VERSION ""

NS_ :

BS_:

BU_: Turbocharger OnBoardDataLogger OffBoardDiagnosticTool2 OffBoardDiagnosticTool1 FileServer ParkingBrakeController SeatControl2 FanDriveController SteeringColumnUnit CommunicationUnitRadio CommunicationUnitSatellite CommunicationUnitCellular PropulsionBatteryCharger ChassisController2 ChassisController1 EngineValveControl AuxiliaryHeater2 AuxiliaryHeater1 ClutchUnit RampControl InformationSystem1 SuspensionSystemController2 OilSensor VehicleDynamicStability ExhaustEmissionController TransmissionDisplay2 TransmissionDisplay1 ClimateControl2 WaterPumpController RearAxleSteeringController LightingOperatorControl SeatController1 IgnitionController2 IgnitionController1 TirePressureController CabController2 CabController1 PneumaticSystemController SuspensionSystemController1 HydraulicPumpController EnduranceBrakingSystem RetarderExhaustEngine2 OnBoardDiagnosticUnit HeadwayController RetarderExhaustEngine1 CabDisplay1 ManagementComputer VirtualTerminal OffVehicleGateway PowerTakeOffFront HitchControl AuxiliaryValveControl BodyController TractorTrailerBridge1 StarterSystem ElectricalSystem VehicleSecurity VehicleNavigation AerodynamicControl ElectricalChargingSystem ClimateControl1 TripRecorder InstrumentCluster SuspensionDriveAxle2 SuspensionDriveAxle1 SuspensionSteerAxle SteeringController FuelSystem CruiseControl RetarderDriveline RetarderEngine BrakesDriveAxle2 BrakesDriveAxle1 BrakesSystemController BrakesSteerAxle AxleDrive2 AxleDrive1 AxleSteering PowerTakeOff ShiftConsoleSecondary ShiftConsolePrimary Transmission2 Transmission1 Engine2 Engine1

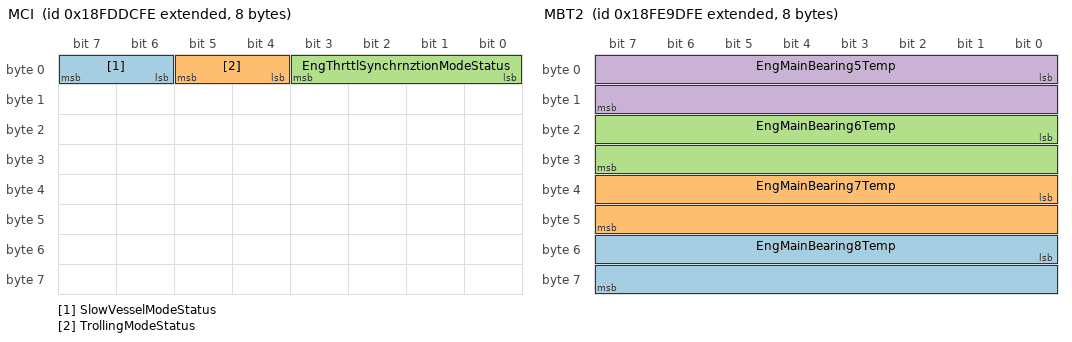
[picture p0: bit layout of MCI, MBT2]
BO_ 2566774014 MCI: 8 Vector__XXX
 SG_ SlowVesselModeStatus : 6|2@1+ (1,0) [0|3] "" Vector__XXX
 SG_ TrollingModeStatus : 4|2@1+ (1,0) [0|3] "" Vector__XXX
 SG_ EngThrttlSynchrnztionModeStatus : 0|4@1+ (1,0) [0|15] "" Vector__XXX

BO_ 2566823166 MBT3: 8 Vector__XXX
 SG_ EngMainBearing11Temp : 32|16@1+ (0.03125,-273) [-273|1734.96875] "deg C" Vector__XXX
 SG_ EngMainBearing10Temp : 16|16@1+ (0.03125,-273) [-273|1734.96875] "deg C" Vector__XXX
 SG_ EngMainBearing9Temp : 0|16@1+ (0.03125,-273) [-273|1734.96875] "deg C" Vector__XXX

BO_ 2566823422 MBT2: 8 Vector__XXX
 SG_ EngMainBearing8Temp : 48|16@1+ (0.03125,-273) [-273|1734.96875] "deg C" Vector__XXX
 SG_ EngMainBearing7Temp : 32|16@1+ (0.03125,-273) [-273|1734.96875] "deg C" Vector__XXX
 SG_ EngMainBearing6Temp : 16|16@1+ (0.03125,-273) [-273|1734.96875] "deg C" Vector__XXX
 SG_ EngMainBearing5Temp : 0|16@1+ (0.03125,-273) [-273|1734.96875] "deg C" Vector__XXX

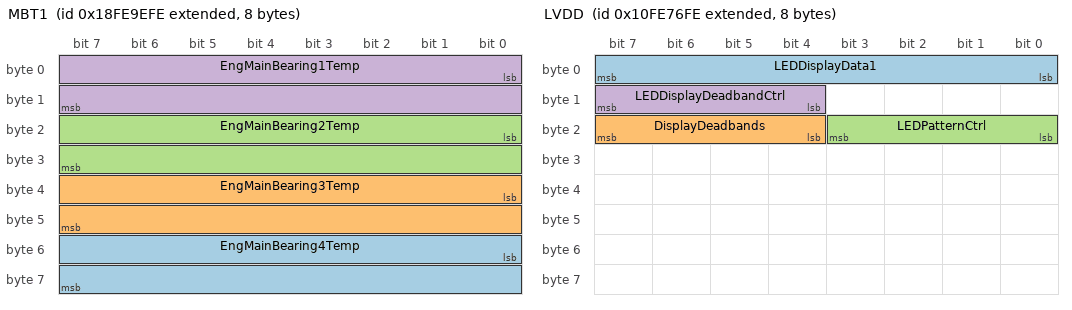
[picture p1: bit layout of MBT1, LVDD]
BO_ 2566823678 MBT1: 8 Vector__XXX
 SG_ EngMainBearing4Temp : 48|16@1+ (0.03125,-273) [-273|1734.96875] "deg C" Vector__XXX
 SG_ EngMainBearing3Temp : 32|16@1+ (0.03125,-273) [-273|1734.96875] "deg C" Vector__XXX
 SG_ EngMainBearing2Temp : 16|16@1+ (0.03125,-273) [-273|1734.96875] "deg C" Vector__XXX
 SG_ EngMainBearing1Temp : 0|16@1+ (0.03125,-273) [-273|1734.96875] "deg C" Vector__XXX

BO_ 2432595710 LVDD: 8 Vector__XXX
 SG_ LEDDisplayData1 : 0|8@1+ (1,0) [0|255] "" Vector__XXX
 SG_ DisplayDeadbands : 20|4@1+ (1,0) [0|15] "" Vector__XXX
 SG_ LEDPatternCtrl : 16|4@1+ (1,0) [0|15] "" Vector__XXX
 SG_ LEDDisplayDeadbandCtrl : 12|4@1+ (1,0) [0|15] "" Vector__XXX

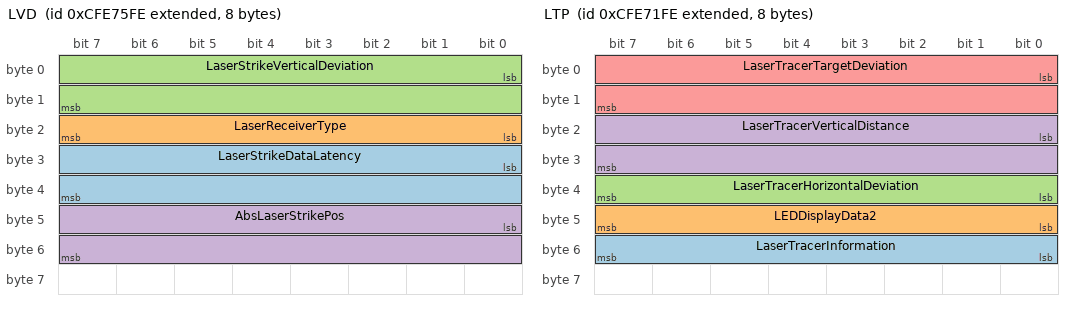
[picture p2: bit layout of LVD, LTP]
BO_ 2365486590 LVD: 8 Vector__XXX
 SG_ LaserStrikeDataLatency : 24|16@1+ (51.2,0) [0|3.289856] "s" Vector__XXX
 SG_ LaserReceiverType : 16|8@1+ (1,0) [0|250] "" Vector__XXX
 SG_ LaserStrikeVerticalDeviation : 0|16@1+ (0.1,-3200) [-3200|3225.5] "mm" Vector__XXX
 SG_ AbsLaserStrikePos : 40|16@1+ (0.1,0) [0|6425.5] "mm" Vector__XXX

BO_ 2365485566 LTP: 8 Vector__XXX
 SG_ LaserTracerInformation : 48|8@1+ (1,0) [0|255] "" Vector__XXX
 SG_ LEDDisplayData2 : 40|8@1+ (1,0) [0|255] "" Vector__XXX
 SG_ LaserTracerHorizontalDeviation : 32|8@1+ (1,0) [0|250] "%" Vector__XXX
 SG_ LaserTracerVerticalDistance : 16|16@1+ (0.1,0) [0|6425.5] "mm" Vector__XXX
 SG_ LaserTracerTargetDeviation : 0|16@1+ (0.1,-3200) [-3200|3225.5] "mm" Vector__XXX

BO_ 2365486334 LSP: 8 Vector__XXX
 SG_ BldHeightSetPointHighResolution : 16|32@1+ (100,-209.7152) [-209.7152|211.3929215] "m" Vector__XXX
 SG_ ModifyLevelingSystemSetPoint : 0|16@1+ (0.1,-3200) [-3200|3225.5] "mm" Vector__XXX

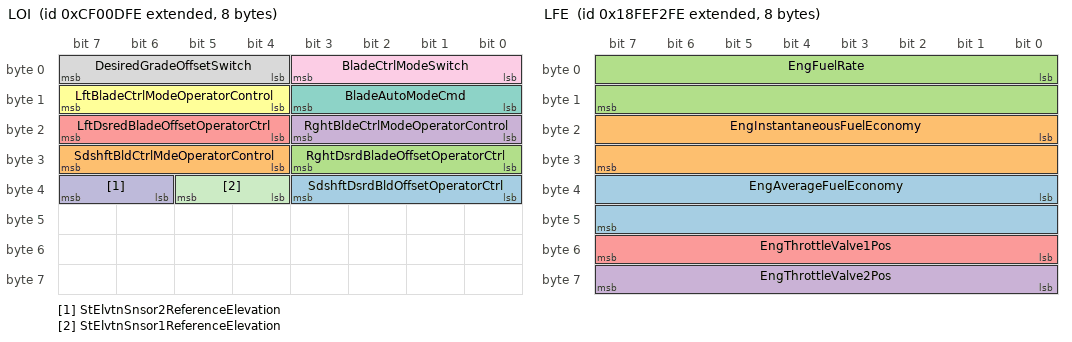
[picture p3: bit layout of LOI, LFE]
BO_ 2364542462 LOI: 8 Vector__XXX
 SG_ SdshftDsrdBldOffsetOperatorCtrl : 32|4@1+ (1,0) [0|15] "" Vector__XXX
 SG_ SdshftBldCtrlMdeOperatorControl : 28|4@1+ (1,0) [0|15] "" Vector__XXX
 SG_ RghtDsrdBladeOffsetOperatorCtrl : 24|4@1+ (1,0) [0|15] "" Vector__XXX
 SG_ RghtBldeCtrlModeOperatorControl : 16|4@1+ (1,0) [0|15] "" Vector__XXX
 SG_ LftDsredBladeOffsetOperatorCtrl : 20|4@1+ (1,0) [0|15] "" Vector__XXX
 SG_ LftBladeCtrlModeOperatorControl : 12|4@1+ (1,0) [0|15] "" Vector__XXX
 SG_ BladeAutoModeCmd : 8|4@1+ (1,0) [0|15] "" Vector__XXX
 SG_ DesiredGradeOffsetSwitch : 4|4@1+ (1,0) [0|15] "" Vector__XXX
 SG_ BladeCtrlModeSwitch : 0|4@1+ (1,0) [0|15] "" Vector__XXX
 SG_ StElvtnSnsor2ReferenceElevation : 38|2@1+ (1,0) [0|3] "" Vector__XXX
 SG_ StElvtnSnsor1ReferenceElevation : 36|2@1+ (1,0) [0|3] "" Vector__XXX

BO_ 2365486078 LMP: 8 Vector__XXX
 SG_ MastPos : 0|16@1+ (0.1,-3200) [-3200|3225.5] "mm" Vector__XXX

BO_ 2633937918 LFI: 8 Vector__XXX
 SG_ TotalEngPTOGovernorFuelUsed : 0|32@1+ (0.5,0) [0|2105540607.5] "L" Vector__XXX
 SG_ TripAverageFuelRate : 32|16@1+ (0.05,0) [0|3212.75] "L/h" Vector__XXX
 SG_ FlexibleFuelPercentage : 48|10@1+ (0.1,0) [0|102] "%" Vector__XXX

BO_ 2566845182 LFE: 8 Vector__XXX
 SG_ EngAverageFuelEconomy : 32|16@1+ (0.001953125,0) [0|125.5] "km/L" Vector__XXX
 SG_ EngInstantaneousFuelEconomy : 16|16@1+ (0.001953125,0) [0|125.5] "km/L" Vector__XXX
 SG_ EngFuelRate : 0|16@1+ (0.05,0) [0|3212.75] "L/h" Vector__XXX
 SG_ EngThrottleValve2Pos : 56|8@1+ (0.4,0) [0|100] "%" Vector__XXX
 SG_ EngThrottleValve1Pos : 48|8@1+ (0.4,0) [0|100] "%" Vector__XXX

BO_ 2566842878 LFC: 8 Vector__XXX
 SG_ EngTotalFuelUsed : 32|32@1+ (0.5,0) [0|2105540607.5] "L" Vector__XXX
 SG_ EngTripFuel : 0|32@1+ (0.5,0) [0|2105540607.5] "L" Vector__XXX

BO_ 2633883646 FWD: 8 Vector__XXX
 SG_ FrontWheelDriveActuatorStatus : 0|2@1+ (1,0) [0|3] "" Vector__XXX

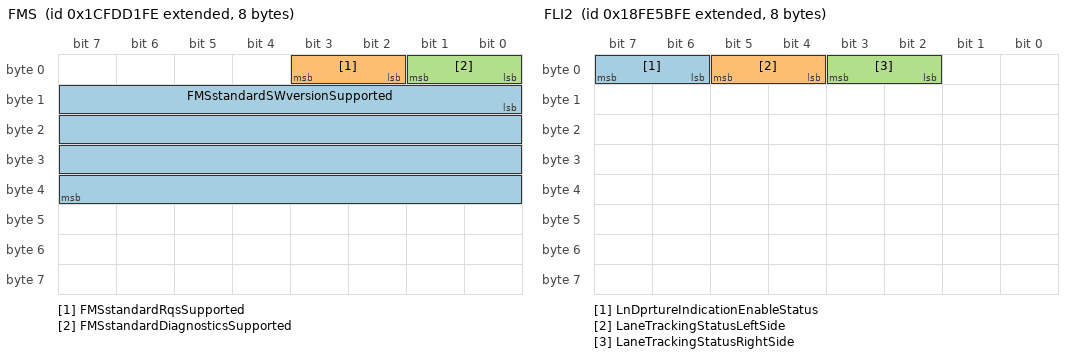
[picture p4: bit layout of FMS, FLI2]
BO_ 2633880062 FMS: 8 Vector__XXX
 SG_ FMSstandardSWversionSupported : 8|32@1+ (1,0) [0|255] "per" Vector__XXX
 SG_ FMSstandardRqsSupported : 2|2@1+ (1,0) [0|3] "" Vector__XXX
 SG_ FMSstandardDiagnosticsSupported : 0|2@1+ (1,0) [0|3] "" Vector__XXX

BO_ 2566806526 FLI2: 8 Vector__XXX
 SG_ LnDprtureIndicationEnableStatus : 6|2@1+ (1,0) [0|3] "" Vector__XXX
 SG_ LaneTrackingStatusLeftSide : 4|2@1+ (1,0) [0|3] "" Vector__XXX
 SG_ LaneTrackingStatusRightSide : 2|2@1+ (1,0) [0|3] "" Vector__XXX

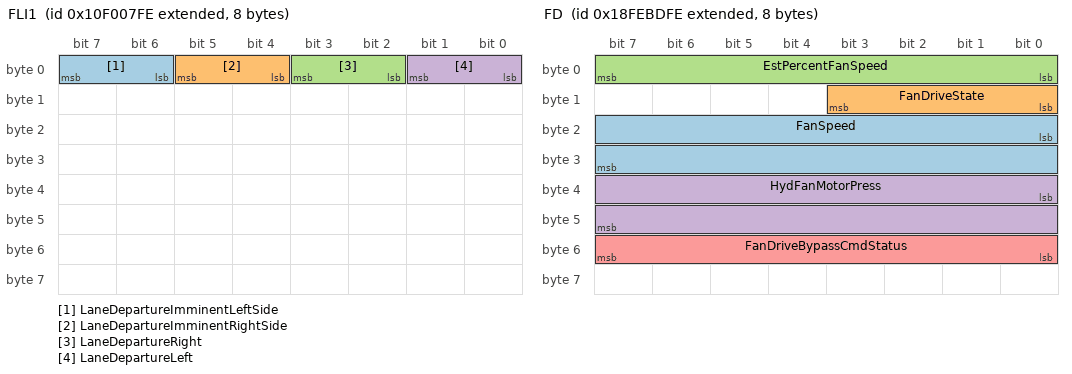
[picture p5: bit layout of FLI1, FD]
BO_ 2431649790 FLI1: 8 Vector__XXX
 SG_ LaneDepartureImminentLeftSide : 6|2@1+ (1,0) [0|3] "" Vector__XXX
 SG_ LaneDepartureImminentRightSide : 4|2@1+ (1,0) [0|3] "" Vector__XXX
 SG_ LaneDepartureRight : 2|2@1+ (1,0) [0|3] "" Vector__XXX
 SG_ LaneDepartureLeft : 0|2@1+ (1,0) [0|3] "" Vector__XXX

BO_ 2633929214 FL: 8 Vector__XXX
 SG_ EngFuelLeakage2 : 2|2@1+ (1,0) [0|3] "" Vector__XXX
 SG_ EngFuelLeakage1 : 0|2@1+ (1,0) [0|3] "" Vector__XXX

BO_ 2566831614 FD: 8 Vector__XXX
 SG_ FanSpeed : 16|16@1+ (0.125,0) [0|8031.875] "rpm" Vector__XXX
 SG_ FanDriveState : 8|4@1+ (1,0) [0|15] "" Vector__XXX
 SG_ EstPercentFanSpeed : 0|8@1+ (0.4,0) [0|100] "%" Vector__XXX
 SG_ HydFanMotorPress : 32|16@1+ (0.5,0) [0|32127.5] "kPa" Vector__XXX
 SG_ FanDriveBypassCmdStatus : 48|8@1+ (0.4,0) [0|100] "%" Vector__XXX

BO_ 2364542206 ETC8: 8 Vector__XXX
 SG_ TransClutch_ConverterInputSpeed : 16|16@1+ (0.125,0) [0|8031.875] "rpm" Vector__XXX
 SG_ TransTorqueConverterRatio : 0|16@1+ (0.001,0) [0|64.255] "" Vector__XXX

BO_ 2566802174 ETC7: 8 Vector__XXX
 SG_ TrnsRvrseGearShiftInhibitStatus : 40|2@1+ (1,0) [0|3] "" Vector__XXX
 SG_ TrnsCrrntRangeDisplayBlankState : 0|2@1+ (1,0) [0|3] "" Vector__XXX
 SG_ TransWarningIndicator : 42|2@1+ (1,0) [0|3] "" Vector__XXX
 SG_ TransMode8Indicator : 38|2@1+ (1,0) [0|3] "" Vector__XXX
 SG_ TransMode7Indicator : 36|2@1+ (1,0) [0|3] "" Vector__XXX
 SG_ TransMode6Indicator : 34|2@1+ (1,0) [0|3] "" Vector__XXX
 SG_ TransMode5Indicator : 32|2@1+ (1,0) [0|3] "" Vector__XXX
 SG_ TransRqedGearFeedback : 24|8@1+ (1,-125) [-125|125] "" Vector__XXX
 SG_ TransMode1Indicator : 22|2@1+ (1,0) [0|3] "" Vector__XXX
 SG_ TransMode2Indicator : 20|2@1+ (1,0) [0|3] "" Vector__XXX
 SG_ TransMode3Indicator : 18|2@1+ (1,0) [0|3] "" Vector__XXX
 SG_ TransMode4Indicator : 16|2@1+ (1,0) [0|3] "" Vector__XXX
 SG_ TransShiftInhibitIndicator : 14|2@1+ (1,0) [0|3] "" Vector__XXX
 SG_ TransEngCrankEnable : 12|2@1+ (1,0) [0|3] "" Vector__XXX
 SG_ ActiveShiftConsoleIndicator : 10|2@1+ (1,0) [0|3] "" Vector__XXX
 SG_ TransReadyForBrakeRelease : 8|2@1+ (1,0) [0|3] "" Vector__XXX
 SG_ TransRqedRangeDisplayFlashState : 6|2@1+ (1,0) [0|3] "" Vector__XXX
 SG_ TransRqedRangeDisplayBlankState : 4|2@1+ (1,0) [0|3] "" Vector__XXX
 SG_ TransServiceIndicator : 2|2@1+ (1,0) [0|3] "" Vector__XXX

BO_ 2633935870 ETC6: 8 Vector__XXX
 SG_ ClutchLifeRemaining : 24|8@1+ (0.4,0) [0|100] "%" Vector__XXX
 SG_ LowestPossibleGear : 16|8@1+ (1,-125) [-125|125] "" Vector__XXX
 SG_ HighestPossibleGear : 8|8@1+ (1,-125) [-125|125] "" Vector__XXX
 SG_ RecommendedGear : 0|8@1+ (1,-125) [-125|125] "" Vector__XXX

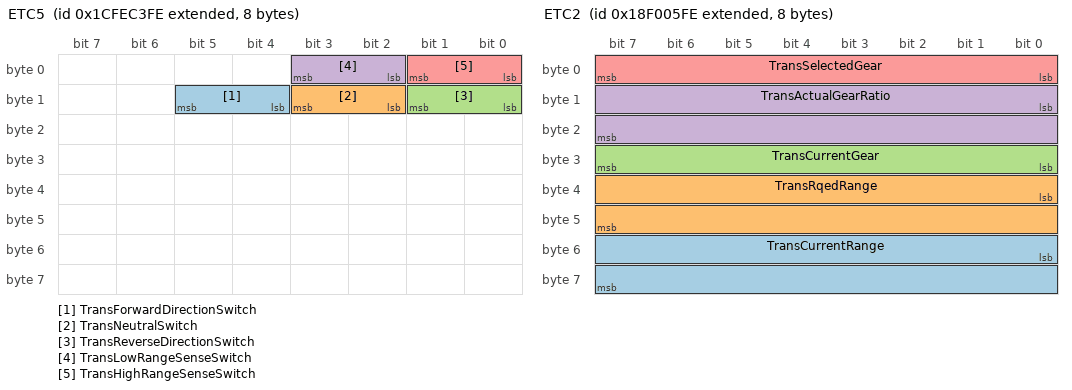
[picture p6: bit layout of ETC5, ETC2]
BO_ 2633942014 ETC5: 8 Vector__XXX
 SG_ TransForwardDirectionSwitch : 12|2@1+ (1,0) [0|3] "" Vector__XXX
 SG_ TransNeutralSwitch : 10|2@1+ (1,0) [0|3] "" Vector__XXX
 SG_ TransReverseDirectionSwitch : 8|2@1+ (1,0) [0|3] "" Vector__XXX
 SG_ TransLowRangeSenseSwitch : 2|2@1+ (1,0) [0|3] "" Vector__XXX
 SG_ TransHighRangeSenseSwitch : 0|2@1+ (1,0) [0|3] "" Vector__XXX

BO_ 2633942526 ETC4: 8 Vector__XXX
 SG_ TransSynchronizerBrakeValue : 8|8@1+ (0.4,0) [0|100] "%" Vector__XXX
 SG_ TransSynchronizerClutchValue : 0|8@1+ (0.4,0) [0|100] "%" Vector__XXX

BO_ 2633943038 ETC3: 8 Vector__XXX
 SG_ TransInertiaBrakeActuator : 46|2@1+ (1,0) [0|3] "" Vector__XXX
 SG_ TransDefuelActuator : 44|2@1+ (1,0) [0|3] "" Vector__XXX
 SG_ TransLockupClutchActuator : 42|2@1+ (1,0) [0|3] "" Vector__XXX
 SG_ TransClutchActuator : 40|2@1+ (1,0) [0|3] "" Vector__XXX
 SG_ TransSplitterIndirectActuator : 38|2@1+ (1,0) [0|3] "" Vector__XXX
 SG_ TransSplitterDirectActuator : 36|2@1+ (1,0) [0|3] "" Vector__XXX
 SG_ TransRangeLowActuator : 34|2@1+ (1,0) [0|3] "" Vector__XXX
 SG_ TransRangeHighActuator : 32|2@1+ (1,0) [0|3] "" Vector__XXX
 SG_ TransShiftFingerGearActuator2 : 30|2@1+ (1,0) [0|3] "" Vector__XXX
 SG_ TransShiftFingerRailActuator2 : 28|2@1+ (1,0) [0|3] "" Vector__XXX
 SG_ TransShiftFingerGearActuator1 : 26|2@1+ (1,0) [0|3] "" Vector__XXX
 SG_ TransShiftFingerRailActuator1 : 24|2@1+ (1,0) [0|3] "" Vector__XXX
 SG_ TrnsShftFngrCenterRailIndicator : 20|2@1+ (1,0) [0|3] "" Vector__XXX
 SG_ TrnsShftFngrEngagementIndicator : 18|2@1+ (1,0) [0|3] "" Vector__XXX
 SG_ TrnsShiftFingerNeutralIndicator : 16|2@1+ (1,0) [0|3] "" Vector__XXX
 SG_ TransShiftFingerRailPos : 8|8@1+ (0.4,0) [0|100] "%" Vector__XXX
 SG_ TransShiftFingerGearPos : 0|8@1+ (0.4,0) [0|100] "%" Vector__XXX

BO_ 2565867006 ETC2: 8 Vector__XXX
 SG_ TransCurrentRange : 48|16@1+ (1,0) [0|255] "" Vector__XXX
 SG_ TransRqedRange : 32|16@1+ (1,0) [0|255] "per" Vector__XXX
 SG_ TransCurrentGear : 24|8@1+ (1,-125) [-125|125] "" Vector__XXX
 SG_ TransActualGearRatio : 8|16@1+ (0.001,0) [0|64.255] "" Vector__XXX
 SG_ TransSelectedGear : 0|8@1+ (1,-125) [-125|125] "" Vector__XXX

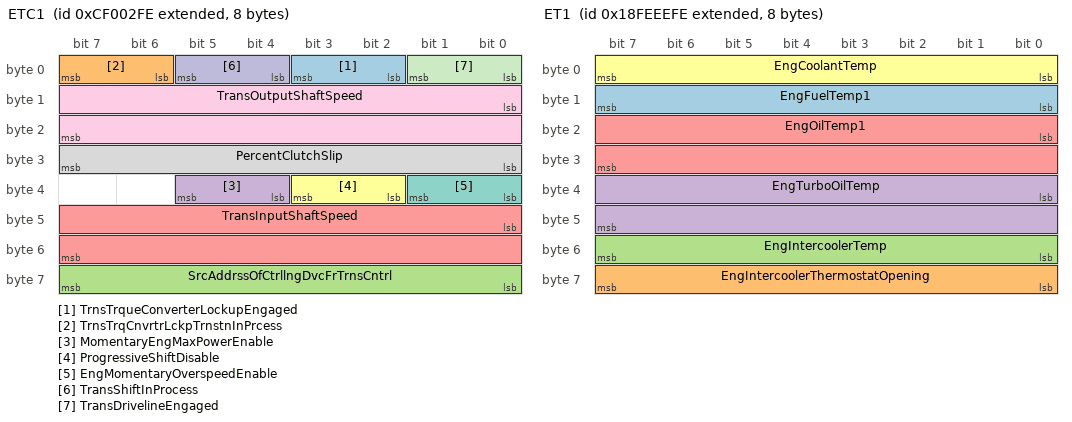
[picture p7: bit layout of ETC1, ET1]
BO_ 2364539646 ETC1: 8 Vector__XXX
 SG_ TrnsTrqueConverterLockupEngaged : 2|2@1+ (1,0) [0|3] "" Vector__XXX
 SG_ TrnsTrqCnvrtrLckpTrnstnInPrcess : 6|2@1+ (1,0) [0|3] "" Vector__XXX
 SG_ SrcAddrssOfCtrllngDvcFrTrnsCntrl : 56|8@1+ (1,0) [0|255] "" Vector__XXX
 SG_ MomentaryEngMaxPowerEnable : 36|2@1+ (1,0) [0|3] "" Vector__XXX
 SG_ TransInputShaftSpeed : 40|16@1+ (0.125,0) [0|8031.875] "rpm" Vector__XXX
 SG_ ProgressiveShiftDisable : 34|2@1+ (1,0) [0|3] "" Vector__XXX
 SG_ EngMomentaryOverspeedEnable : 32|2@1+ (1,0) [0|3] "" Vector__XXX
 SG_ PercentClutchSlip : 24|8@1+ (0.4,0) [0|100] "%" Vector__XXX
 SG_ TransOutputShaftSpeed : 8|16@1+ (0.125,0) [0|8031.875] "rpm" Vector__XXX
 SG_ TransShiftInProcess : 4|2@1+ (1,0) [0|3] "" Vector__XXX
 SG_ TransDrivelineEngaged : 0|2@1+ (1,0) [0|3] "" Vector__XXX

BO_ 2566810110 ET3: 8 Vector__XXX
 SG_ EngChargeAirCooler1OutletTemp : 48|16@1+ (0.03125,-273) [-273|1734.96875] "deg C" Vector__XXX
 SG_ EngIntkVlvActationSystemOilTemp : 32|16@1+ (0.03125,-273) [-273|1734.96875] "deg C" Vector__XXX
 SG_ EngIntakeManifold1AirTemp : 0|16@1+ (0.03125,-273) [-273|1734.96875] "deg C" Vector__XXX
 SG_ EngCoolantTempHiRes : 16|16@1+ (0.03125,-273) [-273|1734.96875] "deg C" Vector__XXX

BO_ 2566825214 ET2: 8 Vector__XXX
 SG_ EngExhstGsRcrculation1DiffPress : 32|16@1+ (0.0078125,-250) [-250|251.99] "kPa" Vector__XXX
 SG_ EngExhaustGasRecirculation1Temp : 48|16@1+ (0.03125,-273) [-273|1734.96875] "deg C" Vector__XXX
 SG_ EngECUTemp : 16|16@1+ (0.03125,-273) [-273|1734.96875] "deg C" Vector__XXX
 SG_ EngOilTemp2 : 0|16@1+ (0.03125,-273) [-273|1734.96875] "deg C" Vector__XXX

BO_ 2566844158 ET1: 8 Vector__XXX
 SG_ EngFuelTemp1 : 8|8@1+ (1,-40) [-40|210] "deg C" Vector__XXX
 SG_ EngIntercoolerThermostatOpening : 56|8@1+ (0.4,0) [0|100] "%" Vector__XXX
 SG_ EngIntercoolerTemp : 48|8@1+ (1,-40) [-40|210] "deg C" Vector__XXX
 SG_ EngTurboOilTemp : 32|16@1+ (0.03125,-273) [-273|1734.96875] "deg C" Vector__XXX
 SG_ EngOilTemp1 : 16|16@1+ (0.03125,-273) [-273|1734.96875] "deg C" Vector__XXX
 SG_ EngCoolantTemp : 0|8@1+ (0.03125,-273) [-273|-265.03125] "deg C" Vector__XXX

BO_ 2566785022 ET: 8 Vector__XXX
 SG_ EngExhaustGasTempRightManifold : 0|16@1+ (0.03125,-273) [-273|1734.96875] "deg C" Vector__XXX
 SG_ EngExhaustGasTempLeftManifold : 16|16@1+ (0.03125,-273) [-273|1734.96875] "deg C" Vector__XXX

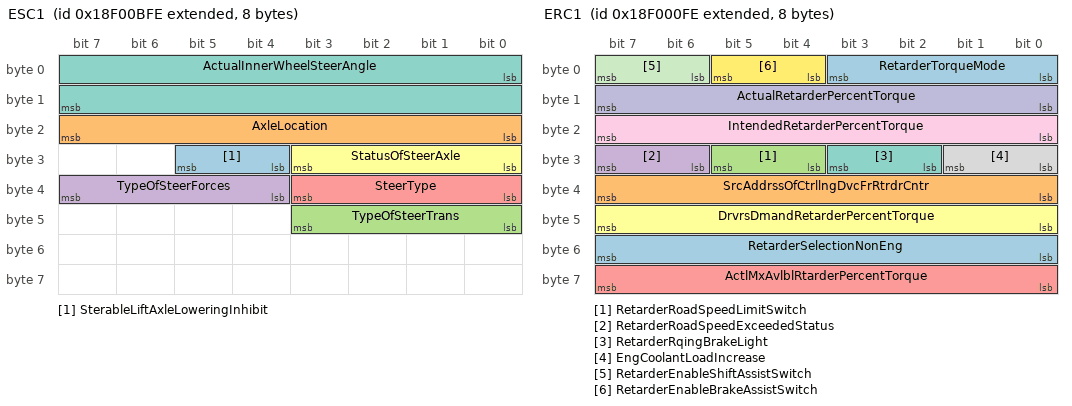
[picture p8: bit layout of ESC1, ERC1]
BO_ 2565868542 ESC1: 8 Vector__XXX
 SG_ SterableLiftAxleLoweringInhibit : 28|2@1+ (1,0) [0|3] "" Vector__XXX
 SG_ AxleLocation : 16|8@1+ (1,0) [0|255] "" Vector__XXX
 SG_ TypeOfSteerTrans : 40|4@1+ (1,0) [0|15] "" Vector__XXX
 SG_ TypeOfSteerForces : 36|4@1+ (1,0) [0|15] "" Vector__XXX
 SG_ SteerType : 32|4@1+ (1,0) [0|15] "" Vector__XXX
 SG_ StatusOfSteerAxle : 24|4@1+ (1,0) [0|15] "" Vector__XXX
 SG_ ActualInnerWheelSteerAngle : 0|16@1+ (0.00390625,-125) [-125|125] "deg" Vector__XXX

BO_ 2633941758 ERC2: 8 Vector__XXX
 SG_ TransOutputRetarder : 0|2@1+ (1,0) [0|3] "" Vector__XXX

BO_ 2565865726 ERC1: 8 Vector__XXX
 SG_ RetarderSelectionNonEng : 48|8@1+ (0.4,0) [0|100] "%" Vector__XXX
 SG_ SrcAddrssOfCtrllngDvcFrRtrdrCntr : 32|8@1+ (1,0) [0|255] "" Vector__XXX
 SG_ RetarderRoadSpeedLimitSwitch : 28|2@1+ (1,0) [0|3] "" Vector__XXX
 SG_ RetarderRoadSpeedExceededStatus : 30|2@1+ (1,0) [0|3] "" Vector__XXX
 SG_ ActlMxAvlblRtarderPercentTorque : 56|8@1+ (1,-125) [-125|125] "%" Vector__XXX
 SG_ DrvrsDmandRetarderPercentTorque : 40|8@1+ (1,-125) [-125|125] "%" Vector__XXX
 SG_ RetarderRqingBrakeLight : 26|2@1+ (1,0) [0|3] "" Vector__XXX
 SG_ EngCoolantLoadIncrease : 24|2@1+ (1,0) [0|3] "" Vector__XXX
 SG_ IntendedRetarderPercentTorque : 16|8@1+ (1,-125) [-125|125] "%" Vector__XXX
 SG_ ActualRetarderPercentTorque : 8|8@1+ (1,-125) [-125|125] "%" Vector__XXX
 SG_ RetarderEnableShiftAssistSwitch : 6|2@1+ (1,0) [0|3] "" Vector__XXX
 SG_ RetarderEnableBrakeAssistSwitch : 4|2@1+ (1,0) [0|3] "" Vector__XXX
 SG_ RetarderTorqueMode : 0|4@1+ (1,0) [0|15] "" Vector__XXX

BO_ 2633932798 EPT5: 8 Vector__XXX
 SG_ EngExhaustGasPort20Temp : 48|16@1+ (0.03125,-273) [-273|1734.96875] "deg C" Vector__XXX
 SG_ EngExhaustGasPort19Temp : 32|16@1+ (0.03125,-273) [-273|1734.96875] "deg C" Vector__XXX
 SG_ EngExhaustGasPort18Temp : 16|16@1+ (0.03125,-273) [-273|1734.96875] "deg C" Vector__XXX
 SG_ EngExhaustGasPort17Temp : 0|16@1+ (0.03125,-273) [-273|1734.96875] "deg C" Vector__XXX

BO_ 2566824190 EPT4: 8 Vector__XXX
 SG_ EngExhaustGasPort16Temp : 48|16@1+ (0.03125,-273) [-273|1734.96875] "deg C" Vector__XXX
 SG_ EngExhaustGasPort15Temp : 32|16@1+ (0.03125,-273) [-273|1734.96875] "deg C" Vector__XXX
 SG_ EngExhaustGasPort14Temp : 16|16@1+ (0.03125,-273) [-273|1734.96875] "deg C" Vector__XXX
 SG_ EngExhaustGasPort13Temp : 0|16@1+ (0.03125,-273) [-273|1734.96875] "deg C" Vector__XXX

BO_ 2633933310 EPT3: 8 Vector__XXX
 SG_ EngExhaustGasPort12Temp : 48|16@1+ (0.03125,-273) [-273|1734.96875] "deg C" Vector__XXX
 SG_ EngExhaustGasPort11Temp : 32|16@1+ (0.03125,-273) [-273|1734.96875] "deg C" Vector__XXX
 SG_ EngExhaustGasPort10Temp : 16|16@1+ (0.03125,-273) [-273|1734.96875] "deg C" Vector__XXX
 SG_ EngExhaustGasPort9Temp : 0|16@1+ (0.03125,-273) [-273|1734.96875] "deg C" Vector__XXX

BO_ 2633933566 EPT2: 8 Vector__XXX
 SG_ EngExhaustGasPort8Temp : 48|16@1+ (0.03125,-273) [-273|1734.96875] "deg C" Vector__XXX
 SG_ EngExhaustGasPort7Temp : 32|16@1+ (0.03125,-273) [-273|1734.96875] "deg C" Vector__XXX
 SG_ EngExhaustGasPort6Temp : 16|16@1+ (0.03125,-273) [-273|1734.96875] "deg C" Vector__XXX
 SG_ EngExhaustGasPort5Temp : 0|16@1+ (0.03125,-273) [-273|1734.96875] "deg C" Vector__XXX

BO_ 2633933822 EPT1: 8 Vector__XXX
 SG_ EngExhaustGasPort4Temp : 48|16@1+ (0.03125,-273) [-273|1734.96875] "deg C" Vector__XXX
 SG_ EngExhaustGasPort3Temp : 32|16@1+ (0.03125,-273) [-273|1734.96875] "deg C" Vector__XXX
 SG_ EngExhaustGasPort2Temp : 16|16@1+ (0.03125,-273) [-273|1734.96875] "deg C" Vector__XXX
 SG_ EngExhaustGasPort1Temp : 0|16@1+ (0.03125,-273) [-273|1734.96875] "deg C" Vector__XXX

BO_ 2566776062 EPD: 8 Vector__XXX
 SG_ PayloadPercentage : 0|8@1+ (1,0) [0|250] "%" Vector__XXX

BO_ 2566771454 EP: 8 Vector__XXX
 SG_ DataMemoryUsage : 16|8@1+ (0.4,0) [0|100] "%" Vector__XXX
 SG_ KeepAliveBatteryConsumption : 0|16@1+ (1,0) [0|64255] "mAhr" Vector__XXX

BO_ 2566775806 EOAC: 8 Vector__XXX
 SG_ TravelVelocityCtrlPos : 0|8@1+ (1,-125) [-125|125] "%" Vector__XXX

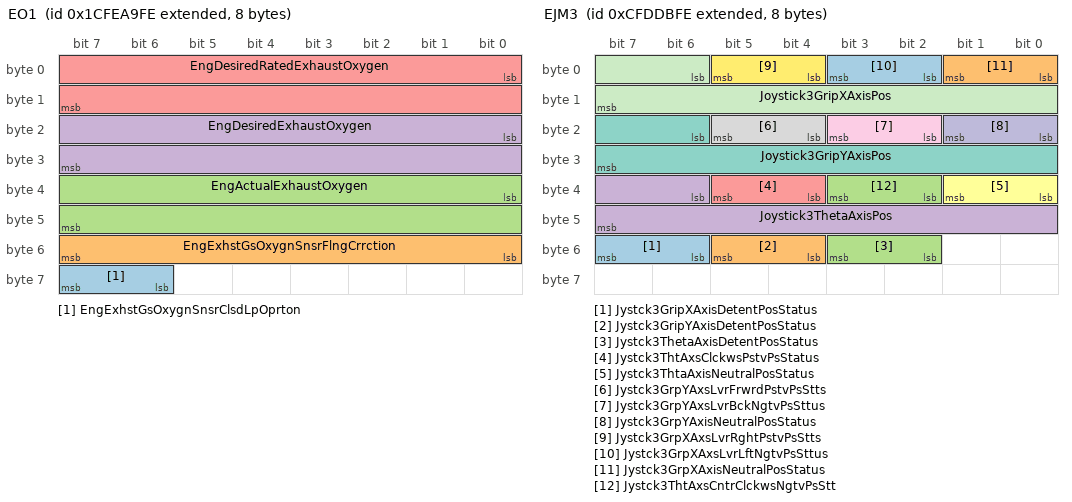
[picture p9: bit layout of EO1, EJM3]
BO_ 2633935358 EO1: 8 Vector__XXX
 SG_ EngExhstGsOxygnSnsrClsdLpOprton : 62|2@1+ (1,0) [0|3] "" Vector__XXX
 SG_ EngExhstGsOxygnSnsrFlngCrrction : 48|8@1+ (1,-125) [-125|125] "%" Vector__XXX
 SG_ EngActualExhaustOxygen : 32|16@1+ (0.0025,0) [0|160.6375] "%" Vector__XXX
 SG_ EngDesiredExhaustOxygen : 16|16@1+ (0.0025,0) [0|160.6375] "%" Vector__XXX
 SG_ EngDesiredRatedExhaustOxygen : 0|16@1+ (0.0025,0) [0|160.6375] "%" Vector__XXX

BO_ 2365447166 EJM3: 8 Vector__XXX
 SG_ Jystck3GripXAxisDetentPosStatus : 54|2@1+ (1,0) [0|3] "" Vector__XXX
 SG_ Jystck3GripYAxisDetentPosStatus : 52|2@1+ (1,0) [0|3] "" Vector__XXX
 SG_ Jystck3ThetaAxisDetentPosStatus : 50|2@1+ (1,0) [0|3] "" Vector__XXX
 SG_ Joystick3ThetaAxisPos : 38|10@1+ (0.1,0) [0|102] "%" Vector__XXX
 SG_ Jystck3ThtAxsClckwsPstvPsStatus : 36|2@1+ (1,0) [0|3] "" Vector__XXX
 SG_ Jystck3ThtaAxisNeutralPosStatus : 32|2@1+ (1,0) [0|3] "" Vector__XXX
 SG_ Joystick3GripYAxisPos : 22|10@1+ (0.1,0) [0|102] "%" Vector__XXX
 SG_ Jystck3GrpYAxsLvrFrwrdPstvPsStts : 20|2@1+ (1,0) [0|3] "" Vector__XXX
 SG_ Jystck3GrpYAxsLvrBckNgtvPsSttus : 18|2@1+ (1,0) [0|3] "" Vector__XXX
 SG_ Jystck3GrpYAxisNeutralPosStatus : 16|2@1+ (1,0) [0|3] "" Vector__XXX
 SG_ Joystick3GripXAxisPos : 6|10@1+ (0.1,0) [0|102] "%" Vector__XXX
 SG_ Jystck3GrpXAxsLvrRghtPstvPsStts : 4|2@1+ (1,0) [0|3] "" Vector__XXX
 SG_ Jystck3GrpXAxsLvrLftNgtvPsSttus : 2|2@1+ (1,0) [0|3] "" Vector__XXX
 SG_ Jystck3GrpXAxisNeutralPosStatus : 0|2@1+ (1,0) [0|3] "" Vector__XXX
 SG_ Jystck3ThtAxsCntrClckwsNgtvPsStt : 34|2@1+ (1,0) [0|3] "" Vector__XXX

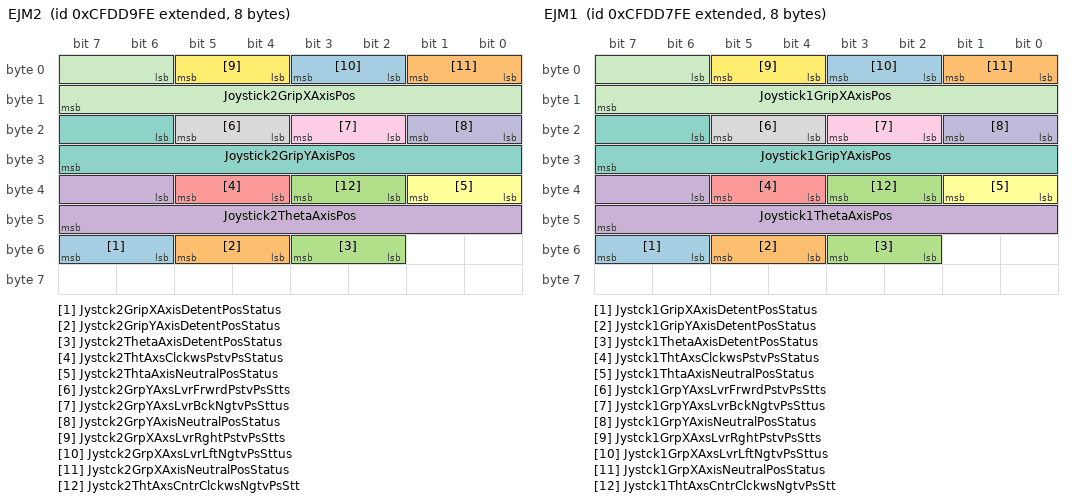
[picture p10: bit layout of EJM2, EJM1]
BO_ 2365446654 EJM2: 8 Vector__XXX
 SG_ Jystck2GripXAxisDetentPosStatus : 54|2@1+ (1,0) [0|3] "" Vector__XXX
 SG_ Jystck2GripYAxisDetentPosStatus : 52|2@1+ (1,0) [0|3] "" Vector__XXX
 SG_ Jystck2ThetaAxisDetentPosStatus : 50|2@1+ (1,0) [0|3] "" Vector__XXX
 SG_ Joystick2ThetaAxisPos : 38|10@1+ (0.1,0) [0|102] "%" Vector__XXX
 SG_ Jystck2ThtAxsClckwsPstvPsStatus : 36|2@1+ (1,0) [0|3] "" Vector__XXX
 SG_ Jystck2ThtaAxisNeutralPosStatus : 32|2@1+ (1,0) [0|3] "" Vector__XXX
 SG_ Joystick2GripYAxisPos : 22|10@1+ (0.1,0) [0|102] "%" Vector__XXX
 SG_ Jystck2GrpYAxsLvrFrwrdPstvPsStts : 20|2@1+ (1,0) [0|3] "" Vector__XXX
 SG_ Jystck2GrpYAxsLvrBckNgtvPsSttus : 18|2@1+ (1,0) [0|3] "" Vector__XXX
 SG_ Jystck2GrpYAxisNeutralPosStatus : 16|2@1+ (1,0) [0|3] "" Vector__XXX
 SG_ Joystick2GripXAxisPos : 6|10@1+ (0.1,0) [0|102] "%" Vector__XXX
 SG_ Jystck2GrpXAxsLvrRghtPstvPsStts : 4|2@1+ (1,0) [0|3] "" Vector__XXX
 SG_ Jystck2GrpXAxsLvrLftNgtvPsSttus : 2|2@1+ (1,0) [0|3] "" Vector__XXX
 SG_ Jystck2GrpXAxisNeutralPosStatus : 0|2@1+ (1,0) [0|3] "" Vector__XXX
 SG_ Jystck2ThtAxsCntrClckwsNgtvPsStt : 34|2@1+ (1,0) [0|3] "" Vector__XXX

BO_ 2365446142 EJM1: 8 Vector__XXX
 SG_ Jystck1GripXAxisDetentPosStatus : 54|2@1+ (1,0) [0|3] "" Vector__XXX
 SG_ Jystck1GripYAxisDetentPosStatus : 52|2@1+ (1,0) [0|3] "" Vector__XXX
 SG_ Jystck1ThetaAxisDetentPosStatus : 50|2@1+ (1,0) [0|3] "" Vector__XXX
 SG_ Joystick1ThetaAxisPos : 38|10@1+ (0.1,0) [0|102] "%" Vector__XXX
 SG_ Jystck1ThtAxsClckwsPstvPsStatus : 36|2@1+ (1,0) [0|3] "" Vector__XXX
 SG_ Jystck1ThtaAxisNeutralPosStatus : 32|2@1+ (1,0) [0|3] "" Vector__XXX
 SG_ Joystick1GripYAxisPos : 22|10@1+ (0.1,0) [0|102] "%" Vector__XXX
 SG_ Jystck1GrpYAxsLvrFrwrdPstvPsStts : 20|2@1+ (1,0) [0|3] "" Vector__XXX
 SG_ Jystck1GrpYAxsLvrBckNgtvPsSttus : 18|2@1+ (1,0) [0|3] "" Vector__XXX
 SG_ Jystck1GrpYAxisNeutralPosStatus : 16|2@1+ (1,0) [0|3] "" Vector__XXX
 SG_ Joystick1GripXAxisPos : 6|10@1+ (0.1,0) [0|102] "%" Vector__XXX
 SG_ Jystck1GrpXAxsLvrRghtPstvPsStts : 4|2@1+ (1,0) [0|3] "" Vector__XXX
 SG_ Jystck1GrpXAxsLvrLftNgtvPsSttus : 2|2@1+ (1,0) [0|3] "" Vector__XXX
 SG_ Jystck1GrpXAxisNeutralPosStatus : 0|2@1+ (1,0) [0|3] "" Vector__XXX
 SG_ Jystck1ThtAxsCntrClckwsNgtvPsStt : 34|2@1+ (1,0) [0|3] "" Vector__XXX

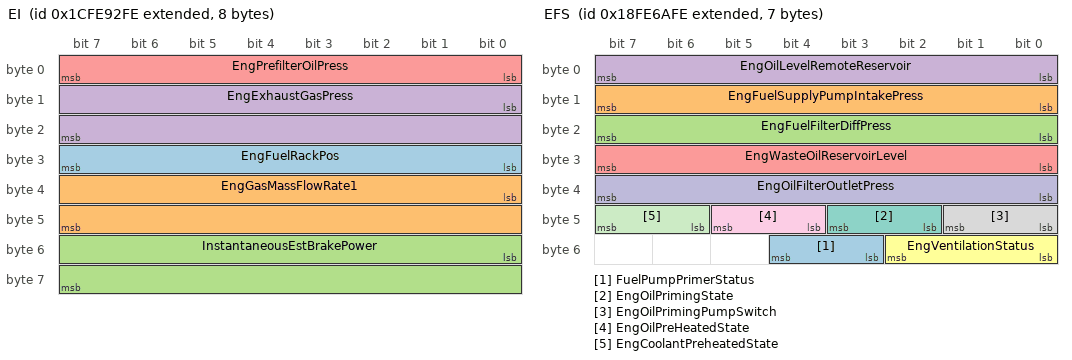
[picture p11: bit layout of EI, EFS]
BO_ 2633929470 EI: 8 Vector__XXX
 SG_ EngFuelRackPos : 24|8@1+ (0.4,0) [0|100] "%" Vector__XXX
 SG_ EngGasMassFlowRate1 : 32|16@1+ (0.05,0) [0|3212.75] "kg/h" Vector__XXX
 SG_ InstantaneousEstBrakePower : 48|16@1+ (0.5,0) [0|32127.5] "kW" Vector__XXX
 SG_ EngExhaustGasPress : 8|16@1+ (0.0078125,-250) [-250|251.99] "kPa" Vector__XXX
 SG_ EngPrefilterOilPress : 0|8@1+ (4,0) [0|1000] "kPa" Vector__XXX

BO_ 2633937406 EH: 8 Vector__XXX
 SG_ TotalECURunTime : 32|32@1+ (0.05,0) [0|210554060.75] "hr" Vector__XXX
 SG_ TotalECUDistance : 0|32@1+ (0.125,0) [0|526385151.9] "km" Vector__XXX

BO_ 2364541694 EGF1: 8 Vector__XXX
 SG_ EngIntakeAirMassFlowRate : 16|16@1+ (0.05,0) [0|3212.75] "kg/h" Vector__XXX
 SG_ EngExhstGsRcrclton2MassFlowRate : 32|16@1+ (0.05,0) [0|3212.75] "kg/h" Vector__XXX
 SG_ EngExhstGsRcrclton1MassFlowRate : 0|16@1+ (0.05,0) [0|3212.75] "kg/h" Vector__XXX

BO_ 2566810366 EFS: 7 Vector__XXX
 SG_ FuelPumpPrimerStatus : 51|2@1+ (1,0) [0|3] "" Vector__XXX
 SG_ EngFuelSupplyPumpIntakePress : 8|8@1+ (2,0) [0|500] "kPa" Vector__XXX
 SG_ EngFuelFilterDiffPress : 16|8@1+ (2,0) [0|500] "kPa" Vector__XXX
 SG_ EngOilLevelRemoteReservoir : 0|8@1+ (0.4,0) [0|100] "%" Vector__XXX
 SG_ EngWasteOilReservoirLevel : 24|8@1+ (0.4,0) [0|100] "%" Vector__XXX
 SG_ EngVentilationStatus : 48|3@1+ (1,0) [0|7] "" Vector__XXX
 SG_ EngOilPrimingState : 42|2@1+ (1,0) [0|3] "" Vector__XXX
 SG_ EngOilPrimingPumpSwitch : 40|2@1+ (1,0) [0|3] "" Vector__XXX
 SG_ EngOilPreHeatedState : 44|2@1+ (1,0) [0|3] "" Vector__XXX
 SG_ EngOilFilterOutletPress : 32|8@1+ (4,0) [0|1000] "kPa" Vector__XXX
 SG_ EngCoolantPreheatedState : 46|2@1+ (1,0) [0|3] "" Vector__XXX

BO_ 2566767102 EFL_P3: 8 Vector__XXX
 SG_ EngExhstVlvActtonSystemOilPress : 24|16@1+ (0.00390625,0) [0|251] "MPa" Vector__XXX
 SG_ EngExhstGsRcrcltion1OutletPress : 40|8@1+ (2,0) [0|500] "kPa" Vector__XXX
 SG_ EngExhstGsRcrcltion1IntakePress : 16|8@1+ (2,0) [0|500] "kPa" Vector__XXX
 SG_ EngIntkVlvActtionSystemOilPress : 0|16@1+ (0.00390625,0) [0|251] "MPa" Vector__XXX

BO_ 2566839294 EFL_P2: 8 Vector__XXX
 SG_ EngInjectorMeteringRail2Press : 48|16@1+ (0.00390625,0) [0|251] "MPa" Vector__XXX
 SG_ EngInjectorTimingRail1Press : 32|16@1+ (0.00390625,0) [0|251] "MPa" Vector__XXX
 SG_ EngInjectorMeteringRail1Press : 16|16@1+ (0.00390625,0) [0|251] "MPa" Vector__XXX
 SG_ EngInjectionCtrlPress : 0|16@1+ (0.00390625,0) [0|251] "MPa" Vector__XXX

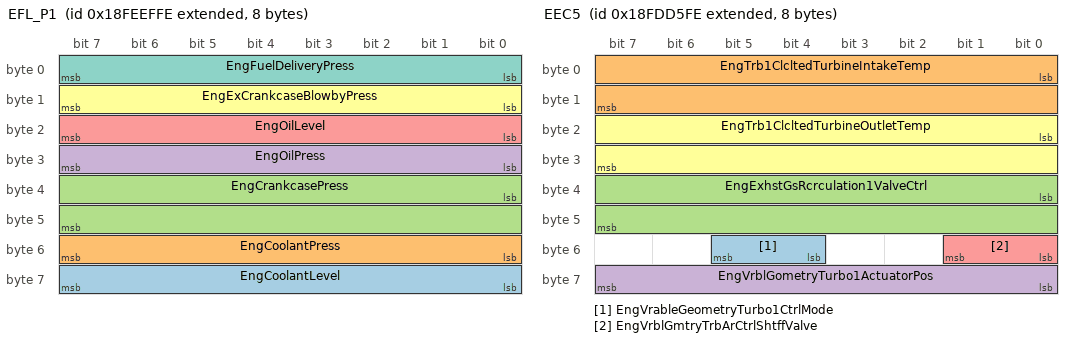
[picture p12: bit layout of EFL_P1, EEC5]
BO_ 2566844414 EFL_P1: 8 Vector__XXX
 SG_ EngCoolantLevel : 56|8@1+ (0.4,0) [0|100] "%" Vector__XXX
 SG_ EngCoolantPress : 48|8@1+ (2,0) [0|500] "kPa" Vector__XXX
 SG_ EngCrankcasePress : 32|16@1+ (0.0078125,-250) [-250|251.99] "kPa" Vector__XXX
 SG_ EngOilPress : 24|8@1+ (4,0) [0|1000] "kPa" Vector__XXX
 SG_ EngOilLevel : 16|8@1+ (0.4,0) [0|100] "%" Vector__XXX
 SG_ EngExCrankcaseBlowbyPress : 8|8@1+ (0.05,0) [0|12.5] "kPa" Vector__XXX
 SG_ EngFuelDeliveryPress : 0|8@1+ (4,0) [0|1000] "kPa" Vector__XXX

BO_ 2633929726 EES: 8 Vector__XXX
 SG_ TurningGearEngaged : 18|2@1+ (1,0) [0|3] "" Vector__XXX
 SG_ SafetyWireStatus : 16|2@1+ (1,0) [0|3] "" Vector__XXX
 SG_ ElectricalLoad : 0|16@1+ (0.5,0) [0|32127.5] "kW" Vector__XXX

BO_ 2566772222 EEC5: 8 Vector__XXX
 SG_ EngVrableGeometryTurbo1CtrlMode : 52|2@1+ (1,0) [0|3] "" Vector__XXX
 SG_ EngTrb1ClcltedTurbineIntakeTemp : 0|16@1+ (0.03125,-273) [-273|1734.96875] "deg C" Vector__XXX
 SG_ EngExhstGsRcrculation1ValveCtrl : 32|16@1+ (0.0025,0) [0|160.6375] "%" Vector__XXX
 SG_ EngVrblGometryTurbo1ActuatorPos : 56|8@1+ (0.4,0) [0|100] "%" Vector__XXX
 SG_ EngVrblGmtryTrbArCtrlShtffValve : 48|2@1+ (1,0) [0|3] "" Vector__XXX
 SG_ EngTrb1ClcltedTurbineOutletTemp : 16|16@1+ (0.03125,-273) [-273|1734.96875] "deg C" Vector__XXX

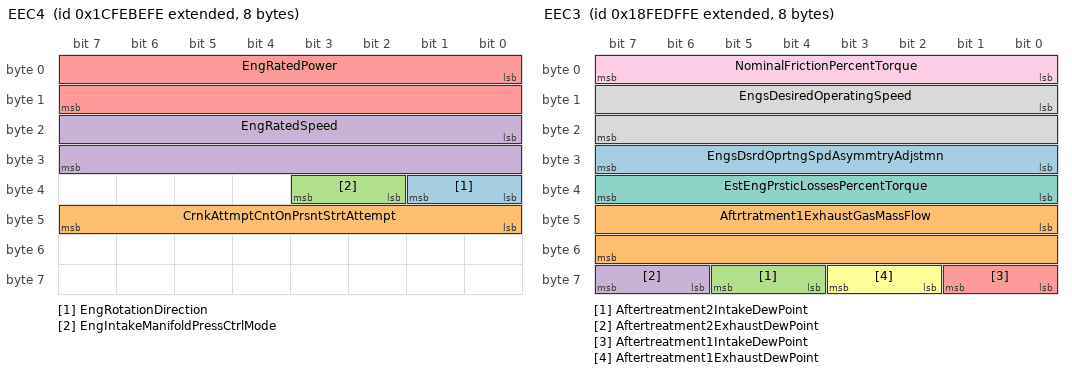
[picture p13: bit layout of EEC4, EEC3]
BO_ 2633940734 EEC4: 8 Vector__XXX
 SG_ EngRotationDirection : 32|2@1+ (1,0) [0|3] "" Vector__XXX
 SG_ CrnkAttmptCntOnPrsntStrtAttempt : 40|8@1+ (1,0) [0|250] "" Vector__XXX
 SG_ EngIntakeManifoldPressCtrlMode : 34|2@1+ (1,0) [0|3] "" Vector__XXX
 SG_ EngRatedSpeed : 16|16@1+ (0.125,0) [0|8031.875] "rpm" Vector__XXX
 SG_ EngRatedPower : 0|16@1+ (0.5,0) [0|32127.5] "kW" Vector__XXX

BO_ 2566840318 EEC3: 8 Vector__XXX
 SG_ EngsDsrdOprtngSpdAsymmtryAdjstmn : 24|8@1+ (1,0) [0|250] "" Vector__XXX
 SG_ Aftrtratment1ExhaustGasMassFlow : 40|16@1+ (0.2,0) [0|12851] "kg/h" Vector__XXX
 SG_ Aftertreatment2IntakeDewPoint : 60|2@1+ (1,0) [0|3] "" Vector__XXX
 SG_ Aftertreatment2ExhaustDewPoint : 62|2@1+ (1,0) [0|3] "" Vector__XXX
 SG_ Aftertreatment1IntakeDewPoint : 56|2@1+ (1,0) [0|3] "" Vector__XXX
 SG_ Aftertreatment1ExhaustDewPoint : 58|2@1+ (1,0) [0|3] "" Vector__XXX
 SG_ EstEngPrsticLossesPercentTorque : 32|8@1+ (1,-125) [-125|125] "%" Vector__XXX
 SG_ EngsDesiredOperatingSpeed : 8|16@1+ (0.125,0) [0|8031.875] "rpm" Vector__XXX
 SG_ NominalFrictionPercentTorque : 0|8@1+ (1,-125) [-125|125] "%" Vector__XXX

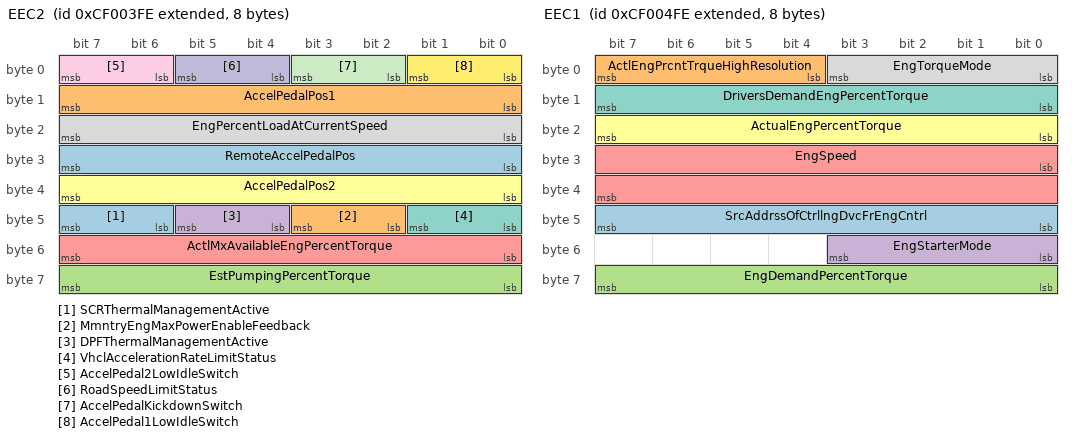
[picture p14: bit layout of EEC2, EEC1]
BO_ 2364539902 EEC2: 8 Vector__XXX
 SG_ SCRThermalManagementActive : 46|2@1+ (1,0) [0|3] "" Vector__XXX
 SG_ MmntryEngMaxPowerEnableFeedback : 42|2@1+ (1,0) [0|3] "" Vector__XXX
 SG_ EstPumpingPercentTorque : 56|8@1+ (1,-125) [-125|125] "%" Vector__XXX
 SG_ DPFThermalManagementActive : 44|2@1+ (1,0) [0|3] "" Vector__XXX
 SG_ ActlMxAvailableEngPercentTorque : 48|8@1+ (0.4,0) [0|100] "%" Vector__XXX
 SG_ AccelPedalPos2 : 32|8@1+ (0.4,0) [0|100] "%" Vector__XXX
 SG_ VhclAccelerationRateLimitStatus : 40|2@1+ (1,0) [0|3] "" Vector__XXX
 SG_ EngPercentLoadAtCurrentSpeed : 16|8@1+ (1,0) [0|250] "%" Vector__XXX
 SG_ AccelPedal2LowIdleSwitch : 6|2@1+ (1,0) [0|3] "" Vector__XXX
 SG_ RoadSpeedLimitStatus : 4|2@1+ (1,0) [0|3] "" Vector__XXX
 SG_ AccelPedalKickdownSwitch : 2|2@1+ (1,0) [0|3] "" Vector__XXX
 SG_ AccelPedal1LowIdleSwitch : 0|2@1+ (1,0) [0|3] "" Vector__XXX
 SG_ RemoteAccelPedalPos : 24|8@1+ (0.4,0) [0|100] "%" Vector__XXX
 SG_ AccelPedalPos1 : 8|8@1+ (0.4,0) [0|100] "%" Vector__XXX

BO_ 2364540158 EEC1: 8 Vector__XXX
 SG_ SrcAddrssOfCtrllngDvcFrEngCntrl : 40|8@1+ (1,0) [0|255] "" Vector__XXX
 SG_ ActlEngPrcntTrqueHighResolution : 4|4@1+ (0.125,0) [0|0.875] "%" Vector__XXX
 SG_ EngDemandPercentTorque : 56|8@1+ (1,-125) [-125|125] "%" Vector__XXX
 SG_ EngStarterMode : 48|4@1+ (1,0) [0|15] "" Vector__XXX
 SG_ EngSpeed : 24|16@1+ (0.125,0) [0|8031.875] "rpm" Vector__XXX
 SG_ ActualEngPercentTorque : 16|8@1+ (1,-125) [-125|125] "%" Vector__XXX
 SG_ DriversDemandEngPercentTorque : 8|8@1+ (1,-125) [-125|125] "%" Vector__XXX
 SG_ EngTorqueMode : 0|4@1+ (1,0) [0|15] "" Vector__XXX

BO_ 2566768126 ECUID: 8 Vector__XXX
 SG_ ECUType : 24|8@1+ (1,0) [0|255] "" Vector__XXX
 SG_ ECULocation : 16|8@1+ (1,0) [0|255] "" Vector__XXX
 SG_ ECUSerialNumber : 8|8@1+ (1,0) [0|255] "" Vector__XXX
 SG_ ECUPartNumber : 0|8@1+ (1,0) [0|255] "" Vector__XXX

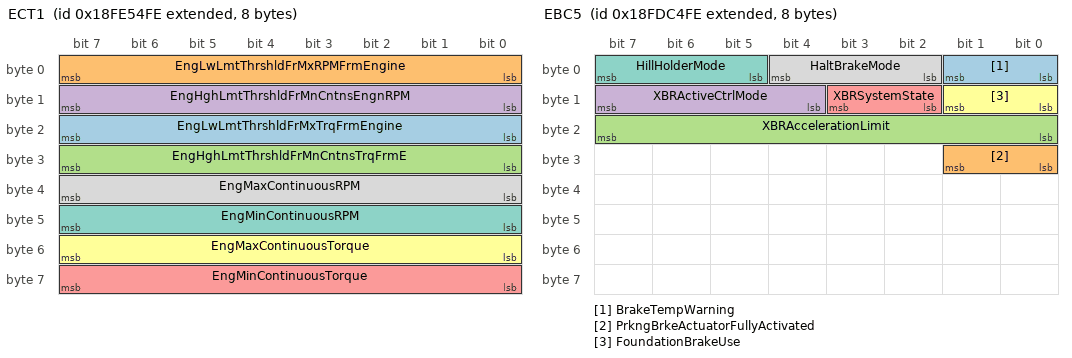
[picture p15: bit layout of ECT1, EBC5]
BO_ 2566804734 ECT1: 8 Vector__XXX
 SG_ EngLwLmtThrshldFrMxTrqFrmEngine : 16|8@1+ (1,-125) [-125|125] "%" Vector__XXX
 SG_ EngLwLmtThrshldFrMxRPMFrmEngine : 0|8@1+ (32,0) [0|8000] "rpm" Vector__XXX
 SG_ EngHghLmtThrshldFrMnCntnsTrqFrmE : 24|8@1+ (1,-125) [-125|125] "%" Vector__XXX
 SG_ EngHghLmtThrshldFrMnCntnsEngnRPM : 8|8@1+ (32,0) [0|8000] "rpm" Vector__XXX
 SG_ EngMinContinuousTorque : 56|8@1+ (1,-125) [-125|125] "%" Vector__XXX
 SG_ EngMaxContinuousTorque : 48|8@1+ (1,-125) [-125|125] "%" Vector__XXX
 SG_ EngMinContinuousRPM : 40|8@1+ (32,0) [0|8000] "rpm" Vector__XXX
 SG_ EngMaxContinuousRPM : 32|8@1+ (32,0) [0|8000] "rpm" Vector__XXX

BO_ 2566767870 EBC5: 8 Vector__XXX
 SG_ BrakeTempWarning : 0|2@1+ (1,0) [0|3] "" Vector__XXX
 SG_ PrkngBrkeActuatorFullyActivated : 24|2@1+ (1,0) [0|3] "" Vector__XXX
 SG_ XBRAccelerationLimit : 16|8@1+ (0.1,-12.5) [-12.5|12.5] "m/s/s" Vector__XXX
 SG_ XBRActiveCtrlMode : 12|4@1+ (1,0) [0|15] "" Vector__XXX
 SG_ XBRSystemState : 10|2@1+ (1,0) [0|3] "" Vector__XXX
 SG_ FoundationBrakeUse : 8|2@1+ (1,0) [0|3] "" Vector__XXX
 SG_ HillHolderMode : 5|3@1+ (1,0) [0|7] "" Vector__XXX
 SG_ HaltBrakeMode : 2|3@1+ (1,0) [0|7] "" Vector__XXX

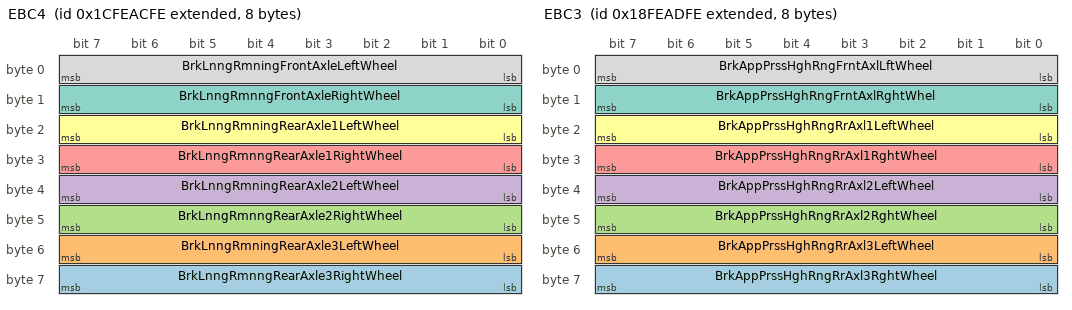
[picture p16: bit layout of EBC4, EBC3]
BO_ 2633936126 EBC4: 8 Vector__XXX
 SG_ BrkLnngRmnngRearAxle3RightWheel : 56|8@1+ (0.4,0) [0|100] "%" Vector__XXX
 SG_ BrkLnngRmningRearAxle3LeftWheel : 48|8@1+ (0.4,0) [0|100] "%" Vector__XXX
 SG_ BrkLnngRmnngRearAxle2RightWheel : 40|8@1+ (0.4,0) [0|100] "%" Vector__XXX
 SG_ BrkLnngRmningRearAxle2LeftWheel : 32|8@1+ (0.4,0) [0|100] "%" Vector__XXX
 SG_ BrkLnngRmnngRearAxle1RightWheel : 24|8@1+ (0.4,0) [0|100] "%" Vector__XXX
 SG_ BrkLnngRmningRearAxle1LeftWheel : 16|8@1+ (0.4,0) [0|100] "%" Vector__XXX
 SG_ BrkLnngRmnngFrontAxleRightWheel : 8|8@1+ (0.4,0) [0|100] "%" Vector__XXX
 SG_ BrkLnngRmningFrontAxleLeftWheel : 0|8@1+ (0.4,0) [0|100] "%" Vector__XXX

BO_ 2566827518 EBC3: 8 Vector__XXX
 SG_ BrkAppPrssHghRngRrAxl3RghtWheel : 56|8@1+ (5,0) [0|1250] "kPa" Vector__XXX
 SG_ BrkAppPrssHghRngRrAxl3LeftWheel : 48|8@1+ (5,0) [0|1250] "kPa" Vector__XXX
 SG_ BrkAppPrssHghRngRrAxl2RghtWheel : 40|8@1+ (5,0) [0|1250] "kPa" Vector__XXX
 SG_ BrkAppPrssHghRngRrAxl2LeftWheel : 32|8@1+ (5,0) [0|1250] "kPa" Vector__XXX
 SG_ BrkAppPrssHghRngRrAxl1RghtWheel : 24|8@1+ (5,0) [0|1250] "kPa" Vector__XXX
 SG_ BrkAppPrssHghRngRrAxl1LeftWheel : 16|8@1+ (5,0) [0|1250] "kPa" Vector__XXX
 SG_ BrkAppPrssHghRngFrntAxlRghtWhel : 8|8@1+ (5,0) [0|1250] "kPa" Vector__XXX
 SG_ BrkAppPrssHghRngFrntAxlLftWheel : 0|8@1+ (5,0) [0|1250] "kPa" Vector__XXX

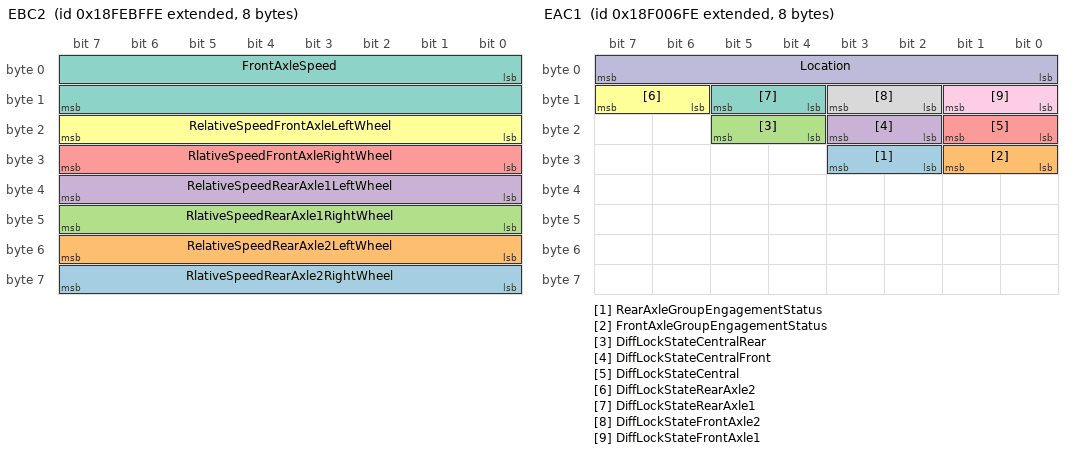
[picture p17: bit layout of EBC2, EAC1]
BO_ 2566832126 EBC2: 8 Vector__XXX
 SG_ RlativeSpeedRearAxle2RightWheel : 56|8@1+ (0.0625,-7.8125) [-7.8125|7.8125] "km/h" Vector__XXX
 SG_ RelativeSpeedRearAxle2LeftWheel : 48|8@1+ (0.0625,-7.8125) [-7.8125|7.8125] "km/h" Vector__XXX
 SG_ RlativeSpeedRearAxle1RightWheel : 40|8@1+ (0.0625,-7.8125) [-7.8125|7.8125] "km/h" Vector__XXX
 SG_ RelativeSpeedRearAxle1LeftWheel : 32|8@1+ (0.0625,-7.8125) [-7.8125|7.8125] "km/h" Vector__XXX
 SG_ RlativeSpeedFrontAxleRightWheel : 24|8@1+ (0.0625,-7.8125) [-7.8125|7.8125] "km/h" Vector__XXX
 SG_ RelativeSpeedFrontAxleLeftWheel : 16|8@1+ (0.0625,-7.8125) [-7.8125|7.8125] "km/h" Vector__XXX
 SG_ FrontAxleSpeed : 0|16@1+ (0.00390625,0) [0|250.996] "km/h" Vector__XXX

BO_ 2565865982 EBC1: 8 Vector__XXX
 SG_ EngAuxShutdownSwitch : 28|2@1+ (1,0) [0|3] "" Vector__XXX
 SG_ SrcAddrssOfCtrllngDvcFrBrkCntrl : 48|8@1+ (1,0) [0|255] "" Vector__XXX
 SG_ BrakePedalPos : 8|8@1+ (0.4,0) [0|100] "%" Vector__XXX
 SG_ TrctrMntdTrilerABSWarningSignal : 62|2@1+ (1,0) [0|3] "" Vector__XXX
 SG_ TrailerABSStatus : 60|2@1+ (1,0) [0|3] "" Vector__XXX
 SG_ HaltBrakeSwitch : 58|2@1+ (1,0) [0|3] "" Vector__XXX
 SG_ ATC_ASRInformationSignal : 46|2@1+ (1,0) [0|3] "" Vector__XXX
 SG_ ABS_EBSAmberWarningSignal : 44|2@1+ (1,0) [0|3] "" Vector__XXX
 SG_ EBSRedWarningSignal : 42|2@1+ (1,0) [0|3] "" Vector__XXX
 SG_ ABSFullyOperational : 40|2@1+ (1,0) [0|3] "" Vector__XXX
 SG_ EngRetarderSelection : 32|8@1+ (0.4,0) [0|100] "%" Vector__XXX
 SG_ RemoteAccelEnableSwitch : 30|2@1+ (1,0) [0|3] "" Vector__XXX
 SG_ EngDerateSwitch : 26|2@1+ (1,0) [0|3] "" Vector__XXX
 SG_ AccelInterlockSwitch : 24|2@1+ (1,0) [0|3] "" Vector__XXX
 SG_ TractionCtrlOverrideSwitch : 22|2@1+ (1,0) [0|3] "" Vector__XXX
 SG_ ASRHillHolderSwitch : 20|2@1+ (1,0) [0|3] "" Vector__XXX
 SG_ ASROffroadSwitch : 18|2@1+ (1,0) [0|3] "" Vector__XXX
 SG_ ABSOffroadSwitch : 16|2@1+ (1,0) [0|3] "" Vector__XXX
 SG_ EBSBrakeSwitch : 6|2@1+ (1,0) [0|3] "" Vector__XXX
 SG_ AntiLockBrakingActive : 4|2@1+ (1,0) [0|3] "" Vector__XXX
 SG_ ASRBrakeCtrlActive : 2|2@1+ (1,0) [0|3] "" Vector__XXX
 SG_ ASREngCtrlActive : 0|2@1+ (1,0) [0|3] "" Vector__XXX

BO_ 2565867262 EAC1: 8 Vector__XXX
 SG_ RearAxleGroupEngagementStatus : 26|2@1+ (1,0) [0|3] "" Vector__XXX
 SG_ FrontAxleGroupEngagementStatus : 24|2@1+ (1,0) [0|3] "" Vector__XXX
 SG_ DiffLockStateCentralRear : 20|2@1+ (1,0) [0|3] "" Vector__XXX
 SG_ DiffLockStateCentralFront : 18|2@1+ (1,0) [0|3] "" Vector__XXX
 SG_ DiffLockStateCentral : 16|2@1+ (1,0) [0|3] "" Vector__XXX
 SG_ DiffLockStateRearAxle2 : 14|2@1+ (1,0) [0|3] "" Vector__XXX
 SG_ DiffLockStateRearAxle1 : 12|2@1+ (1,0) [0|3] "" Vector__XXX
 SG_ DiffLockStateFrontAxle2 : 10|2@1+ (1,0) [0|3] "" Vector__XXX
 SG_ DiffLockStateFrontAxle1 : 8|2@1+ (1,0) [0|3] "" Vector__XXX
 SG_ Location : 0|8@1+ (1,0) [0|255] "" Vector__XXX

BO_ 2566821118 EAC: 8 Vector__XXX
 SG_ SeaWaterPumpOutletPress : 16|8@1+ (2,0) [0|500] "kPa" Vector__XXX
 SG_ EngAuxCoolantTemp : 8|8@1+ (1,-40) [-40|210] "deg C" Vector__XXX
 SG_ EngAuxCoolantPress : 0|8@1+ (4,0) [0|1000] "kPa" Vector__XXX

BO_ 2566810622 DI: 8 Vector__XXX
 SG_ Driver2 : 8|8@1+ (1,0) [0|255] "" Vector__XXX
 SG_ Driver1 : 0|8@1+ (1,0) [0|255] "" Vector__XXX

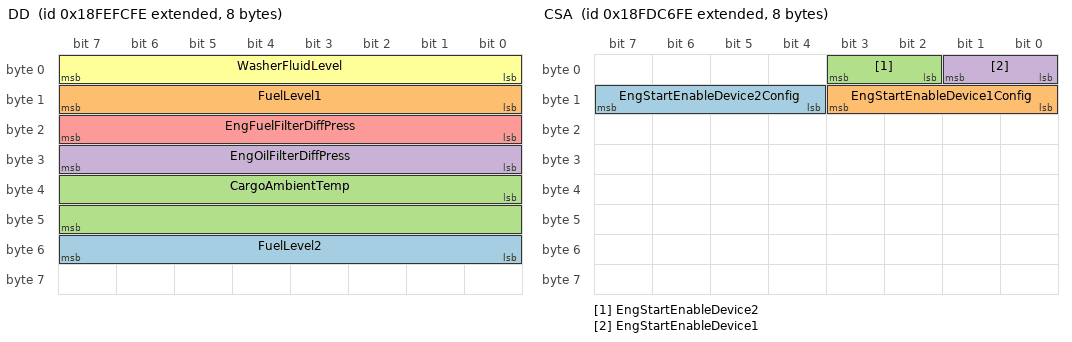
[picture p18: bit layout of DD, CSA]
BO_ 2566847742 DD: 8 Vector__XXX
 SG_ FuelLevel2 : 48|8@1+ (0.4,0) [0|100] "%" Vector__XXX
 SG_ FuelLevel1 : 8|8@1+ (0.4,0) [0|100] "%" Vector__XXX
 SG_ CargoAmbientTemp : 32|16@1+ (0.03125,-273) [-273|1734.96875] "deg C" Vector__XXX
 SG_ EngOilFilterDiffPress : 24|8@1+ (0.5,0) [0|125] "kPa" Vector__XXX
 SG_ EngFuelFilterDiffPress : 16|8@1+ (2,0) [0|500] "kPa" Vector__XXX
 SG_ WasherFluidLevel : 0|8@1+ (0.4,0) [0|100] "%" Vector__XXX

BO_ 2566768382 CSA: 8 Vector__XXX
 SG_ EngStartEnableDevice2Config : 12|4@1+ (1,0) [0|15] "" Vector__XXX
 SG_ EngStartEnableDevice1Config : 8|4@1+ (1,0) [0|15] "" Vector__XXX
 SG_ EngStartEnableDevice2 : 2|2@1+ (1,0) [0|3] "" Vector__XXX
 SG_ EngStartEnableDevice1 : 0|2@1+ (1,0) [0|3] "" Vector__XXX

BO_ 2566811902 CVW: 8 Vector__XXX
 SG_ PoweredVehicleWeight : 0|16@1+ (10,0) [0|642550] "kg" Vector__XXX
 SG_ GrossCombinationVehicleWeight : 16|16@1+ (10,0) [0|642550] "kg" Vector__XXX

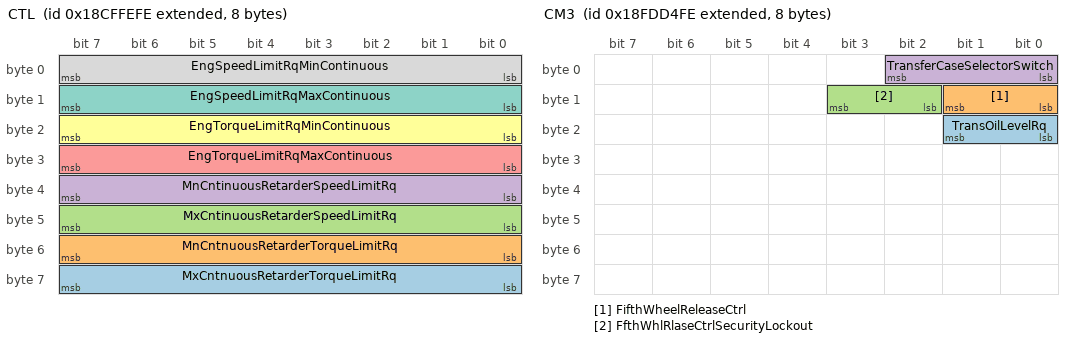
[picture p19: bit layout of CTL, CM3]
BO_ 2563768062 CTL: 8 Vector__XXX
 SG_ MxCntnuousRetarderTorqueLimitRq : 56|8@1+ (1,-125) [-125|125] "%" Vector__XXX
 SG_ MnCntnuousRetarderTorqueLimitRq : 48|8@1+ (1,-125) [-125|125] "%" Vector__XXX
 SG_ MxCntinuousRetarderSpeedLimitRq : 40|8@1+ (32,0) [0|8000] "rpm" Vector__XXX
 SG_ MnCntinuousRetarderSpeedLimitRq : 32|8@1+ (32,0) [0|8000] "rpm" Vector__XXX
 SG_ EngTorqueLimitRqMaxContinuous : 24|8@1+ (1,-125) [-125|125] "%" Vector__XXX
 SG_ EngTorqueLimitRqMinContinuous : 16|8@1+ (1,-125) [-125|125] "%" Vector__XXX
 SG_ EngSpeedLimitRqMaxContinuous : 8|8@1+ (32,0) [0|8000] "rpm" Vector__XXX
 SG_ EngSpeedLimitRqMinContinuous : 0|8@1+ (32,0) [0|8000] "rpm" Vector__XXX

BO_ 2633924862 CT6: 8 Vector__XXX
 SG_ EngAverageCombustionTime : 16|16@1+ (0.01,0) [0|642.55] "ms" Vector__XXX
 SG_ EngDesiredCombustionTime : 0|16@1+ (0.01,0) [0|642.55] "ms" Vector__XXX

BO_ 2633924606 CT5: 8 Vector__XXX
 SG_ EngCyl20CombustionTime : 48|16@1+ (0.01,0) [0|642.55] "ms" Vector__XXX
 SG_ EngCyl19CombustionTime : 32|16@1+ (0.01,0) [0|642.55] "ms" Vector__XXX
 SG_ EngCyl18CombustionTime : 16|16@1+ (0.01,0) [0|642.55] "ms" Vector__XXX
 SG_ EngCyl17CombustionTime : 0|16@1+ (0.01,0) [0|642.55] "ms" Vector__XXX

BO_ 2633924350 CT4: 8 Vector__XXX
 SG_ EngCyl16CombustionTime : 48|16@1+ (0.01,0) [0|642.55] "ms" Vector__XXX
 SG_ EngCyl15CombustionTime : 32|16@1+ (0.01,0) [0|642.55] "ms" Vector__XXX
 SG_ EngCyl14CombustionTime : 16|16@1+ (0.01,0) [0|642.55] "ms" Vector__XXX
 SG_ EngCyl13CombustionTime : 0|16@1+ (0.01,0) [0|642.55] "ms" Vector__XXX

BO_ 2633924094 CT3: 8 Vector__XXX
 SG_ EngCyl12CombustionTime : 48|16@1+ (0.01,0) [0|642.55] "ms" Vector__XXX
 SG_ EngCyl11CombustionTime : 32|16@1+ (0.01,0) [0|642.55] "ms" Vector__XXX
 SG_ EngCyl10CombustionTime : 16|16@1+ (0.01,0) [0|642.55] "ms" Vector__XXX
 SG_ EngCyl9CombustionTime : 0|16@1+ (0.01,0) [0|642.55] "ms" Vector__XXX

BO_ 2633923838 CT2: 8 Vector__XXX
 SG_ EngCyl8CombustionTime : 48|16@1+ (0.01,0) [0|642.55] "ms" Vector__XXX
 SG_ EngCyl7CombustionTime : 32|16@1+ (0.01,0) [0|642.55] "ms" Vector__XXX
 SG_ EngCyl6CombustionTime : 16|16@1+ (0.01,0) [0|642.55] "ms" Vector__XXX
 SG_ EngCyl5CombustionTime : 0|16@1+ (0.01,0) [0|642.55] "ms" Vector__XXX

BO_ 2633923582 CT1: 8 Vector__XXX
 SG_ EngCyl4CombustionTime : 48|16@1+ (0.01,0) [0|642.55] "ms" Vector__XXX
 SG_ EngCyl3CombustionTime : 32|16@1+ (0.01,0) [0|642.55] "ms" Vector__XXX
 SG_ EngCyl2CombustionTime : 16|16@1+ (0.01,0) [0|642.55] "ms" Vector__XXX
 SG_ EngCyl1CombustionTime : 0|16@1+ (0.01,0) [0|642.55] "ms" Vector__XXX

BO_ 2633878014 CMI: 8 Vector__XXX
 SG_ TotalCountOfConfigChangesMade : 0|16@1+ (1,0) [0|64255] "counts" Vector__XXX

BO_ 2566771966 CM3: 8 Vector__XXX
 SG_ TransOilLevelRq : 16|2@1+ (1,0) [0|3] "" Vector__XXX
 SG_ FifthWheelReleaseCtrl : 8|2@1+ (1,0) [0|3] "" Vector__XXX
 SG_ FfthWhlRlaseCtrlSecurityLockout : 10|2@1+ (1,0) [0|3] "" Vector__XXX
 SG_ TransferCaseSelectorSwitch : 0|3@1+ (1,0) [0|7] "" Vector__XXX

CM_ BO_ 2566774014 "Marine Control Information";
CM_ SG_ 2566774014 SlowVesselModeStatus "The status of the Slow Vessel Mode.";
CM_ SG_ 2566774014 TrollingModeStatus "The status of the Trolling Mode.";
CM_ SG_ 2566774014 EngThrttlSynchrnztionModeStatus "The status of the Throttle Synchronization Mode.";
CM_ BO_ 2566823166 "Main Bearing Temperature 3";
CM_ SG_ 2566823166 EngMainBearing11Temp "Temperature of the main bearing which supports the crankshaft of the engine.";
CM_ SG_ 2566823166 EngMainBearing10Temp "Temperature of the main bearing which supports the crankshaft of the engine.";
CM_ SG_ 2566823166 EngMainBearing9Temp "Temperature of the main bearing which supports the crankshaft of the engine.";
CM_ BO_ 2566823422 "Main Bearing Temperature 2";
CM_ SG_ 2566823422 EngMainBearing8Temp "Temperature of the main bearing which supports the crankshaft of the engine.";
CM_ SG_ 2566823422 EngMainBearing7Temp "Temperature of the main bearing which supports the crankshaft of the engine.";
CM_ SG_ 2566823422 EngMainBearing6Temp "Temperature of the main bearing which supports the crankshaft of the engine.";
CM_ SG_ 2566823422 EngMainBearing5Temp "Temperature of the main bearing which supports the crankshaft of the engine.";
CM_ BO_ 2566823678 "Main Bearing Temperature 1";
CM_ SG_ 2566823678 EngMainBearing4Temp "Temperature of the main bearing which supports the crankshaft of the engine.";
CM_ SG_ 2566823678 EngMainBearing3Temp "Temperature of the main bearing which supports the crankshaft of the engine.";
CM_ SG_ 2566823678 EngMainBearing2Temp "Temperature of the main bearing which supports the crankshaft of the engine.";
CM_ SG_ 2566823678 EngMainBearing1Temp "Temperature of the main bearing which supports the crankshaft of the engine.";
CM_ BO_ 2432595710 "Laser Leveling System Vertical Position Display Data";
CM_ SG_ 2432595710 DisplayDeadbands "Sets Display Deadbands mode.";
CM_ SG_ 2432595710 LEDPatternCtrl "Sets LED Pattern control mode on laser leveling systems.";
CM_ SG_ 2432595710 LEDDisplayDeadbandCtrl "This parameter informs the system what the selected Display deadband will be.";
CM_ SG_ 2432595710 LEDDisplayModeCtrl "This parameter informs the system what the selected Display mode will be.";
CM_ SG_ 2432595710 LEDDisplayData1 "Informs display devices how to display the current vertical position.";
CM_ BO_ 2365486590 "Laser Leveling System Vertical Deviation";
CM_ SG_ 2365486590 LaserStrikeDataLatency "Time from laser strike to CAN message transmission.";
CM_ SG_ 2365486590 LaserReceiverType "Identifies which type of Laser Receiver transmitted the message.";
CM_ SG_ 2365486590 LaserStrikeVerticalDeviation "The calculated distance from the laser strike position to the current land leveling system reference point.";
CM_ SG_ 2365486590 AbsLaserStrikePos "Laser Strike location on the survey type laser receiver.";
CM_ BO_ 2365485566 "Laser Tracer Position";
CM_ SG_ 2365485566 LaserTracerInformation "Provides the status of the laser tracer to the operator.";
CM_ SG_ 2365485566 LEDDisplayData2 "Informs display devices how to display the current position of the laser tracer.";
CM_ SG_ 2365485566 LaserTracerHorizontalDeviation "The calculated percent deviation between the target distance and the center of the laser tracer.";
CM_ SG_ 2365485566 LaserTracerVerticalDistance "The elevation of the laser tracer sensor in a laser leveling system.";
CM_ SG_ 2365485566 LaserTracerTargetDeviation "The calculated distance for the laser target to the current laser tracer reference point.";
CM_ BO_ 2365486334 "Modify Leveling System Control Set Point";
CM_ SG_ 2365486334 BldHeightSetPointHighResolution "High resolution for the laser guided blade set point.";
CM_ SG_ 2365486334 ModifyLevelingSystemSetPoint "Used to control and coordinate the set point for the leveling system.";
CM_ BO_ 2364542462 "Land Leveling System Operational Information";
CM_ SG_ 2364542462 SdshftDsrdBldOffsetOperatorCtrl "This parameter indicates the side-shift blade control mode operator control state the user has set for the land leveling system.";
CM_ SG_ 2364542462 SdshftBldCtrlMdeOperatorControl "This parameter indicates the side-shift offset operator control state the user has set for the land leveling system.";
CM_ SG_ 2364542462 RghtDsrdBladeOffsetOperatorCtrl "This parameter indicates the right blade offset operator control state the user has set for the land leveling system.";
CM_ SG_ 2364542462 RghtBldeCtrlModeOperatorControl "This parameter indicates the right blade control mode operator control state the user has set for the land leveling system.";
CM_ SG_ 2364542462 LftDsredBladeOffsetOperatorCtrl "This parameter indicates the left blade offset operator control state the user has set for the land leveling system.";
CM_ SG_ 2364542462 LftBladeCtrlModeOperatorControl "This parameter indicates the left blade control mode operator control state the user has set for the land leveling system.";
CM_ SG_ 2364542462 BladeAutoModeCmd "Allows other controllers to command to the primary control system what they think is the appropriate auto control mode to";
CM_ SG_ 2364542462 DesiredGradeOffsetSwitch "This parameter indicates the grade offset switch state the user has set for the land leveling system.";
CM_ SG_ 2364542462 BladeCtrlModeSwitch "This parameter indicates the blade control mode switch state the user has set for the land leveling system.";
CM_ SG_ 2364542462 StElvtnSnsor2ReferenceElevation "Command from a display or other external device (i.";
CM_ SG_ 2364542462 StElvtnSnsor1ReferenceElevation "Command from a display or other external device (i.";
CM_ BO_ 2365486078 "Laser Receiver Mast Position";
CM_ SG_ 2365486078 MastPos "Used to monitor the position of the sensor attached to the land leveling mast.";
CM_ BO_ 2633937918 "Fuel Information (Liquid)";
CM_ SG_ 2633937918 TotalEngPTOGovernorFuelUsed "Total fuel used while the PTO or remote PTO governors are in the hold state and engine speed is above zero, over the";
CM_ SG_ 2633937918 TripAverageFuelRate "Average fuel rate, equal to trip fuel divided by trip time while the engine speed is above zero, since the last trip reset.";
CM_ SG_ 2633937918 FlexibleFuelPercentage "Measured signal that indicates the percentage of alcohol in the fuel currently being used.";
CM_ BO_ 2566845182 "Fuel Economy (Liquid)";
CM_ SG_ 2566845182 EngAverageFuelEconomy "Average of instantaneous fuel economy for that segment of vehicle operation of interest.";
CM_ SG_ 2566845182 EngInstantaneousFuelEconomy "Current fuel economy at current vehicle velocity.";
CM_ SG_ 2566845182 EngFuelRate "Amount of fuel consumed by engine per unit of time.";
CM_ SG_ 2566845182 EngThrottleValve2Pos "The sensed position feedback of the valve, coming from a second electrical actuator for a second throttle plate, used to";
CM_ SG_ 2566845182 EngThrottleValve1Pos "The position of the valve used to regulate the supply of a fluid, usually air or fuel/air mixture, to an engine.";
CM_ BO_ 2566842878 "Fuel Consumption (Liquid)";
CM_ SG_ 2566842878 EngTotalFuelUsed "Accumulated amount of fuel used during vehicle operation.";
CM_ SG_ 2566842878 EngTripFuel "Fuel consumed during all or part of a journey.";
CM_ BO_ 2633883646 "Front Wheel Drive Status";
CM_ SG_ 2633883646 FrontWheelDriveActuatorStatus "Feedback on the front wheel drive actuator.";
CM_ BO_ 2633880062 "FMS-standard Interface Identity/Capabilities";
CM_ SG_ 2633880062 FMSstandardSWversionSupported "Information that identifies which issue level of the FMS-standard document the software included in the FMS gateway supports.";
CM_ SG_ 2633880062 FMSstandardRqsSupported "Status signal which indicates if the FMS Vehicle Interface (FMS Gateway) will respond to requests from the FMS device";
CM_ SG_ 2633880062 FMSstandardDiagnosticsSupported "Status signal which indicates if the FMS Vehicle Interface (FMS Gateway) supports the handling of diagnostic messages";
CM_ BO_ 2566806526 "Forward Lane Image";
CM_ SG_ 2566806526 LnDprtureIndicationEnableStatus "Indicates whether lane departure indication is active.";
CM_ SG_ 2566806526 LaneTrackingStatusLeftSide "Indicates whether the left side is tracking lane.";
CM_ SG_ 2566806526 LaneTrackingStatusRightSide "Indicates whether right side is tracking lane.";
CM_ BO_ 2431649790 "Forward Lane Image urgent msg";
CM_ SG_ 2431649790 LaneDepartureImminentLeftSide "Indicates departure imminent on left side of lane.";
CM_ SG_ 2431649790 LaneDepartureImminentRightSide "Indicates departure imminent on right side of lane.";
CM_ SG_ 2431649790 LaneDepartureRight "Indicates that the middle of vehicle departs the lane on the right side.";
CM_ SG_ 2431649790 LaneDepartureLeft "Indicates that the middle of vehicle departs the lane on the left side.";
CM_ BO_ 2633929214 "Fuel Leakage";
CM_ SG_ 2633929214 EngFuelLeakage2 "Status signal which indicates fuel leakage in the fuel rail of the engine.";
CM_ SG_ 2633929214 EngFuelLeakage1 "Status signal which indicates fuel leakage in the fuel rail of the engine.";
CM_ BO_ 2566831614 "Fan Drive";
CM_ SG_ 2566831614 FanSpeed "The speed of the fan associated with engine coolant system.";
CM_ SG_ 2566831614 FanDriveState "This parameter is used to indicate the current state or mode of operation by the fan drive.";
CM_ SG_ 2566831614 EstPercentFanSpeed "Estimated fan speed as a ratio of the fan drive (current speed) to the fully engaged fan drive (maximum fan speed).";
CM_ SG_ 2566831614 HydFanMotorPress "The hydraulic pressure used to drive the fan system, sensed before the hydraulic fan motor.";
CM_ SG_ 2566831614 FanDriveBypassCmdStatus "Status of the Fan Drive Bypass Command as being commanded by the ECU.";
CM_ BO_ 2364542206 "Electronic Transmission Controller #8";
CM_ SG_ 2364542206 TransClutch_ConverterInputSpeed "Rotational velocity of the input to a transmission's master clutch or torque converter.";
CM_ SG_ 2364542206 TransTorqueConverterRatio "Ratio of the transmissions torque converter output torque to torque converter input torque at current speed.";
CM_ BO_ 2566802174 "Electronic Transmission Controller 7";
CM_ SG_ 2566802174 TrnsRvrseGearShiftInhibitStatus "Reflects the status of transmission reverse inhibit activity in response to requests via SPN 4242 - Transmission Reverse";
CM_ SG_ 2566802174 TrnsCrrntRangeDisplayBlankState "State signal indicating a transmission request for the display of the Transmission Current Range parameter (SPN 163) to";
CM_ SG_ 2566802174 TransWarningIndicator "Signal from transmission indicating that some aspect of its operation is not functioning correctly, and as a result,";
CM_ SG_ 2566802174 TransMode8Indicator "Indicates whether transmission mode 8 is enabled.";
CM_ SG_ 2566802174 TransMode7Indicator "Indicates whether transmission mode 7 is enabled.";
CM_ SG_ 2566802174 TransMode6Indicator "Indicates whether transmission mode 6 is enabled.";
CM_ SG_ 2566802174 TransMode5Indicator "Indicates whether transmission mode 5 is enabled.";
CM_ SG_ 2566802174 TransRqedGearFeedback "Feedback of the SPN 525 Transmission Requested Gear input as received from the shift selector, ABS or engine via";
CM_ SG_ 2566802174 TransMode1Indicator "This state signal is the transmission's indication that it is operating under transmission mode 1 (SPN 1852) as";
CM_ SG_ 2566802174 TransMode2Indicator "This state signal is the transmission's indication that it is operating under transmission mode 2 (SPN 1853) as";
CM_ SG_ 2566802174 TransMode3Indicator "This state signal is the transmission's indication that it is operating under transmission mode 3 (SPN 1854) as";
CM_ SG_ 2566802174 TransMode4Indicator "This state signal is the transmission's indication that it is operating under transmission mode 4 (SPN 1855) as";
CM_ SG_ 2566802174 TransShiftInhibitIndicator "State signal indicating a transmission request for the Shift Inhibit Indicator to be active or inactive.";
CM_ SG_ 2566802174 TransEngCrankEnable "State signal from the transmission indicating if the transmission's status is such that engine cranking is allowed (i.";
CM_ SG_ 2566802174 ActiveShiftConsoleIndicator "Signal from transmission control unit indicating which shift console (primary or secondary) it currently considers as the";
CM_ SG_ 2566802174 TransReadyForBrakeRelease "This parameter indicates that enough torque / motive force is available at the transmission output shaft to release all the";
CM_ SG_ 2566802174 TransRqedRangeDisplayFlashState "State signal indicating a transmission request for the display of the Transmission Requested Range parameter (SPN 162)";
CM_ SG_ 2566802174 TransRqedRangeDisplayBlankState "State signal indicating a transmission request for the display of the Transmission Requested Range parameter (SPN162)";
CM_ SG_ 2566802174 TransServiceIndicator "Signal from transmission indicating that some aspect of the gearbox requires servicing, such as the oil, filter, clutch(es) or";
CM_ BO_ 2633935870 "Electronic Transmission Controller 6";
CM_ SG_ 2633935870 ClutchLifeRemaining "Signal which indicates the actual clutch life remaining in percent.";
CM_ SG_ 2633935870 LowestPossibleGear "The transmission calculates this gear continuously.";
CM_ SG_ 2633935870 HighestPossibleGear "The transmission calculates this gear continuously.";
CM_ SG_ 2633935870 RecommendedGear "The transmission calculates this gear continuously.";
CM_ BO_ 2633942014 "Electronic Transmission Controller 5";
CM_ SG_ 2633942014 TransForwardDirectionSwitch "Identifies the status of the switch that indicates forward direction.";
CM_ SG_ 2633942014 TransNeutralSwitch "Identifies the status of the switch that indicates neutral.";
CM_ SG_ 2633942014 TransReverseDirectionSwitch "Identifies the status of the switch that indicates reverse direction.";
CM_ SG_ 2633942014 TransLowRangeSenseSwitch "Identifies the status of the switch that represents low range.";
CM_ SG_ 2633942014 TransHighRangeSenseSwitch "Identifies the status of the switch that represents high range.";
CM_ BO_ 2633942526 "Electronic Transmission Controller 4";
CM_ SG_ 2633942526 TransSynchronizerBrakeValue "The current modulated value for the air supply to the synchronizer brake.";
CM_ SG_ 2633942526 TransSynchronizerClutchValue "The current modulated value for the air supply to the synchronizer clutch.";
CM_ BO_ 2633943038 "Electronic Transmission Controller 3";
CM_ SG_ 2633943038 TransInertiaBrakeActuator "Identifies the status of the actuator that controls the inertia brake.";
CM_ SG_ 2633943038 TransDefuelActuator "Identifies the status of the actuator that controls the engine defuel mechanism.";
CM_ SG_ 2633943038 TransLockupClutchActuator "Identifies the status of the actuator that controls the lockup clutch.";
CM_ SG_ 2633943038 TransClutchActuator "Identifies the status of the actuator that controls the clutch.";
CM_ SG_ 2633943038 TransSplitterIndirectActuator "Identifies the status of the splitter indirect actuator in the auxiliary unit.";
CM_ SG_ 2633943038 TransSplitterDirectActuator "Identifies the status of the splitter direct actuator in the auxiliary unit.";
CM_ SG_ 2633943038 TransRangeLowActuator "Identifies the status of the range low actuator in the auxiliary unit.";
CM_ SG_ 2633943038 TransRangeHighActuator "Identifies the status of the range high actuator in the auxiliary unit.";
CM_ SG_ 2633943038 TransShiftFingerGearActuator2 "Identifies the status of the actuator that moves the shift finger identified as gear actuator #2.";
CM_ SG_ 2633943038 TransShiftFingerRailActuator2 "Identifies the status of the actuator that moves the shift finger identified as rail actuator #2.";
CM_ SG_ 2633943038 TransShiftFingerGearActuator1 "Identifies the status of the actuator that moves the shift finger identified as gear actuator #1.";
CM_ SG_ 2633943038 TransShiftFingerRailActuator1 "Identifies the status of the actuator that moves the shift finger identified as rail actuator #1.";
CM_ SG_ 2633943038 TrnsShftFngrCenterRailIndicator "Identifies the status of the shift finger in the center rail position.";
CM_ SG_ 2633943038 TrnsShftFngrEngagementIndicator "Identifies the status of the shift finger in the engagement position.";
CM_ SG_ 2633943038 TrnsShiftFingerNeutralIndicator "Indicates the status of the shift finger in the neutral position.";
CM_ SG_ 2633943038 TransShiftFingerRailPos "The current position of the shift finger in the rail direction.";
CM_ SG_ 2633943038 TransShiftFingerGearPos "The current position of the shift finger in the gear direction.";
CM_ BO_ 2565867006 "Electronic Transmission Controller 2";
CM_ SG_ 2565867006 TransCurrentRange "Range currently being commanded by the transmission control system.";
CM_ SG_ 2565867006 TransRqedRange "Range selected by the operator.";
CM_ SG_ 2565867006 TransCurrentGear "The gear currently engaged in the transmission or the last gear engaged while the transmission is in the process of";
CM_ SG_ 2565867006 TransActualGearRatio "Actual ratio of input shaft speed to output shaft speed.";
CM_ SG_ 2565867006 TransSelectedGear "The gear that the transmission will attempt to achieve during the current shift if a shift is in progress, or the next shift if one";
CM_ BO_ 2364539646 "Electronic Transmission Controller 1";
CM_ SG_ 2364539646 TrnsTrqueConverterLockupEngaged "State signal which indicates whether the torque converter lockup is engaged.";
CM_ SG_ 2364539646 TrnsTrqCnvrtrLckpTrnstnInPrcess "State signal indicating whether or not the transmission torque converter lock up clutch is transitioning between being";
CM_ SG_ 2364539646 SrcAddrssOfCtrllngDvcFrTrnsCntrl "The source address of the SAE J1939 device currently controlling the transmission.";
CM_ SG_ 2364539646 MomentaryEngMaxPowerEnable "Momentarily Requesting highest torque map from the engine control";
CM_ SG_ 2364539646 TransInputShaftSpeed "Rotational velocity of the primary shaft transferring power into the transmission.";
CM_ SG_ 2364539646 ProgressiveShiftDisable "Command signal used to indicate that progressive shifting by the engine should be disallowed.";
CM_ SG_ 2364539646 EngMomentaryOverspeedEnable "Command signal used to indicate that the engine speed may be boosted up to the maximum engine overspeed value to";
CM_ SG_ 2364539646 PercentClutchSlip "Parameter which represents the ratio of input shaft speed to current engine speed (in percent).";
CM_ SG_ 2364539646 TransOutputShaftSpeed "Calculated speed of the transmission output shaft.";
CM_ SG_ 2364539646 TransShiftInProcess "Indicates that the transmission is in process of shifting from the current gear to the selected gear.";
CM_ SG_ 2364539646 TransDrivelineEngaged "Driveline engaged indicates the transmission controlled portion of the driveline is engaged sufficiently to allow a transfer";
CM_ BO_ 2566810110 "Engine Temperature 3";
CM_ SG_ 2566810110 EngChargeAirCooler1OutletTemp "Temperature of combustion air after it exits from the Charge Air Cooler 1 but before any mixing of recirculated exhaust";
CM_ SG_ 2566810110 EngIntkVlvActationSystemOilTemp "The temperature of the oil in the hydraulic system that powers the intake valve actuation system.";
CM_ SG_ 2566810110 EngIntakeManifold1AirTemp "Temperature of pre-combustion air found in intake manifold of engine air supply system.";
CM_ SG_ 2566810110 EngCoolantTempHiRes "Temperature of liquid found in engine cooling system.";
CM_ BO_ 2566825214 "Engine Temperature 2";
CM_ SG_ 2566825214 EngExhstGsRcrculation1DiffPress "Differential pressure across the Exhaust Gas Recirculation (EGR) system";
CM_ SG_ 2566825214 EngExhaustGasRecirculation1Temp "Temperature of Recirculated Exhaust Gas.";
CM_ SG_ 2566825214 EngECUTemp "Temperature of the engine electronic control unit.";
CM_ SG_ 2566825214 EngOilTemp2 "Temperature of the engine lubricant.";
CM_ BO_ 2566844158 "Engine Temperature 1";
CM_ SG_ 2566844158 EngFuelTemp1 "Temperature of fuel (or gas) passing through the first fuel control system.";
CM_ SG_ 2566844158 EngIntercoolerThermostatOpening "The current position of the thermostat used to regulate the temperature of the engine intercooler.";
CM_ SG_ 2566844158 EngIntercoolerTemp "Temperature of liquid found in the intercooler located after the turbocharger.";
CM_ SG_ 2566844158 EngTurboOilTemp "Temperature of the turbocharger lubricant.";
CM_ SG_ 2566844158 EngOilTemp1 "Temperature of the engine lubricant.";
CM_ SG_ 2566844158 EngCoolantTemp "Temperature of liquid found in engine cooling system.";
CM_ BO_ 2566785022 "Exhaust Temperature";
CM_ SG_ 2566785022 EngExhaustGasTempRightManifold "Temperature of combustion byproducts within the right engine exhaust manifold.";
CM_ SG_ 2566785022 EngExhaustGasTempLeftManifold "Temperature of combustion byproducts within the left engine exhaust manifold.";
CM_ BO_ 2565868542 "Electronic Steering Control";
CM_ SG_ 2565868542 SterableLiftAxleLoweringInhibit "A signal which indicates if lowering of lifted axle is allowed or inhibited.";
CM_ SG_ 2565868542 AxleLocation "To identify to which of several similar devices (such as tires or fuel tanks) the information applies.";
CM_ SG_ 2565868542 TypeOfSteerTrans "Type of Steering Transmission (Ref.";
CM_ SG_ 2565868542 TypeOfSteerForces "Type of Steering Forces (Ref.";
CM_ SG_ 2565868542 SteerType "Indicates the different types of steering systems (ref.";
CM_ SG_ 2565868542 StatusOfSteerAxle "A signal which indicates different states of the steering axle";
CM_ SG_ 2565868542 ActualInnerWheelSteerAngle "Signal which indicates the actual inner wheel steering angle.";
CM_ BO_ 2633941758 "Electronic Retarder Controller 2";
CM_ SG_ 2633941758 TransOutputRetarder "Identifies the status of the transmission output retarder.";
CM_ BO_ 2565865726 "Electronic Retarder Controller 1";
CM_ SG_ 2565865726 RetarderSelectionNonEng "The [Retarder Selection, non-engine] is the position of the driver's selector for retarders that are not part of the engine";
CM_ SG_ 2565865726 SrcAddrssOfCtrllngDvcFrRtrdrCntr "The source address of the SAE J1939 device currently controlling the retarder.";
CM_ SG_ 2565865726 RetarderRoadSpeedLimitSwitch "Retarder road speed limit switch states:";
CM_ SG_ 2565865726 RetarderRoadSpeedExceededStatus "Retarder Road Speed Exceeded Status:";
CM_ SG_ 2565865726 ActlMxAvlblRtarderPercentTorque "This is the maximum amount of torque that the retarder can immediately deliver.";
CM_ SG_ 2565865726 DrvrsDmandRetarderPercentTorque "The Drivers demand retarder percent torque is the maximum torque selected by the driver when one or more modes";
CM_ SG_ 2565865726 RetarderRqingBrakeLight "Indicates that whether the retarder is requesting that the brake lights are illuminated.";
CM_ SG_ 2565865726 EngCoolantLoadIncrease "Status of an event, external to the engine, that may increase the nominal temperature of the engine coolant liquid.";
CM_ SG_ 2565865726 IntendedRetarderPercentTorque "Braking torque of retarder that the retarder is currently trying to achieve.";
CM_ SG_ 2565865726 ActualRetarderPercentTorque "Actual braking torque of the retarder as a percent of retarder configuration reference torque SPN 556.";
CM_ SG_ 2565865726 RetarderEnableShiftAssistSwitch "Switch signal which indicates whether the operator wishes the retarder to be enabled for transmission shift assist.";
CM_ SG_ 2565865726 RetarderEnableBrakeAssistSwitch "Switch signal which indicates whether the operator wishes the retarder to be enabled for vehicle braking assist.";
CM_ SG_ 2565865726 RetarderTorqueMode "State signal which indicates which retarder torque mode is currently generating, limiting, or controlling the torque.";
CM_ BO_ 2633932798 "Exhaust Port Temperature 5";
CM_ SG_ 2633932798 EngExhaustGasPort20Temp "Temperature at the cylinder exhaust port of the engine.";
CM_ SG_ 2633932798 EngExhaustGasPort19Temp "Temperature at the cylinder exhaust port of the engine.";
CM_ SG_ 2633932798 EngExhaustGasPort18Temp "Temperature at the cylinder exhaust port of the engine.";
CM_ SG_ 2633932798 EngExhaustGasPort17Temp "Temperature at the cylinder exhaust port of the engine.";
CM_ BO_ 2566824190 "Exhaust Port Temperature 4";
CM_ SG_ 2566824190 EngExhaustGasPort16Temp "Temperature at the cylinder exhaust port of the engine.";
CM_ SG_ 2566824190 EngExhaustGasPort15Temp "Temperature at the cylinder exhaust port of the engine.";
CM_ SG_ 2566824190 EngExhaustGasPort14Temp "Temperature at the cylinder exhaust port of the engine.";
CM_ SG_ 2566824190 EngExhaustGasPort13Temp "Temperature at the cylinder exhaust port of the engine.";
CM_ BO_ 2633933310 "Exhaust Port Temperature 3";
CM_ SG_ 2633933310 EngExhaustGasPort12Temp "Temperature at the cylinder exhaust port of the engine.";
CM_ SG_ 2633933310 EngExhaustGasPort11Temp "Temperature at the cylinder exhaust port of the engine.";
CM_ SG_ 2633933310 EngExhaustGasPort10Temp "Temperature at the cylinder exhaust port of the engine.";
CM_ SG_ 2633933310 EngExhaustGasPort9Temp "Temperature at the cylinder exhaust port of the engine.";
CM_ BO_ 2633933566 "Exhaust Port Temperature 2";
CM_ SG_ 2633933566 EngExhaustGasPort8Temp "Temperature at the cylinder exhaust port of the engine.";
CM_ SG_ 2633933566 EngExhaustGasPort7Temp "Temperature at the cylinder exhaust port of the engine.";
CM_ SG_ 2633933566 EngExhaustGasPort6Temp "Temperature at the cylinder exhaust port of the engine.";
CM_ SG_ 2633933566 EngExhaustGasPort5Temp "Temperature at the cylinder exhaust port of the engine.";
CM_ BO_ 2633933822 "Exhaust Port Temperature 1";
CM_ SG_ 2633933822 EngExhaustGasPort4Temp "Temperature at the cylinder exhaust port of the engine.";
CM_ SG_ 2633933822 EngExhaustGasPort3Temp "Temperature at the cylinder exhaust port of the engine.";
CM_ SG_ 2633933822 EngExhaustGasPort2Temp "Temperature at the cylinder exhaust port of the engine.";
CM_ SG_ 2633933822 EngExhaustGasPort1Temp "Temperature at the cylinder exhaust port of the engine.";
CM_ BO_ 2566776062 "Equipment Performance Data";
CM_ SG_ 2566776062 PayloadPercentage "The current payload of the equipment, reported as a percentage of the equipment's rated payload limit.";
CM_ BO_ 2566771454 "ECU Performance";
CM_ SG_ 2566771454 DataMemoryUsage "The used storage capacity of the data buffer memory internal to an ECU, such as a data logger.";
CM_ SG_ 2566771454 KeepAliveBatteryConsumption "The capacity consumed from the direct battery connection since the key was last turned off.";
CM_ BO_ 2566775806 "Equipment Operation and Control";
CM_ SG_ 2566775806 TravelVelocityCtrlPos "The position of the travel velocity control component reported as a percentage of the control's full displacement in each";
CM_ BO_ 2633935358 "Exhaust Oxygen 1";
CM_ SG_ 2633935358 EngExhstGsOxygnSnsrClsdLpOprton "Indicates whether the engine is using the Exhaust Gas Oxygen sensor to control the air/fuel ratio.";
CM_ SG_ 2633935358 EngExhstGsOxygnSnsrFlngCrrction "The amount of fueling change required by the system based on the measured Exhaust Oxygen value compared to the";
CM_ SG_ 2633935358 EngActualExhaustOxygen "The actual amount of oxygen in the exhaust represented as a percentage by volume with respect to the total volume of";
CM_ SG_ 2633935358 EngDesiredExhaustOxygen "The desired amount of oxygen in the exhaust represented as a percentage by volume with respect to the total volume of";
CM_ SG_ 2633935358 EngDesiredRatedExhaustOxygen "The desired amount of oxygen in the exhaust at rated conditions represented as a percentage by volume with respect to";
CM_ BO_ 2365447166 "Extended Joystick Message 3";
CM_ SG_ 2365447166 Jystck3GripXAxisDetentPosStatus "Reports when the current joystick grip position is in the detent position for that axis of travel.";
CM_ SG_ 2365447166 Jystck3GripYAxisDetentPosStatus "Reports when the current joystick grip position is in the detent position for that axis of travel.";
CM_ SG_ 2365447166 Jystck3ThetaAxisDetentPosStatus "Reports when the current joystick position is in the detent position for that axis of travel.";
CM_ SG_ 2365447166 Joystick3ThetaAxisPos "The position of the joystick in the relative motion of travel from the neutral position.";
CM_ SG_ 2365447166 Jystck3ThtAxsClckwsPstvPsStatus "Reports when the current joystick position is on the positive travel side (forward, right, clockwise, up) relative to the";
CM_ SG_ 2365447166 Jystck3ThtaAxisNeutralPosStatus "Reports when the current joystick position is in the neutral position for that axis of travel.";
CM_ SG_ 2365447166 Joystick3GripYAxisPos "The position of the joystick grip in the relative motion of travel from the neutral position.";
CM_ SG_ 2365447166 Jystck3GrpYAxsLvrFrwrdPstvPsStts "Reports when the current joystick grip position is on the positive travel side (forward, right, clockwise, up) relative to the";
CM_ SG_ 2365447166 Jystck3GrpYAxsLvrBckNgtvPsSttus "Reports when the current joystick grip position is on the negative travel side (back, left, counterclockwise, down) relative";
CM_ SG_ 2365447166 Jystck3GrpYAxisNeutralPosStatus "Reports when the current joystick grip position is in the neutral position for that axis of travel.";
CM_ SG_ 2365447166 Joystick3GripXAxisPos "The position of the joystick grip in the relative motion of travel from the neutral position.";
CM_ SG_ 2365447166 Jystck3GrpXAxsLvrRghtPstvPsStts "Reports when the current joystick grip position is on the positive travel side (forward, right, clockwise, up) relative to the";
CM_ SG_ 2365447166 Jystck3GrpXAxsLvrLftNgtvPsSttus "Reports when the current joystick grip position is on the negative travel side (back, left, counterclockwise, down) relative";
CM_ SG_ 2365447166 Jystck3GrpXAxisNeutralPosStatus "Reports when the current joystick grip position is in the neutral position for that axis of travel.";
CM_ SG_ 2365447166 Jystck3ThtAxsCntrClckwsNgtvPsStt "Reports when the current joystick position is on the negative travel side (back, left, counterclockwise, down) relative to the";
CM_ BO_ 2365446654 "Extended Joystick Message 2";
CM_ SG_ 2365446654 Jystck2GripXAxisDetentPosStatus "Reports when the current joystick grip position is in the detent position for that axis of travel.";
CM_ SG_ 2365446654 Jystck2GripYAxisDetentPosStatus "Reports when the current joystick grip position is in the detent position for that axis of travel.";
CM_ SG_ 2365446654 Jystck2ThetaAxisDetentPosStatus "Reports when the current joystick position is in the detent position for that axis of travel.";
CM_ SG_ 2365446654 Joystick2ThetaAxisPos "The position of the joystick in the relative motion of travel from the neutral position.";
CM_ SG_ 2365446654 Jystck2ThtAxsClckwsPstvPsStatus "Reports when the current joystick position is on the positive travel side (forward, right, clockwise, up) relative to the";
CM_ SG_ 2365446654 Jystck2ThtaAxisNeutralPosStatus "Reports when the current joystick position is in the neutral position for that axis of travel.";
CM_ SG_ 2365446654 Joystick2GripYAxisPos "The position of the joystick grip in the relative motion of travel from the neutral position.";
CM_ SG_ 2365446654 Jystck2GrpYAxsLvrFrwrdPstvPsStts "Reports when the current joystick grip position is on the positive travel side (forward, right, clockwise, up) relative to the";
CM_ SG_ 2365446654 Jystck2GrpYAxsLvrBckNgtvPsSttus "Reports when the current joystick grip position is on the negative travel side (back, left, counterclockwise, down) relative";
CM_ SG_ 2365446654 Jystck2GrpYAxisNeutralPosStatus "Reports when the current joystick grip position is in the neutral position for that axis of travel.";
CM_ SG_ 2365446654 Joystick2GripXAxisPos "The position of the joystick grip in the relative motion of travel from the neutral position.";
CM_ SG_ 2365446654 Jystck2GrpXAxsLvrRghtPstvPsStts "Reports when the current joystick grip position is on the positive travel side (forward, right, clockwise, up) relative to the";
CM_ SG_ 2365446654 Jystck2GrpXAxsLvrLftNgtvPsSttus "Reports when the current joystick grip position is on the negative travel side (back, left, counterclockwise, down) relative";
CM_ SG_ 2365446654 Jystck2GrpXAxisNeutralPosStatus "Reports when the current joystick grip position is in the neutral position for that axis of travel.";
CM_ SG_ 2365446654 Jystck2ThtAxsCntrClckwsNgtvPsStt "Reports when the current joystick position is on the negative travel side (back, left, counterclockwise, down) relative to the";
CM_ BO_ 2365446142 "Extended Joystick Message 1";
CM_ SG_ 2365446142 Jystck1GripXAxisDetentPosStatus "Reports when the current joystick grip position is in the detent position for that axis of travel.";
CM_ SG_ 2365446142 Jystck1GripYAxisDetentPosStatus "Reports when the current joystick grip position is in the detent position for that axis of travel.";
CM_ SG_ 2365446142 Jystck1ThetaAxisDetentPosStatus "Reports when the current joystick position is in the detent position for that axis of travel.";
CM_ SG_ 2365446142 Joystick1ThetaAxisPos "The position of the joystick in the relative motion of travel from the neutral position.";
CM_ SG_ 2365446142 Jystck1ThtAxsClckwsPstvPsStatus "Reports when the current joystick position is on the positive travel side (forward, right, clockwise, up) relative to the";
CM_ SG_ 2365446142 Jystck1ThtaAxisNeutralPosStatus "Reports when the current joystick position is in the neutral position for that axis of travel.";
CM_ SG_ 2365446142 Joystick1GripYAxisPos "The position of the joystick grip in the relative motion of travel from the neutral position.";
CM_ SG_ 2365446142 Jystck1GrpYAxsLvrFrwrdPstvPsStts "Reports when the current joystick grip position is on the positive travel side (forward, right, clockwise, up) relative to the";
CM_ SG_ 2365446142 Jystck1GrpYAxsLvrBckNgtvPsSttus "Reports when the current joystick grip position is on the negative travel side (back, left, counterclockwise, down) relative";
CM_ SG_ 2365446142 Jystck1GrpYAxisNeutralPosStatus "Reports when the current joystick grip position is in the neutral position for that axis of travel.";
CM_ SG_ 2365446142 Joystick1GripXAxisPos "The position of the joystick grip in the relative motion of travel from the neutral position.";
CM_ SG_ 2365446142 Jystck1GrpXAxsLvrRghtPstvPsStts "Reports when the current joystick grip position is on the positive travel side (forward, right, clockwise, up) relative to the";
CM_ SG_ 2365446142 Jystck1GrpXAxsLvrLftNgtvPsSttus "Reports when the current joystick grip position is on the negative travel side (back, left, counterclockwise, down) relative";
CM_ SG_ 2365446142 Jystck1GrpXAxisNeutralPosStatus "Reports when the current joystick grip position is in the neutral position for that axis of travel.";
CM_ SG_ 2365446142 Jystck1ThtAxsCntrClckwsNgtvPsStt "Reports when the current joystick position is on the negative travel side (back, left, counterclockwise, down) relative to the";
CM_ BO_ 2633929470 "Engine Information";
CM_ SG_ 2633929470 EngFuelRackPos "Measured position of the engine fuel rack.";
CM_ SG_ 2633929470 EngGasMassFlowRate1 "Gas mass flow rate delivered to an engine through its first fuel control system.";
CM_ SG_ 2633929470 InstantaneousEstBrakePower "Estimate of the power developed by the engine.";
CM_ SG_ 2633929470 EngExhaustGasPress "Gage pressure of the exhaust gasses as measured at the turbine intake of the turbocharger.";
CM_ SG_ 2633929470 EngPrefilterOilPress "Gage pressure of the engine oil before the oil reaches the oil filter.";
CM_ BO_ 2633937406 "ECU History";
CM_ SG_ 2633937406 TotalECURunTime "Total time accumulated over the life of the ECU, from ignition switch ON to ignition switch OFF.";
CM_ SG_ 2633937406 TotalECUDistance "Total distance accumulated over the life of the ECU.";
CM_ BO_ 2364541694 "Engine Gas Flow Rate";
CM_ SG_ 2364541694 EngIntakeAirMassFlowRate "Mass flow rate of fresh air entering the engine air intake, before any EGR mixer, if used.";
CM_ SG_ 2364541694 EngExhstGsRcrclton2MassFlowRate "Flow rate of gas through the second EGR system.";
CM_ SG_ 2364541694 EngExhstGsRcrclton1MassFlowRate "Flow rate of gas through the EGR system.";
CM_ BO_ 2566810366 "Engine Fuel/lube systems";
CM_ SG_ 2566810366 FuelPumpPrimerStatus "Parameter used to transmit the actual status of the fuel priming system.";
CM_ SG_ 2566810366 EngFuelSupplyPumpIntakePress "Absolute pressure of fuel at the fuel supply pump intake.";
CM_ SG_ 2566810366 EngFuelFilterDiffPress "Differential pressure measured across the fuel filter located between the fuel tank and the supply pump.";
CM_ SG_ 2566810366 EngOilLevelRemoteReservoir "Ratio of current volume of engine oil in a remote reservoir to the maximum required volume.";
CM_ SG_ 2566810366 EngWasteOilReservoirLevel "Level of crankcase blowby emulsion collected by a container.";
CM_ SG_ 2566810366 EngVentilationStatus "Engine ventilation control states.";
CM_ SG_ 2566810366 EngOilPrimingState "Determination of whether or not the engine is (or has recently been) sufficiently lubricated for starting purposes.";
CM_ SG_ 2566810366 EngOilPrimingPumpSwitch "Switch input for activating the engine oil priming pump.";
CM_ SG_ 2566810366 EngOilPreHeatedState "Indicates whether the engine oil pre-heated sufficiently for starting purposes.";
CM_ SG_ 2566810366 EngOilFilterOutletPress "Oil pressure (gauge) measured just downstream of oil filter.";
CM_ SG_ 2566810366 EngCoolantPreheatedState "Indicates whether the engine coolant is pre-heated sufficiently for starting purposes.";
CM_ BO_ 2566767102 "Engine Fluid Level/Pressure 3";
CM_ SG_ 2566767102 EngExhstVlvActtonSystemOilPress "The absolute pressure of the oil in the hydraulic system that powers the engine exhaust valve actuation system";
CM_ SG_ 2566767102 EngExhstGsRcrcltion1OutletPress "EGR outlet pressure is measured immediately after the EGR valve.";
CM_ SG_ 2566767102 EngExhstGsRcrcltion1IntakePress "EGR intake gage pressure is measured after the EGR cooler and before the EGR valve.";
CM_ SG_ 2566767102 EngIntkVlvActtionSystemOilPress "The gage pressure of the oil in the hydraulic system that powers the engine intake valve actuation system";
CM_ BO_ 2566839294 "Engine Fluid Level/Pressure 2";
CM_ SG_ 2566839294 EngInjectorMeteringRail2Press "The gage pressure of fuel in the metering rail #2 as delivered from the supply pump to the injector metering intake.";
CM_ SG_ 2566839294 EngInjectorTimingRail1Press "The gage pressure of fuel in the timing rail delivered from the supply pump to the injector timing intake.";
CM_ SG_ 2566839294 EngInjectorMeteringRail1Press "The gage pressure of fuel in the primary, or first, metering rail as delivered from the supply pump to the injector metering";
CM_ SG_ 2566839294 EngInjectionCtrlPress "The gage pressure of the engine oil in the hydraulic accumulator that powers an intensifier used for fuel injection.";
CM_ BO_ 2566844414 "Engine Fluid Level/Pressure 1";
CM_ SG_ 2566844414 EngCoolantLevel "Ratio of volume of liquid found in engine cooling system to total cooling system volume.";
CM_ SG_ 2566844414 EngCoolantPress "Gage pressure of liquid found in engine cooling system.";
CM_ SG_ 2566844414 EngCrankcasePress "Gage pressure inside engine crankcase.";
CM_ SG_ 2566844414 EngOilPress "Gage pressure of oil in engine lubrication system as provided by oil pump.";
CM_ SG_ 2566844414 EngOilLevel "Ratio of current volume of engine sump oil to maximum required volume.";
CM_ SG_ 2566844414 EngExCrankcaseBlowbyPress "Differential crankcase blow-by pressure as measured through a tube with a venturi.";
CM_ SG_ 2566844414 EngFuelDeliveryPress "Gage pressure of fuel in system as delivered from supply pump to the injection pump.";
CM_ BO_ 2633929726 "Engine Electrical System/Module Information";
CM_ SG_ 2633929726 TurningGearEngaged "Status signal which indicates that the turning gear is engaged.";
CM_ SG_ 2633929726 SafetyWireStatus "Status signal which indicates that the safety wire has been activated.";
CM_ SG_ 2633929726 ElectricalLoad "Electrical power delivered by the engine to the electrical system connected to the generator.";
CM_ BO_ 2566772222 "Electronic Engine Controller 5";
CM_ SG_ 2566772222 EngVrableGeometryTurbo1CtrlMode "Indicates if the variable geometry turbocharger control status is either open loop or closed loop.";
CM_ SG_ 2566772222 EngTrb1ClcltedTurbineIntakeTemp "Calculated value of turbine intake temperature based on engine operating conditions, such as intake manifold";
CM_ SG_ 2566772222 EngExhstGsRcrculation1ValveCtrl "Desired percentage of maximum Exhaust Gas Recirculation (EGR) valve opening.";
CM_ SG_ 2566772222 EngVrblGometryTurbo1ActuatorPos "Sensor that measures the position of the variable geometry turbocharger actuator.";
CM_ SG_ 2566772222 EngVrblGmtryTrbArCtrlShtffValve "Isolates vehicle brake air from the Variable Geometry Turbocharger (VGT) system when engine is not running.";
CM_ SG_ 2566772222 EngTrb1ClcltedTurbineOutletTemp "Calculated value of turbocharger compressor outlet air temperature.";
CM_ BO_ 2633940734 "Electronic Engine Controller 4";
CM_ SG_ 2633940734 EngRotationDirection "Direction of engine rotation, as reported by the engine.";
CM_ SG_ 2633940734 CrnkAttmptCntOnPrsntStrtAttempt "Reports the number of cranking cycles undergone during the present start attempt.";
CM_ SG_ 2633940734 EngIntakeManifoldPressCtrlMode "Indicates that the Boost Pressure Closed Loop Control status either open loop or closed loop.";
CM_ SG_ 2633940734 EngRatedSpeed "The maximum governed rotational velocity of the engine crankshaft under full load conditions.";
CM_ SG_ 2633940734 EngRatedPower "Net brake power that the engine will deliver continuously, specified for a given application at a rated speed.";
CM_ BO_ 2566840318 "Electronic Engine Controller 3";
CM_ SG_ 2566840318 EngsDsrdOprtngSpdAsymmtryAdjstmn "This byte is utilized in transmission gear selection routines and indicates the engine's preference of lower versus higher";
CM_ SG_ 2566840318 Aftrtratment1ExhaustGasMassFlow "Measured/calculated exhaust gas mass upstream of the aftertreatment system in exhaust bank 1 and 2.";
CM_ SG_ 2566840318 Aftertreatment2IntakeDewPoint "Indicates that the temperature on the intake side of the aftertreatment system has exceeded the dew point, as estimated";
CM_ SG_ 2566840318 Aftertreatment2ExhaustDewPoint "Indicates that the temperature on the exhaust side of the aftertreatment has exceeded the dew point, as estimated by the";
CM_ SG_ 2566840318 Aftertreatment1IntakeDewPoint "Indicates that the temperature on the intake side of the aftertreatment system has exceeded the dew point, as estimated";
CM_ SG_ 2566840318 Aftertreatment1ExhaustDewPoint "Indicates that the temperature on the exhaust side of the aftertreatment has exceeded the dew point, as estimated by the";
CM_ SG_ 2566840318 EstEngPrsticLossesPercentTorque "The calculated torque that indicates the estimated amount of torque loss due to engine parasitics, such as cooling fan, air";
CM_ SG_ 2566840318 EngsDesiredOperatingSpeed "An indication by the engine of the optimal operating speed of the engine for the current existing conditions.";
CM_ SG_ 2566840318 NominalFrictionPercentTorque "The calculated torque that indicates the amount of torque required by the basic engine itself added by the loss torque of";
CM_ BO_ 2364539902 "Electronic Engine Controller 2";
CM_ SG_ 2364539902 SCRThermalManagementActive "Indicates that the exhaust temperatures have been elevated for regeneration of the SCR aftertreatment system or in";
CM_ SG_ 2364539902 MmntryEngMaxPowerEnableFeedback "Momentarily requesting Engine Maximum Power Enable - feature support feedback";
CM_ SG_ 2364539902 EstPumpingPercentTorque "The calculated torque that indicates the estimated amount of torque loss due to the engine air handling system.";
CM_ SG_ 2364539902 DPFThermalManagementActive "Indicates that the exhaust temperatures have been elevated for regeneration of the diesel particulate filter aftertreatment";
CM_ SG_ 2364539902 ActlMxAvailableEngPercentTorque "This is the maximum amount of torque that the engine can immediately deliver as a percentage of the reference engine";
CM_ SG_ 2364539902 AccelPedalPos2 "The ratio of actual position of the second analog engine speed/torque request input device (such as an accelerator pedal";
CM_ SG_ 2364539902 VhclAccelerationRateLimitStatus "Status (active or not active) of the system used to limit maximum forward vehicle acceleration.";
CM_ SG_ 2364539902 EngPercentLoadAtCurrentSpeed "The ratio of actual engine percent torque (indicated) to maximum indicated torque available at the current engine speed,";
CM_ SG_ 2364539902 AccelPedal2LowIdleSwitch "Switch signal which indicates the state of the accelerator pedal 2 low idle switch.";
CM_ SG_ 2364539902 RoadSpeedLimitStatus "Status (active or not active) of the system used to limit maximum vehicle velocity.";
CM_ SG_ 2364539902 AccelPedalKickdownSwitch "Switch signal which indicates whether the accelerator pedal kickdown switch is opened or closed.";
CM_ SG_ 2364539902 AccelPedal1LowIdleSwitch "Switch signal which indicates the state of the accelerator pedal 1 low idle switch.";
CM_ SG_ 2364539902 RemoteAccelPedalPos "The ratio of actual position of the remote analog engine speed/torque request input device (such as an accelerator pedal";
CM_ SG_ 2364539902 AccelPedalPos1 "The ratio of actual position of the analog engine speed/torque request input device (such as an accelerator pedal or";
CM_ BO_ 2364540158 "Electronic Engine Controller 1";
CM_ SG_ 2364540158 SrcAddrssOfCtrllngDvcFrEngCntrl "The source address of the SAE J1939 device currently controlling the engine.";
CM_ SG_ 2364540158 ActlEngPrcntTrqueHighResolution "This parameter displays an additional torque in percent of the reference engine torque.";
CM_ SG_ 2364540158 EngDemandPercentTorque "The requested torque output of the engine by all dynamic internal inputs, including smoke control, noise control and low";
CM_ SG_ 2364540158 EngStarterMode "There are several phases in a starting action and different reasons why a start cannot take place.";
CM_ SG_ 2364540158 EngSpeed "Actual engine speed which is calculated over a minimum crankshaft angle of 720 degrees divided by the number of cylinders.";
CM_ SG_ 2364540158 ActualEngPercentTorque "The calculated output torque of the engine.";
CM_ SG_ 2364540158 DriversDemandEngPercentTorque "The requested torque output of the engine by the driver.";
CM_ SG_ 2364540158 EngTorqueMode "State signal which indicates which engine torque mode is currently generating, limiting, or controlling the torque.";
CM_ BO_ 2566768126 "ECU Identification Information";
CM_ BO_ 2566804734 "Engine Continuous Torque & Speed Limit";
CM_ SG_ 2566804734 EngLwLmtThrshldFrMxTrqFrmEngine "Minimum allowable value for maximum continuous torque from engine";
CM_ SG_ 2566804734 EngLwLmtThrshldFrMxRPMFrmEngine "Minimum allowable value for maximum continuous RPM from engine";
CM_ SG_ 2566804734 EngHghLmtThrshldFrMnCntnsTrqFrmE "Maximum allowable value for minimum continuous torque from engine";
CM_ SG_ 2566804734 EngHghLmtThrshldFrMnCntnsEngnRPM "Maximum allowable value for minimum continuous RPM from engine";
CM_ SG_ 2566804734 EngMinContinuousTorque "Applied limit for minimum continuous engine torque";
CM_ SG_ 2566804734 EngMaxContinuousTorque "Applied limit for maximum continuous engine torque.";
CM_ SG_ 2566804734 EngMinContinuousRPM "Applied limit for minimum continuous engine RPM";
CM_ SG_ 2566804734 EngMaxContinuousRPM "Applied limit for maximum continuous engine RPM";
CM_ BO_ 2566767870 "Electronic Brake Controller 5";
CM_ SG_ 2566767870 BrakeTempWarning "This parameter indicates if the temperature in the service brakes exceeds a certain value.";
CM_ SG_ 2566767870 PrkngBrkeActuatorFullyActivated "Signal which indicates when the parking brake actuator is fully activated.";
CM_ SG_ 2566767870 XBRAccelerationLimit "The brake system may temporarily or generally limit the maximum brake performance available for external systems.";
CM_ SG_ 2566767870 XBRActiveCtrlMode "This parameter indicates which XBR Control Mode is executed by the brake system.";
CM_ SG_ 2566767870 XBRSystemState "This parameter indicates which external brake control is allowed.";
CM_ SG_ 2566767870 FoundationBrakeUse "This parameter indicates if the brake system presently uses the foundation brakes.";
CM_ SG_ 2566767870 HillHolderMode "Signal which indicates the current mode of the hill holder function.";
CM_ SG_ 2566767870 HaltBrakeMode "Signal which indicates the current mode of the halt brake function.";
CM_ BO_ 2633936126 "Wheel Brake Lining Remaining Information";
CM_ SG_ 2633936126 BrkLnngRmnngRearAxle3RightWheel "The percentage of brake lining which can still be measured for the right wheel on the rear axle #3.";
CM_ SG_ 2633936126 BrkLnngRmningRearAxle3LeftWheel "The percentage of brake lining which can still be measured for the left wheel on the rear axle #3.";
CM_ SG_ 2633936126 BrkLnngRmnngRearAxle2RightWheel "The percentage of brake lining which can still be measured for the right wheel on the rear axle #2.";
CM_ SG_ 2633936126 BrkLnngRmningRearAxle2LeftWheel "The percentage of brake lining which can still be measured for the left wheel on the rear axle #2.";
CM_ SG_ 2633936126 BrkLnngRmnngRearAxle1RightWheel "The percentage of brake lining which can still be measured for the right wheel on the rear axle #1.";
CM_ SG_ 2633936126 BrkLnngRmningRearAxle1LeftWheel "The percentage of brake lining which can still be measured for the left wheel on the rear axle #1.";
CM_ SG_ 2633936126 BrkLnngRmnngFrontAxleRightWheel "The percentage of brake lining which can still be measured for the right wheel on the front axle.";
CM_ SG_ 2633936126 BrkLnngRmningFrontAxleLeftWheel "The percentage of brake lining which can still be measured for the left wheel on the front axle.";
CM_ BO_ 2566827518 "Wheel Application Pressure High Range Information";
CM_ SG_ 2566827518 BrkAppPrssHghRngRrAxl3RghtWheel "The brake application pressure for the right wheel on the rear axle #3.";
CM_ SG_ 2566827518 BrkAppPrssHghRngRrAxl3LeftWheel "The brake application pressure for the left wheel on the rear axle #3.";
CM_ SG_ 2566827518 BrkAppPrssHghRngRrAxl2RghtWheel "The brake application pressure for the right wheel on the rear axle #2.";
CM_ SG_ 2566827518 BrkAppPrssHghRngRrAxl2LeftWheel "The brake application pressure for the left wheel on the rear axle #2.";
CM_ SG_ 2566827518 BrkAppPrssHghRngRrAxl1RghtWheel "The brake application pressure for the right wheel on the rear axle #1.";
CM_ SG_ 2566827518 BrkAppPrssHghRngRrAxl1LeftWheel "The brake application pressure for the left wheel on the rear axle #1.";
CM_ SG_ 2566827518 BrkAppPrssHghRngFrntAxlRghtWhel "The brake application pressure for the right wheel on the front axle.";
CM_ SG_ 2566827518 BrkAppPrssHghRngFrntAxlLftWheel "The brake application pressure for the left wheel on the front axle.";
CM_ BO_ 2566832126 "Wheel Speed Information";
CM_ SG_ 2566832126 RlativeSpeedRearAxle2RightWheel "The speed of the rear axle #2, right wheel relative to the front axle speed, SPN 904.";
CM_ SG_ 2566832126 RelativeSpeedRearAxle2LeftWheel "The speed of the rear axle #2, left wheel relative to the front axle speed, SPN 904.";
CM_ SG_ 2566832126 RlativeSpeedRearAxle1RightWheel "The speed of the rear axle #1, right wheel relative to the front axle speed, SPN 904.";
CM_ SG_ 2566832126 RelativeSpeedRearAxle1LeftWheel "The speed of the rear axle #1, left wheel relative to the front axle speed, SPN 904.";
CM_ SG_ 2566832126 RlativeSpeedFrontAxleRightWheel "The speed of the front axle, right wheel relative to the front axle speed, SPN 904.";
CM_ SG_ 2566832126 RelativeSpeedFrontAxleLeftWheel "The speed of the front axle, left wheel relative to the front axle speed, SPN 904.";
CM_ SG_ 2566832126 FrontAxleSpeed "The average speed of the two front wheels.";
CM_ BO_ 2565865982 "Electronic Brake Controller 1";
CM_ SG_ 2565865982 EngAuxShutdownSwitch "Switch signal which requests that all engine fueling stop.";
CM_ SG_ 2565865982 SrcAddrssOfCtrllngDvcFrBrkCntrl "The source address of the SAE J1939 device currently controlling the brake system.";
CM_ SG_ 2565865982 BrakePedalPos "Ratio of brake pedal position to maximum pedal position.";
CM_ SG_ 2565865982 TrctrMntdTrilerABSWarningSignal "This parameter commands the tractor-mounted trailer ABS optical warning signal.";
CM_ SG_ 2565865982 TrailerABSStatus "State signal which indicates that ABS in the trailer is actively controlling the brakes.";
CM_ SG_ 2565865982 HaltBrakeSwitch "Switch signal which indicates the position of the halt brake switch.";
CM_ SG_ 2565865982 ATC_ASRInformationSignal "This parameter commands the ATC/ASR driver information signal, for example a dash lamp.";
CM_ SG_ 2565865982 ABS_EBSAmberWarningSignal "This parameter commands the ABS/EBS amber/yellow optical warning signal";
CM_ SG_ 2565865982 EBSRedWarningSignal "This parameter commands the EBS red optical warning signal";
CM_ SG_ 2565865982 ABSFullyOperational "Signal which indicates whether an ABS system is fully operational or whether its functionality is reduced by a defect or by";
CM_ SG_ 2565865982 EngRetarderSelection "The position of the operator controlled selector, expressed as a percentage and determined by the ratio of the current";
CM_ SG_ 2565865982 RemoteAccelEnableSwitch "Switch signal which indicates that the remote accelerator has been enabled and controls the engine.";
CM_ SG_ 2565865982 EngDerateSwitch "Switch signal used to activate the torque limiting feature of the engine.";
CM_ SG_ 2565865982 AccelInterlockSwitch "Switch signal used to disable the accelerator and remote accelerator inputs, causing the engine to return to idle.";
CM_ SG_ 2565865982 TractionCtrlOverrideSwitch "Switch signal which indicates the position of the traction control override switch.";
CM_ SG_ 2565865982 ASRHillHolderSwitch "Switch signal which indicates the position of the ASR [hill holder] switch.";
CM_ SG_ 2565865982 ASROffroadSwitch "Switch signal which indicates the position of the ASR off-road switch.";
CM_ SG_ 2565865982 ABSOffroadSwitch "Switch signal which indicates the position of the ABS off-road switch.";
CM_ SG_ 2565865982 EBSBrakeSwitch "Switch signal which indicates that the brake pedal is being pressed.";
CM_ SG_ 2565865982 AntiLockBrakingActive "State signal which indicates that the ABS is active.";
CM_ SG_ 2565865982 ASRBrakeCtrlActive "State signal which indicates that ASR brake control is active.";
CM_ SG_ 2565865982 ASREngCtrlActive "State signal which indicates that ASR engine control has been commanded to be active.";
CM_ BO_ 2565867262 "Electronic Axle Controller 1";
CM_ SG_ 2565867262 RearAxleGroupEngagementStatus "Rear axle group engagement status";
CM_ SG_ 2565867262 FrontAxleGroupEngagementStatus "Front axle group engagement status";
CM_ SG_ 2565867262 DiffLockStateCentralRear "State used which indicates the condition of the central rear differential lock.";
CM_ SG_ 2565867262 DiffLockStateCentralFront "State used which indicates the condition of the central front differential lock.";
CM_ SG_ 2565867262 DiffLockStateCentral "State used which indicates the condition of the central differential lock.";
CM_ SG_ 2565867262 DiffLockStateRearAxle2 "State used which indicates the condition of the rear axle 2 differential lock.";
CM_ SG_ 2565867262 DiffLockStateRearAxle1 "State used which indicates the condition of the rear axle 1 differential lock.";
CM_ SG_ 2565867262 DiffLockStateFrontAxle2 "State used which indicates the condition of the front axle 2 differential lock.";
CM_ SG_ 2565867262 DiffLockStateFrontAxle1 "State used which indicates the condition of the front axle 1 differential lock.";
CM_ SG_ 2565867262 Location "To identify to which of several similar devices (such as tires or fuel tanks) the information applies.";
CM_ BO_ 2566821118 "Engine Auxiliary Coolant";
CM_ SG_ 2566821118 SeaWaterPumpOutletPress "Gauge pressure of liquid found at outlet of sea water pump in sea water cooling system.";
CM_ SG_ 2566821118 EngAuxCoolantTemp "Temperature of coolant found in the intercooler which is located after the turbocharger.";
CM_ SG_ 2566821118 EngAuxCoolantPress "Gage pressure of coolant found in the intercooler which is located after the turbocharger.";
CM_ BO_ 2566810622 "Driver's Identification";
CM_ BO_ 2566847742 "Dash Display";
CM_ SG_ 2566847742 FuelLevel2 "Ratio of volume of fuel to the total volume of fuel in the second or right-side storage container.";
CM_ SG_ 2566847742 FuelLevel1 "Ratio of volume of fuel to the total volume of fuel storage container.";
CM_ SG_ 2566847742 CargoAmbientTemp "Temperature of air inside vehicle container used to accommodate cargo.";
CM_ SG_ 2566847742 EngOilFilterDiffPress "Change in engine oil pressure, measured across the filter, due to the filter and any accumulation of solid or semisolid";
CM_ SG_ 2566847742 EngFuelFilterDiffPress "Differential pressure measured across the fuel filter located between the fuel tank and the supply pump.";
CM_ SG_ 2566847742 WasherFluidLevel "Ratio of volume of liquid to total container volume of fluid reservoir in windshield wash system.";
CM_ BO_ 2566768382 "Cold Start Aids";
CM_ SG_ 2566768382 EngStartEnableDevice2Config "The start enable device installed for start enable device 2.";
CM_ SG_ 2566768382 EngStartEnableDevice1Config "The start enable device installed for start enable device 1.";
CM_ SG_ 2566768382 EngStartEnableDevice2 "Devices that assist an engine in starting, e.";
CM_ SG_ 2566768382 EngStartEnableDevice1 "Devices that assist an Engine in starting, e.";
CM_ BO_ 2566811902 "Combination Vehicle Weight";
CM_ SG_ 2566811902 PoweredVehicleWeight "Total mass imposed by the tires of the powered vehicle on the road surface.";
CM_ SG_ 2566811902 GrossCombinationVehicleWeight "The total weight of the truck and all attached trailers.";
CM_ BO_ 2563768062 "Continuous Torque & Speed Limit Request";
CM_ SG_ 2563768062 MxCntnuousRetarderTorqueLimitRq "Requested maximum continuous retarder torque (operating range: -125 to 0%)";
CM_ SG_ 2563768062 MnCntnuousRetarderTorqueLimitRq "Requested minimum continuous retarder torque (operating range: -125 to 0%)";
CM_ SG_ 2563768062 MxCntinuousRetarderSpeedLimitRq "Requested maximum continuous retarder speed";
CM_ SG_ 2563768062 MnCntinuousRetarderSpeedLimitRq "Requested minimum continuous retarder speed";
CM_ SG_ 2563768062 EngTorqueLimitRqMaxContinuous "Requested maximum continuous engine torque (operating range: 0 to 125%)";
CM_ SG_ 2563768062 EngTorqueLimitRqMinContinuous "Requested minimum continuous engine torque (operating range: 0 to 125%)";
CM_ SG_ 2563768062 EngSpeedLimitRqMaxContinuous "Requested maximum continuous engine speed";
CM_ SG_ 2563768062 EngSpeedLimitRqMinContinuous "Requested minimum continuous engine speed";
CM_ BO_ 2633924862 "Combustion Time 6";
CM_ SG_ 2633924862 EngAverageCombustionTime "The average combustion time of all cylinders of an engine.";
CM_ SG_ 2633924862 EngDesiredCombustionTime "The desired combustion time based upon engine load and speed lookup maps.";
CM_ BO_ 2633924606 "Combustion Time 5";
CM_ SG_ 2633924606 EngCyl20CombustionTime "The amount of time from when the ignition of the fuel is initiated to when the fuel is completely ignited (i.";
CM_ SG_ 2633924606 EngCyl19CombustionTime "The amount of time from when the ignition of the fuel is initiated to when the fuel is completely ignited (i.";
CM_ SG_ 2633924606 EngCyl18CombustionTime "The amount of time from when the ignition of the fuel is initiated to when the fuel is completely ignited (i.";
CM_ SG_ 2633924606 EngCyl17CombustionTime "The amount of time from when the ignition of the fuel is initiated to when the fuel is completely ignited (i.";
CM_ BO_ 2633924350 "Combustion Time 4";
CM_ SG_ 2633924350 EngCyl16CombustionTime "The amount of time from when the ignition of the fuel is initiated to when the fuel is completely ignited (i.";
CM_ SG_ 2633924350 EngCyl15CombustionTime "The amount of time from when the ignition of the fuel is initiated to when the fuel is completely ignited (i.";
CM_ SG_ 2633924350 EngCyl14CombustionTime "The amount of time from when the ignition of the fuel is initiated to when the fuel is completely ignited (i.";
CM_ SG_ 2633924350 EngCyl13CombustionTime "The amount of time from when the ignition of the fuel is initiated to when the fuel is completely ignited (i.";
CM_ BO_ 2633924094 "Combustion Time 3";
CM_ SG_ 2633924094 EngCyl12CombustionTime "The amount of time from when the ignition of the fuel is initiated to when the fuel is completely ignited (i.";
CM_ SG_ 2633924094 EngCyl11CombustionTime "The amount of time from when the ignition of the fuel is initiated to when the fuel is completely ignited (i.";
CM_ SG_ 2633924094 EngCyl10CombustionTime "The amount of time from when the ignition of the fuel is initiated to when the fuel is completely ignited (i.";
CM_ SG_ 2633924094 EngCyl9CombustionTime "The amount of time from when the ignition of the fuel is initiated to when the fuel is completely ignited (i.";
CM_ BO_ 2633923838 "Combustion Time 2";
CM_ SG_ 2633923838 EngCyl8CombustionTime "The amount of time from when the ignition of the fuel is initiated to when the fuel is completely ignited (i.";
CM_ SG_ 2633923838 EngCyl7CombustionTime "The amount of time from when the ignition of the fuel is initiated to when the fuel is completely ignited (i.";
CM_ SG_ 2633923838 EngCyl6CombustionTime "The amount of time from when the ignition of the fuel is initiated to when the fuel is completely ignited (i.";
CM_ SG_ 2633923838 EngCyl5CombustionTime "The amount of time from when the ignition of the fuel is initiated to when the fuel is completely ignited (i.";
CM_ BO_ 2633923582 "Combustion Time 1";
CM_ SG_ 2633923582 EngCyl4CombustionTime "The amount of time from when the ignition of the fuel is initiated to when the fuel is completely ignited (i.";
CM_ SG_ 2633923582 EngCyl3CombustionTime "The amount of time from when the ignition of the fuel is initiated to when the fuel is completely ignited (i.";
CM_ SG_ 2633923582 EngCyl2CombustionTime "The amount of time from when the ignition of the fuel is initiated to when the fuel is completely ignited (i.";
CM_ SG_ 2633923582 EngCyl1CombustionTime "The amount of time from when the ignition of the fuel is initiated to when the fuel is completely ignited (i.";
CM_ BO_ 2633878014 "Electronic Control Module Information";
CM_ SG_ 2633878014 TotalCountOfConfigChangesMade "Total number of times changes have been made to any of the configurable parameters.";
CM_ BO_ 2566771966 "Cab Message 3";
CM_ SG_ 2566771966 TransOilLevelRq "Conveys operator or vehicle system desire for a transmission oil level reading to be taken.";
CM_ SG_ 2566771966 FifthWheelReleaseCtrl "Operator input used to release the fifth wheel.";
CM_ SG_ 2566771966 FfthWhlRlaseCtrlSecurityLockout "Operator's fifth wheel release control interlock.";
CM_ SG_ 2566771966 TransferCaseSelectorSwitch "Operator switch to select the condition of the transfer case.";
BA_DEF_ SG_  "SigType" ENUM  "Default","Range","RangeSigned","ASCII","Discrete","Control","ReferencePGN","DTC","StringDelimiter","StringLength","StringLengthControl";
BA_DEF_ SG_  "GenSigStartValue" INT 0 10000;
BA_DEF_ SG_  "GenSigSendType" ENUM  "Cyclic","OnWrite","reserved","OnChange","reserved","reserved","reserved","NoSigSendType";
BA_DEF_ SG_  "GenSigILSupport" ENUM  "Yes","No";
BA_DEF_ SG_  "GenSigEVName" STRING ;
BA_DEF_ SG_  "SPN" INT 0 524287;
BA_DEF_ BO_  "GenMsgStartDelayTime" INT 0 100000;
BA_DEF_ BO_  "GenMsgILSupport" ENUM  "Yes","No";
BA_DEF_ BO_  "GenMsgRequestable" INT 0 1;
BA_DEF_ BO_  "GenMsgSendType" ENUM  "cyclic","reserved","cyclicIfActive","reserved","reserved","reserved","reserved","reserved","noMsgSendType";
BA_DEF_ BO_  "VFrameFormat" ENUM  "StandardCAN","ExtendedCAN","reserved","J1939PG";
BA_DEF_ BO_  "GenMsgCycleTime" INT 0 3600000;
BA_DEF_ SG_  "SystemSignalLongSymbol" STRING ;
BA_DEF_DEF_  "SigType" "Default";
BA_DEF_DEF_  "GenSigStartValue" 0;
BA_DEF_DEF_  "GenSigSendType" "NoSigSendType";
BA_DEF_DEF_  "GenSigILSupport" "Yes";
BA_DEF_DEF_  "GenSigEVName" "Env@Nodename_@Signame";
BA_DEF_DEF_  "SPN" 0;
BA_DEF_DEF_  "GenMsgStartDelayTime" 0;
BA_DEF_DEF_  "GenMsgILSupport" "Yes";
BA_DEF_DEF_  "GenMsgRequestable" 1;
BA_DEF_DEF_  "GenMsgSendType" "noMsgSendType";
BA_DEF_DEF_  "VFrameFormat" "J1939PG";
BA_DEF_DEF_  "GenMsgCycleTime" 0;
BA_DEF_DEF_  "SystemSignalLongSymbol" "";
BA_ "GenMsgCycleTime" BO_ 2566774014 1000;
BA_ "GenMsgSendType" BO_ 2566774014 0;
BA_ "GenMsgCycleTime" BO_ 2566823166 1000;
BA_ "GenMsgSendType" BO_ 2566823166 0;
BA_ "GenMsgCycleTime" BO_ 2566823422 1000;
BA_ "GenMsgSendType" BO_ 2566823422 0;
BA_ "GenMsgCycleTime" BO_ 2566823678 1000;
BA_ "GenMsgSendType" BO_ 2566823678 0;
BA_ "GenMsgCycleTime" BO_ 2432595710 100;
BA_ "GenMsgSendType" BO_ 2432595710 0;
BA_ "GenMsgCycleTime" BO_ 2365486590 50;
BA_ "GenMsgSendType" BO_ 2365486590 0;
BA_ "GenMsgCycleTime" BO_ 2365485566 50;
BA_ "GenMsgSendType" BO_ 2365485566 0;
BA_ "GenMsgCycleTime" BO_ 2365486334 50;
BA_ "GenMsgSendType" BO_ 2365486334 0;
BA_ "GenMsgCycleTime" BO_ 2364542462 100;
BA_ "GenMsgSendType" BO_ 2364542462 0;
BA_ "GenMsgCycleTime" BO_ 2365486078 50;
BA_ "GenMsgSendType" BO_ 2365486078 0;
BA_ "GenMsgCycleTime" BO_ 2566845182 100;
BA_ "GenMsgSendType" BO_ 2566845182 0;
BA_ "GenMsgCycleTime" BO_ 2633883646 500;
BA_ "GenMsgSendType" BO_ 2633883646 0;
BA_ "GenMsgCycleTime" BO_ 2633880062 10000;
BA_ "GenMsgSendType" BO_ 2633880062 0;
BA_ "GenMsgCycleTime" BO_ 2566806526 100;
BA_ "GenMsgSendType" BO_ 2566806526 0;
BA_ "GenMsgCycleTime" BO_ 2431649790 50;
BA_ "GenMsgSendType" BO_ 2431649790 2;
BA_ "GenMsgCycleTime" BO_ 2633929214 1000;
BA_ "GenMsgSendType" BO_ 2633929214 0;
BA_ "GenMsgCycleTime" BO_ 2566831614 1000;
BA_ "GenMsgSendType" BO_ 2566831614 0;
BA_ "GenMsgCycleTime" BO_ 2364542206 20;
BA_ "GenMsgSendType" BO_ 2364542206 0;
BA_ "GenMsgCycleTime" BO_ 2566802174 100;
BA_ "GenMsgSendType" BO_ 2566802174 0;
BA_ "GenMsgCycleTime" BO_ 2565867006 100;
BA_ "GenMsgSendType" BO_ 2565867006 0;
BA_ "GenMsgCycleTime" BO_ 2364539646 10;
BA_ "GenMsgSendType" BO_ 2364539646 0;
BA_ "GenMsgCycleTime" BO_ 2566810110 1000;
BA_ "GenMsgSendType" BO_ 2566810110 0;
BA_ "GenMsgCycleTime" BO_ 2566825214 1000;
BA_ "GenMsgSendType" BO_ 2566825214 0;
BA_ "GenMsgCycleTime" BO_ 2566844158 1000;
BA_ "GenMsgSendType" BO_ 2566844158 0;
BA_ "GenMsgCycleTime" BO_ 2566785022 500;
BA_ "GenMsgSendType" BO_ 2566785022 0;
BA_ "GenMsgCycleTime" BO_ 2565868542 20;
BA_ "GenMsgSendType" BO_ 2565868542 0;
BA_ "GenMsgCycleTime" BO_ 2633941758 1000;
BA_ "GenMsgSendType" BO_ 2633941758 2;
BA_ "GenMsgCycleTime" BO_ 2565865726 100;
BA_ "GenMsgSendType" BO_ 2565865726 0;
BA_ "GenMsgCycleTime" BO_ 2633932798 1000;
BA_ "GenMsgSendType" BO_ 2633932798 0;
BA_ "GenMsgCycleTime" BO_ 2566824190 1000;
BA_ "GenMsgSendType" BO_ 2566824190 0;
BA_ "GenMsgCycleTime" BO_ 2633933310 1000;
BA_ "GenMsgSendType" BO_ 2633933310 0;
BA_ "GenMsgCycleTime" BO_ 2633933566 1000;
BA_ "GenMsgSendType" BO_ 2633933566 0;
BA_ "GenMsgCycleTime" BO_ 2633933822 1000;
BA_ "GenMsgSendType" BO_ 2633933822 0;
BA_ "GenMsgCycleTime" BO_ 2566776062 500;
BA_ "GenMsgSendType" BO_ 2566776062 0;
BA_ "GenMsgCycleTime" BO_ 2566775806 250;
BA_ "GenMsgSendType" BO_ 2566775806 0;
BA_ "GenMsgCycleTime" BO_ 2365447166 100;
BA_ "GenMsgSendType" BO_ 2365447166 0;
BA_ "GenMsgCycleTime" BO_ 2365446654 100;
BA_ "GenMsgSendType" BO_ 2365446654 0;
BA_ "GenMsgCycleTime" BO_ 2365446142 100;
BA_ "GenMsgSendType" BO_ 2365446142 0;
BA_ "GenMsgCycleTime" BO_ 2633929470 100;
BA_ "GenMsgSendType" BO_ 2633929470 0;
BA_ "GenMsgCycleTime" BO_ 2364541694 50;
BA_ "GenMsgSendType" BO_ 2364541694 0;
BA_ "GenMsgCycleTime" BO_ 2566810366 500;
BA_ "GenMsgSendType" BO_ 2566810366 0;
BA_ "GenMsgCycleTime" BO_ 2566767102 500;
BA_ "GenMsgSendType" BO_ 2566767102 0;
BA_ "GenMsgCycleTime" BO_ 2566839294 500;
BA_ "GenMsgSendType" BO_ 2566839294 0;
BA_ "GenMsgCycleTime" BO_ 2566844414 500;
BA_ "GenMsgSendType" BO_ 2566844414 0;
BA_ "GenMsgCycleTime" BO_ 2633929726 100;
BA_ "GenMsgSendType" BO_ 2633929726 0;
BA_ "GenMsgCycleTime" BO_ 2566840318 250;
BA_ "GenMsgSendType" BO_ 2566840318 0;
BA_ "GenMsgCycleTime" BO_ 2364539902 50;
BA_ "GenMsgSendType" BO_ 2364539902 0;
BA_ "GenMsgCycleTime" BO_ 2364540158 100;
BA_ "GenMsgSendType" BO_ 2364540158 0;
BA_ "GenMsgCycleTime" BO_ 2566804734 5000;
BA_ "GenMsgSendType" BO_ 2566804734 0;
BA_ "GenMsgCycleTime" BO_ 2566767870 100;
BA_ "GenMsgSendType" BO_ 2566767870 0;
BA_ "GenMsgCycleTime" BO_ 2566827518 100;
BA_ "GenMsgSendType" BO_ 2566827518 0;
BA_ "GenMsgCycleTime" BO_ 2566832126 100;
BA_ "GenMsgSendType" BO_ 2566832126 0;
BA_ "GenMsgCycleTime" BO_ 2565865982 100;
BA_ "GenMsgSendType" BO_ 2565865982 0;
BA_ "GenMsgCycleTime" BO_ 2565867262 500;
BA_ "GenMsgSendType" BO_ 2565867262 0;
BA_ "GenMsgCycleTime" BO_ 2566821118 500;
BA_ "GenMsgSendType" BO_ 2566821118 0;
BA_ "GenMsgCycleTime" BO_ 2566847742 1000;
BA_ "GenMsgSendType" BO_ 2566847742 0;
BA_ "GenMsgCycleTime" BO_ 2563768062 5000;
BA_ "GenMsgSendType" BO_ 2563768062 0;
BA_ "SPN" SG_ 2566774014 SlowVesselModeStatus 2617;
BA_ "SigType" SG_ 2566774014 SlowVesselModeStatus 4;
BA_ "SPN" SG_ 2566774014 TrollingModeStatus 2616;
BA_ "SigType" SG_ 2566774014 TrollingModeStatus 4;
BA_ "SPN" SG_ 2566774014 EngThrttlSynchrnztionModeStatus 2615;
BA_ "SigType" SG_ 2566774014 EngThrttlSynchrnztionModeStatus 4;
BA_ "SPN" SG_ 2566823166 EngMainBearing11Temp 1167;
BA_ "SigType" SG_ 2566823166 EngMainBearing11Temp 1;
BA_ "SPN" SG_ 2566823166 EngMainBearing10Temp 1166;
BA_ "SigType" SG_ 2566823166 EngMainBearing10Temp 1;
BA_ "SPN" SG_ 2566823166 EngMainBearing9Temp 1165;
BA_ "SigType" SG_ 2566823166 EngMainBearing9Temp 1;
BA_ "SPN" SG_ 2566823422 EngMainBearing8Temp 1164;
BA_ "SigType" SG_ 2566823422 EngMainBearing8Temp 1;
BA_ "SPN" SG_ 2566823422 EngMainBearing7Temp 1163;
BA_ "SigType" SG_ 2566823422 EngMainBearing7Temp 1;
BA_ "SPN" SG_ 2566823422 EngMainBearing6Temp 1162;
BA_ "SigType" SG_ 2566823422 EngMainBearing6Temp 1;
BA_ "SPN" SG_ 2566823422 EngMainBearing5Temp 1161;
BA_ "SigType" SG_ 2566823422 EngMainBearing5Temp 1;
BA_ "SPN" SG_ 2566823678 EngMainBearing4Temp 1160;
BA_ "SigType" SG_ 2566823678 EngMainBearing4Temp 1;
BA_ "SPN" SG_ 2566823678 EngMainBearing3Temp 1159;
BA_ "SigType" SG_ 2566823678 EngMainBearing3Temp 1;
BA_ "SPN" SG_ 2566823678 EngMainBearing2Temp 1158;
BA_ "SigType" SG_ 2566823678 EngMainBearing2Temp 1;
BA_ "SPN" SG_ 2566823678 EngMainBearing1Temp 1157;
BA_ "SigType" SG_ 2566823678 EngMainBearing1Temp 1;
BA_ "SPN" SG_ 2432595710 DisplayDeadbands 2577;
BA_ "SigType" SG_ 2432595710 DisplayDeadbands 4;
BA_ "SPN" SG_ 2432595710 LEDPatternCtrl 2578;
BA_ "SigType" SG_ 2432595710 LEDPatternCtrl 4;
BA_ "SPN" SG_ 2432595710 LEDDisplayDeadbandCtrl 1806;
BA_ "SigType" SG_ 2432595710 LEDDisplayDeadbandCtrl 4;
BA_ "SPN" SG_ 2432595710 LEDDisplayModeCtrl 1805;
BA_ "SigType" SG_ 2432595710 LEDDisplayModeCtrl 4;
BA_ "SPN" SG_ 2432595710 LEDDisplayData1 1573;
BA_ "SigType" SG_ 2432595710 LEDDisplayData1 1;
BA_ "SPN" SG_ 2365486590 LaserStrikeDataLatency 2793;
BA_ "SigType" SG_ 2365486590 LaserStrikeDataLatency 1;
BA_ "SPN" SG_ 2365486590 LaserReceiverType 2576;
BA_ "SigType" SG_ 2365486590 LaserReceiverType 1;
BA_ "SPN" SG_ 2365486590 LaserStrikeVerticalDeviation 1574;
BA_ "SigType" SG_ 2365486590 LaserStrikeVerticalDeviation 1;
BA_ "SPN" SG_ 2365486590 AbsLaserStrikePos 2794;
BA_ "SigType" SG_ 2365486590 AbsLaserStrikePos 1;
BA_ "SPN" SG_ 2365485566 LaserTracerInformation 1583;
BA_ "SigType" SG_ 2365485566 LaserTracerInformation 1;
BA_ "SPN" SG_ 2365485566 LEDDisplayData2 1582;
BA_ "SigType" SG_ 2365485566 LEDDisplayData2 1;
BA_ "SPN" SG_ 2365485566 LaserTracerHorizontalDeviation 1581;
BA_ "SigType" SG_ 2365485566 LaserTracerHorizontalDeviation 1;
BA_ "SPN" SG_ 2365485566 LaserTracerVerticalDistance 1580;
BA_ "SigType" SG_ 2365485566 LaserTracerVerticalDistance 1;
BA_ "SPN" SG_ 2365485566 LaserTracerTargetDeviation 1579;
BA_ "SigType" SG_ 2365485566 LaserTracerTargetDeviation 1;
BA_ "SPN" SG_ 2365486334 BldHeightSetPointHighResolution 1759;
BA_ "SigType" SG_ 2365486334 BldHeightSetPointHighResolution 1;
BA_ "SPN" SG_ 2365486334 ModifyLevelingSystemSetPoint 1575;
BA_ "SigType" SG_ 2365486334 ModifyLevelingSystemSetPoint 1;
BA_ "SPN" SG_ 2364542462 SdshftDsrdBldOffsetOperatorCtrl 3339;
BA_ "SigType" SG_ 2364542462 SdshftDsrdBldOffsetOperatorCtrl 4;
BA_ "SPN" SG_ 2364542462 SdshftBldCtrlMdeOperatorControl 3338;
BA_ "SigType" SG_ 2364542462 SdshftBldCtrlMdeOperatorControl 4;
BA_ "SPN" SG_ 2364542462 RghtDsrdBladeOffsetOperatorCtrl 3337;
BA_ "SigType" SG_ 2364542462 RghtDsrdBladeOffsetOperatorCtrl 4;
BA_ "SPN" SG_ 2364542462 RghtBldeCtrlModeOperatorControl 3335;
BA_ "SigType" SG_ 2364542462 RghtBldeCtrlModeOperatorControl 4;
BA_ "SPN" SG_ 2364542462 LftDsredBladeOffsetOperatorCtrl 3336;
BA_ "SigType" SG_ 2364542462 LftDsredBladeOffsetOperatorCtrl 4;
BA_ "SPN" SG_ 2364542462 LftBladeCtrlModeOperatorControl 3334;
BA_ "SigType" SG_ 2364542462 LftBladeCtrlModeOperatorControl 4;
BA_ "SPN" SG_ 2364542462 BladeAutoModeCmd 3158;
BA_ "SigType" SG_ 2364542462 BladeAutoModeCmd 4;
BA_ "SPN" SG_ 2364542462 DesiredGradeOffsetSwitch 3157;
BA_ "SigType" SG_ 2364542462 DesiredGradeOffsetSwitch 4;
BA_ "SPN" SG_ 2364542462 BladeCtrlModeSwitch 3156;
BA_ "SigType" SG_ 2364542462 BladeCtrlModeSwitch 4;
BA_ "SPN" SG_ 2364542462 StElvtnSnsor2ReferenceElevation 5406;
BA_ "SigType" SG_ 2364542462 StElvtnSnsor2ReferenceElevation 4;
BA_ "SPN" SG_ 2364542462 StElvtnSnsor1ReferenceElevation 5405;
BA_ "SigType" SG_ 2364542462 StElvtnSnsor1ReferenceElevation 4;
BA_ "SPN" SG_ 2365486078 MastPos 1576;
BA_ "SigType" SG_ 2365486078 MastPos 1;
BA_ "SPN" SG_ 2633937918 TotalEngPTOGovernorFuelUsed 1028;
BA_ "SigType" SG_ 2633937918 TotalEngPTOGovernorFuelUsed 1;
BA_ "SPN" SG_ 2633937918 TripAverageFuelRate 1029;
BA_ "SigType" SG_ 2633937918 TripAverageFuelRate 1;
BA_ "SPN" SG_ 2633937918 FlexibleFuelPercentage 5458;
BA_ "SigType" SG_ 2633937918 FlexibleFuelPercentage 1;
BA_ "SPN" SG_ 2566845182 EngAverageFuelEconomy 185;
BA_ "SigType" SG_ 2566845182 EngAverageFuelEconomy 1;
BA_ "SPN" SG_ 2566845182 EngInstantaneousFuelEconomy 184;
BA_ "SigType" SG_ 2566845182 EngInstantaneousFuelEconomy 1;
BA_ "SPN" SG_ 2566845182 EngFuelRate 183;
BA_ "SigType" SG_ 2566845182 EngFuelRate 1;
BA_ "SPN" SG_ 2566845182 EngThrottleValve2Pos 3673;
BA_ "SigType" SG_ 2566845182 EngThrottleValve2Pos 1;
BA_ "SPN" SG_ 2566845182 EngThrottleValve1Pos 51;
BA_ "SigType" SG_ 2566845182 EngThrottleValve1Pos 1;
BA_ "SPN" SG_ 2566842878 EngTotalFuelUsed 250;
BA_ "SigType" SG_ 2566842878 EngTotalFuelUsed 1;
BA_ "SPN" SG_ 2566842878 EngTripFuel 182;
BA_ "SigType" SG_ 2566842878 EngTripFuel 1;
BA_ "SPN" SG_ 2633883646 FrontWheelDriveActuatorStatus 2612;
BA_ "SigType" SG_ 2633883646 FrontWheelDriveActuatorStatus 4;
BA_ "SPN" SG_ 2633880062 FMSstandardSWversionSupported 2806;
BA_ "SigType" SG_ 2633880062 FMSstandardSWversionSupported 1;
BA_ "SPN" SG_ 2633880062 FMSstandardRqsSupported 2805;
BA_ "SigType" SG_ 2633880062 FMSstandardRqsSupported 4;
BA_ "SPN" SG_ 2633880062 FMSstandardDiagnosticsSupported 2804;
BA_ "SigType" SG_ 2633880062 FMSstandardDiagnosticsSupported 4;
BA_ "SPN" SG_ 2566806526 LnDprtureIndicationEnableStatus 1702;
BA_ "SigType" SG_ 2566806526 LnDprtureIndicationEnableStatus 4;
BA_ "SPN" SG_ 2566806526 LaneTrackingStatusLeftSide 1710;
BA_ "SigType" SG_ 2566806526 LaneTrackingStatusLeftSide 4;
BA_ "SPN" SG_ 2566806526 LaneTrackingStatusRightSide 1711;
BA_ "SigType" SG_ 2566806526 LaneTrackingStatusRightSide 4;
BA_ "SPN" SG_ 2431649790 LaneDepartureImminentLeftSide 1700;
BA_ "SigType" SG_ 2431649790 LaneDepartureImminentLeftSide 4;
BA_ "SPN" SG_ 2431649790 LaneDepartureImminentRightSide 1701;
BA_ "SigType" SG_ 2431649790 LaneDepartureImminentRightSide 4;
BA_ "SPN" SG_ 2431649790 LaneDepartureRight 3566;
BA_ "SigType" SG_ 2431649790 LaneDepartureRight 4;
BA_ "SPN" SG_ 2431649790 LaneDepartureLeft 3565;
BA_ "SigType" SG_ 2431649790 LaneDepartureLeft 4;
BA_ "SPN" SG_ 2633929214 EngFuelLeakage2 1240;
BA_ "SigType" SG_ 2633929214 EngFuelLeakage2 4;
BA_ "SPN" SG_ 2633929214 EngFuelLeakage1 1239;
BA_ "SigType" SG_ 2633929214 EngFuelLeakage1 4;
BA_ "SPN" SG_ 2566831614 FanSpeed 1639;
BA_ "SigType" SG_ 2566831614 FanSpeed 1;
BA_ "SPN" SG_ 2566831614 FanDriveState 977;
BA_ "SigType" SG_ 2566831614 FanDriveState 4;
BA_ "SPN" SG_ 2566831614 EstPercentFanSpeed 975;
BA_ "SigType" SG_ 2566831614 EstPercentFanSpeed 1;
BA_ "SPN" SG_ 2566831614 HydFanMotorPress 4211;
BA_ "SigType" SG_ 2566831614 HydFanMotorPress 1;
BA_ "SPN" SG_ 2566831614 FanDriveBypassCmdStatus 4212;
BA_ "SigType" SG_ 2566831614 FanDriveBypassCmdStatus 1;
BA_ "SPN" SG_ 2364542206 TransClutch_ConverterInputSpeed 5052;
BA_ "SigType" SG_ 2364542206 TransClutch_ConverterInputSpeed 1;
BA_ "SPN" SG_ 2364542206 TransTorqueConverterRatio 3030;
BA_ "SigType" SG_ 2364542206 TransTorqueConverterRatio 1;
BA_ "SPN" SG_ 2566802174 TrnsRvrseGearShiftInhibitStatus 4261;
BA_ "SigType" SG_ 2566802174 TrnsRvrseGearShiftInhibitStatus 4;
BA_ "SPN" SG_ 2566802174 TrnsCrrntRangeDisplayBlankState 4176;
BA_ "SigType" SG_ 2566802174 TrnsCrrntRangeDisplayBlankState 4;
BA_ "SPN" SG_ 2566802174 TransWarningIndicator 5344;
BA_ "SigType" SG_ 2566802174 TransWarningIndicator 4;
BA_ "SPN" SG_ 2566802174 TransMode8Indicator 4253;
BA_ "SigType" SG_ 2566802174 TransMode8Indicator 4;
BA_ "SPN" SG_ 2566802174 TransMode7Indicator 4252;
BA_ "SigType" SG_ 2566802174 TransMode7Indicator 4;
BA_ "SPN" SG_ 2566802174 TransMode6Indicator 4251;
BA_ "SigType" SG_ 2566802174 TransMode6Indicator 4;
BA_ "SPN" SG_ 2566802174 TransMode5Indicator 4250;
BA_ "SigType" SG_ 2566802174 TransMode5Indicator 4;
BA_ "SPN" SG_ 2566802174 TransRqedGearFeedback 3289;
BA_ "SigType" SG_ 2566802174 TransRqedGearFeedback 1;
BA_ "SPN" SG_ 2566802174 TransMode1Indicator 2536;
BA_ "SigType" SG_ 2566802174 TransMode1Indicator 4;
BA_ "SPN" SG_ 2566802174 TransMode2Indicator 2537;
BA_ "SigType" SG_ 2566802174 TransMode2Indicator 4;
BA_ "SPN" SG_ 2566802174 TransMode3Indicator 2538;
BA_ "SigType" SG_ 2566802174 TransMode3Indicator 4;
BA_ "SPN" SG_ 2566802174 TransMode4Indicator 2539;
BA_ "SigType" SG_ 2566802174 TransMode4Indicator 4;
BA_ "SPN" SG_ 2566802174 TransShiftInhibitIndicator 1851;
BA_ "SigType" SG_ 2566802174 TransShiftInhibitIndicator 4;
BA_ "SPN" SG_ 2566802174 TransEngCrankEnable 2900;
BA_ "SigType" SG_ 2566802174 TransEngCrankEnable 4;
BA_ "SPN" SG_ 2566802174 ActiveShiftConsoleIndicator 2945;
BA_ "SigType" SG_ 2566802174 ActiveShiftConsoleIndicator 4;
BA_ "SPN" SG_ 2566802174 TransReadyForBrakeRelease 3086;
BA_ "SigType" SG_ 2566802174 TransReadyForBrakeRelease 4;
BA_ "SPN" SG_ 2566802174 TransRqedRangeDisplayFlashState 1849;
BA_ "SigType" SG_ 2566802174 TransRqedRangeDisplayFlashState 4;
BA_ "SPN" SG_ 2566802174 TransRqedRangeDisplayBlankState 1850;
BA_ "SigType" SG_ 2566802174 TransRqedRangeDisplayBlankState 4;
BA_ "SPN" SG_ 2566802174 TransServiceIndicator 4178;
BA_ "SigType" SG_ 2566802174 TransServiceIndicator 4;
BA_ "SPN" SG_ 2633935870 ClutchLifeRemaining 2983;
BA_ "SigType" SG_ 2633935870 ClutchLifeRemaining 1;
BA_ "SPN" SG_ 2633935870 LowestPossibleGear 1114;
BA_ "SigType" SG_ 2633935870 LowestPossibleGear 1;
BA_ "SPN" SG_ 2633935870 HighestPossibleGear 1115;
BA_ "SigType" SG_ 2633935870 HighestPossibleGear 1;
BA_ "SPN" SG_ 2633935870 RecommendedGear 1113;
BA_ "SigType" SG_ 2633935870 RecommendedGear 1;
BA_ "SPN" SG_ 2633942014 TransForwardDirectionSwitch 903;
BA_ "SigType" SG_ 2633942014 TransForwardDirectionSwitch 4;
BA_ "SPN" SG_ 2633942014 TransNeutralSwitch 604;
BA_ "SigType" SG_ 2633942014 TransNeutralSwitch 4;
BA_ "SPN" SG_ 2633942014 TransReverseDirectionSwitch 767;
BA_ "SigType" SG_ 2633942014 TransReverseDirectionSwitch 4;
BA_ "SPN" SG_ 2633942014 TransLowRangeSenseSwitch 779;
BA_ "SigType" SG_ 2633942014 TransLowRangeSenseSwitch 4;
BA_ "SPN" SG_ 2633942014 TransHighRangeSenseSwitch 778;
BA_ "SigType" SG_ 2633942014 TransHighRangeSenseSwitch 4;
BA_ "SPN" SG_ 2633942526 TransSynchronizerBrakeValue 54;
BA_ "SigType" SG_ 2633942526 TransSynchronizerBrakeValue 1;
BA_ "SPN" SG_ 2633942526 TransSynchronizerClutchValue 53;
BA_ "SigType" SG_ 2633942526 TransSynchronizerClutchValue 1;
BA_ "SPN" SG_ 2633943038 TransInertiaBrakeActuator 787;
BA_ "SigType" SG_ 2633943038 TransInertiaBrakeActuator 4;
BA_ "SPN" SG_ 2633943038 TransDefuelActuator 786;
BA_ "SigType" SG_ 2633943038 TransDefuelActuator 4;
BA_ "SPN" SG_ 2633943038 TransLockupClutchActuator 740;
BA_ "SigType" SG_ 2633943038 TransLockupClutchActuator 4;
BA_ "SPN" SG_ 2633943038 TransClutchActuator 788;
BA_ "SigType" SG_ 2633943038 TransClutchActuator 4;
BA_ "SPN" SG_ 2633943038 TransSplitterIndirectActuator 771;
BA_ "SigType" SG_ 2633943038 TransSplitterIndirectActuator 4;
BA_ "SPN" SG_ 2633943038 TransSplitterDirectActuator 770;
BA_ "SigType" SG_ 2633943038 TransSplitterDirectActuator 4;
BA_ "SPN" SG_ 2633943038 TransRangeLowActuator 769;
BA_ "SigType" SG_ 2633943038 TransRangeLowActuator 4;
BA_ "SPN" SG_ 2633943038 TransRangeHighActuator 768;
BA_ "SigType" SG_ 2633943038 TransRangeHighActuator 4;
BA_ "SPN" SG_ 2633943038 TransShiftFingerGearActuator2 784;
BA_ "SigType" SG_ 2633943038 TransShiftFingerGearActuator2 4;
BA_ "SPN" SG_ 2633943038 TransShiftFingerRailActuator2 783;
BA_ "SigType" SG_ 2633943038 TransShiftFingerRailActuator2 4;
BA_ "SPN" SG_ 2633943038 TransShiftFingerGearActuator1 773;
BA_ "SigType" SG_ 2633943038 TransShiftFingerGearActuator1 4;
BA_ "SPN" SG_ 2633943038 TransShiftFingerRailActuator1 772;
BA_ "SigType" SG_ 2633943038 TransShiftFingerRailActuator1 4;
BA_ "SPN" SG_ 2633943038 TrnsShftFngrCenterRailIndicator 782;
BA_ "SigType" SG_ 2633943038 TrnsShftFngrCenterRailIndicator 4;
BA_ "SPN" SG_ 2633943038 TrnsShftFngrEngagementIndicator 781;
BA_ "SigType" SG_ 2633943038 TrnsShftFngrEngagementIndicator 4;
BA_ "SPN" SG_ 2633943038 TrnsShiftFingerNeutralIndicator 780;
BA_ "SigType" SG_ 2633943038 TrnsShiftFingerNeutralIndicator 4;
BA_ "SPN" SG_ 2633943038 TransShiftFingerRailPos 60;
BA_ "SigType" SG_ 2633943038 TransShiftFingerRailPos 1;
BA_ "SPN" SG_ 2633943038 TransShiftFingerGearPos 59;
BA_ "SigType" SG_ 2633943038 TransShiftFingerGearPos 1;
BA_ "SPN" SG_ 2565867006 TransCurrentRange 163;
BA_ "SigType" SG_ 2565867006 TransCurrentRange 1;
BA_ "SPN" SG_ 2565867006 TransRqedRange 162;
BA_ "SigType" SG_ 2565867006 TransRqedRange 1;
BA_ "SPN" SG_ 2565867006 TransCurrentGear 523;
BA_ "SigType" SG_ 2565867006 TransCurrentGear 1;
BA_ "SPN" SG_ 2565867006 TransActualGearRatio 526;
BA_ "SigType" SG_ 2565867006 TransActualGearRatio 1;
BA_ "SPN" SG_ 2565867006 TransSelectedGear 524;
BA_ "SigType" SG_ 2565867006 TransSelectedGear 1;
BA_ "SPN" SG_ 2364539646 TrnsTrqueConverterLockupEngaged 573;
BA_ "SigType" SG_ 2364539646 TrnsTrqueConverterLockupEngaged 4;
BA_ "SPN" SG_ 2364539646 TrnsTrqCnvrtrLckpTrnstnInPrcess 4816;
BA_ "SigType" SG_ 2364539646 TrnsTrqCnvrtrLckpTrnstnInPrcess 4;
BA_ "SPN" SG_ 2364539646 SrcAddrssOfCtrllngDvcFrTrnsCntrl 1482;
BA_ "SigType" SG_ 2364539646 SrcAddrssOfCtrllngDvcFrTrnsCntrl 1;
BA_ "SPN" SG_ 2364539646 MomentaryEngMaxPowerEnable 5015;
BA_ "SigType" SG_ 2364539646 MomentaryEngMaxPowerEnable 4;
BA_ "SPN" SG_ 2364539646 TransInputShaftSpeed 161;
BA_ "SigType" SG_ 2364539646 TransInputShaftSpeed 1;
BA_ "SPN" SG_ 2364539646 ProgressiveShiftDisable 607;
BA_ "SigType" SG_ 2364539646 ProgressiveShiftDisable 4;
BA_ "SPN" SG_ 2364539646 EngMomentaryOverspeedEnable 606;
BA_ "SigType" SG_ 2364539646 EngMomentaryOverspeedEnable 4;
BA_ "SPN" SG_ 2364539646 PercentClutchSlip 522;
BA_ "SigType" SG_ 2364539646 PercentClutchSlip 1;
BA_ "SPN" SG_ 2364539646 TransOutputShaftSpeed 191;
BA_ "SigType" SG_ 2364539646 TransOutputShaftSpeed 1;
BA_ "SPN" SG_ 2364539646 TransShiftInProcess 574;
BA_ "SigType" SG_ 2364539646 TransShiftInProcess 4;
BA_ "SPN" SG_ 2364539646 TransDrivelineEngaged 560;
BA_ "SigType" SG_ 2364539646 TransDrivelineEngaged 4;
BA_ "SPN" SG_ 2566810110 EngChargeAirCooler1OutletTemp 2630;
BA_ "SigType" SG_ 2566810110 EngChargeAirCooler1OutletTemp 1;
BA_ "SPN" SG_ 2566810110 EngIntkVlvActationSystemOilTemp 2986;
BA_ "SigType" SG_ 2566810110 EngIntkVlvActationSystemOilTemp 1;
BA_ "SPN" SG_ 2566810110 EngIntakeManifold1AirTemp 1636;
BA_ "SigType" SG_ 2566810110 EngIntakeManifold1AirTemp 1;
BA_ "SPN" SG_ 2566810110 EngCoolantTempHiRes 1637;
BA_ "SigType" SG_ 2566810110 EngCoolantTempHiRes 1;
BA_ "SPN" SG_ 2566825214 EngExhstGsRcrculation1DiffPress 411;
BA_ "SigType" SG_ 2566825214 EngExhstGsRcrculation1DiffPress 1;
BA_ "SPN" SG_ 2566825214 EngExhaustGasRecirculation1Temp 412;
BA_ "SigType" SG_ 2566825214 EngExhaustGasRecirculation1Temp 1;
BA_ "SPN" SG_ 2566825214 EngECUTemp 1136;
BA_ "SigType" SG_ 2566825214 EngECUTemp 1;
BA_ "SPN" SG_ 2566825214 EngOilTemp2 1135;
BA_ "SigType" SG_ 2566825214 EngOilTemp2 1;
BA_ "SPN" SG_ 2566844158 EngFuelTemp1 174;
BA_ "SigType" SG_ 2566844158 EngFuelTemp1 1;
BA_ "SPN" SG_ 2566844158 EngIntercoolerThermostatOpening 1134;
BA_ "SigType" SG_ 2566844158 EngIntercoolerThermostatOpening 1;
BA_ "SPN" SG_ 2566844158 EngIntercoolerTemp 52;
BA_ "SigType" SG_ 2566844158 EngIntercoolerTemp 1;
BA_ "SPN" SG_ 2566844158 EngTurboOilTemp 176;
BA_ "SigType" SG_ 2566844158 EngTurboOilTemp 1;
BA_ "SPN" SG_ 2566844158 EngOilTemp1 175;
BA_ "SigType" SG_ 2566844158 EngOilTemp1 1;
BA_ "SPN" SG_ 2566844158 EngCoolantTemp 1637;
BA_ "SigType" SG_ 2566844158 EngCoolantTemp 1;
BA_ "SPN" SG_ 2566785022 EngExhaustGasTempRightManifold 2433;
BA_ "SigType" SG_ 2566785022 EngExhaustGasTempRightManifold 1;
BA_ "SPN" SG_ 2566785022 EngExhaustGasTempLeftManifold 2434;
BA_ "SigType" SG_ 2566785022 EngExhaustGasTempLeftManifold 1;
BA_ "SPN" SG_ 2565868542 SterableLiftAxleLoweringInhibit 2922;
BA_ "SigType" SG_ 2565868542 SterableLiftAxleLoweringInhibit 4;
BA_ "SPN" SG_ 2565868542 AxleLocation 2928;
BA_ "SigType" SG_ 2565868542 AxleLocation 1;
BA_ "SPN" SG_ 2565868542 TypeOfSteerTrans 2926;
BA_ "SigType" SG_ 2565868542 TypeOfSteerTrans 4;
BA_ "SPN" SG_ 2565868542 TypeOfSteerForces 2925;
BA_ "SigType" SG_ 2565868542 TypeOfSteerForces 4;
BA_ "SPN" SG_ 2565868542 SteerType 2924;
BA_ "SigType" SG_ 2565868542 SteerType 4;
BA_ "SPN" SG_ 2565868542 StatusOfSteerAxle 2923;
BA_ "SigType" SG_ 2565868542 StatusOfSteerAxle 4;
BA_ "SPN" SG_ 2565868542 ActualInnerWheelSteerAngle 2927;
BA_ "SigType" SG_ 2565868542 ActualInnerWheelSteerAngle 1;
BA_ "SPN" SG_ 2633941758 TransOutputRetarder 748;
BA_ "SigType" SG_ 2633941758 TransOutputRetarder 4;
BA_ "SPN" SG_ 2565865726 RetarderSelectionNonEng 1716;
BA_ "SigType" SG_ 2565865726 RetarderSelectionNonEng 1;
BA_ "SPN" SG_ 2565865726 SrcAddrssOfCtrllngDvcFrRtrdrCntr 1480;
BA_ "SigType" SG_ 2565865726 SrcAddrssOfCtrllngDvcFrRtrdrCntr 1;
BA_ "SystemSignalLongSymbol" SG_ 2565865726 SrcAddrssOfCtrllngDvcFrRtrdrCntr "SrcAddrssOfCtrllngDvcFrRtrdrCntrl";
BA_ "SPN" SG_ 2565865726 RetarderRoadSpeedLimitSwitch 4233;
BA_ "SigType" SG_ 2565865726 RetarderRoadSpeedLimitSwitch 4;
BA_ "SPN" SG_ 2565865726 RetarderRoadSpeedExceededStatus 4234;
BA_ "SigType" SG_ 2565865726 RetarderRoadSpeedExceededStatus 4;
BA_ "SPN" SG_ 2565865726 ActlMxAvlblRtarderPercentTorque 1717;
BA_ "SigType" SG_ 2565865726 ActlMxAvlblRtarderPercentTorque 1;
BA_ "SPN" SG_ 2565865726 DrvrsDmandRetarderPercentTorque 1715;
BA_ "SigType" SG_ 2565865726 DrvrsDmandRetarderPercentTorque 1;
BA_ "SPN" SG_ 2565865726 RetarderRqingBrakeLight 1667;
BA_ "SigType" SG_ 2565865726 RetarderRqingBrakeLight 4;
BA_ "SPN" SG_ 2565865726 EngCoolantLoadIncrease 1082;
BA_ "SigType" SG_ 2565865726 EngCoolantLoadIncrease 4;
BA_ "SPN" SG_ 2565865726 IntendedRetarderPercentTorque 1085;
BA_ "SigType" SG_ 2565865726 IntendedRetarderPercentTorque 1;
BA_ "SPN" SG_ 2565865726 ActualRetarderPercentTorque 520;
BA_ "SigType" SG_ 2565865726 ActualRetarderPercentTorque 1;
BA_ "SPN" SG_ 2565865726 RetarderEnableShiftAssistSwitch 572;
BA_ "SigType" SG_ 2565865726 RetarderEnableShiftAssistSwitch 4;
BA_ "SPN" SG_ 2565865726 RetarderEnableBrakeAssistSwitch 571;
BA_ "SigType" SG_ 2565865726 RetarderEnableBrakeAssistSwitch 4;
BA_ "SPN" SG_ 2565865726 RetarderTorqueMode 900;
BA_ "SigType" SG_ 2565865726 RetarderTorqueMode 4;
BA_ "SPN" SG_ 2633932798 EngExhaustGasPort20Temp 1156;
BA_ "SigType" SG_ 2633932798 EngExhaustGasPort20Temp 1;
BA_ "SPN" SG_ 2633932798 EngExhaustGasPort19Temp 1155;
BA_ "SigType" SG_ 2633932798 EngExhaustGasPort19Temp 1;
BA_ "SPN" SG_ 2633932798 EngExhaustGasPort18Temp 1154;
BA_ "SigType" SG_ 2633932798 EngExhaustGasPort18Temp 1;
BA_ "SPN" SG_ 2633932798 EngExhaustGasPort17Temp 1153;
BA_ "SigType" SG_ 2633932798 EngExhaustGasPort17Temp 1;
BA_ "SPN" SG_ 2566824190 EngExhaustGasPort16Temp 1152;
BA_ "SigType" SG_ 2566824190 EngExhaustGasPort16Temp 1;
BA_ "SPN" SG_ 2566824190 EngExhaustGasPort15Temp 1151;
BA_ "SigType" SG_ 2566824190 EngExhaustGasPort15Temp 1;
BA_ "SPN" SG_ 2566824190 EngExhaustGasPort14Temp 1150;
BA_ "SigType" SG_ 2566824190 EngExhaustGasPort14Temp 1;
BA_ "SPN" SG_ 2566824190 EngExhaustGasPort13Temp 1149;
BA_ "SigType" SG_ 2566824190 EngExhaustGasPort13Temp 1;
BA_ "SPN" SG_ 2633933310 EngExhaustGasPort12Temp 1148;
BA_ "SigType" SG_ 2633933310 EngExhaustGasPort12Temp 1;
BA_ "SPN" SG_ 2633933310 EngExhaustGasPort11Temp 1147;
BA_ "SigType" SG_ 2633933310 EngExhaustGasPort11Temp 1;
BA_ "SPN" SG_ 2633933310 EngExhaustGasPort10Temp 1146;
BA_ "SigType" SG_ 2633933310 EngExhaustGasPort10Temp 1;
BA_ "SPN" SG_ 2633933310 EngExhaustGasPort9Temp 1145;
BA_ "SigType" SG_ 2633933310 EngExhaustGasPort9Temp 1;
BA_ "SPN" SG_ 2633933566 EngExhaustGasPort8Temp 1144;
BA_ "SigType" SG_ 2633933566 EngExhaustGasPort8Temp 1;
BA_ "SPN" SG_ 2633933566 EngExhaustGasPort7Temp 1143;
BA_ "SigType" SG_ 2633933566 EngExhaustGasPort7Temp 1;
BA_ "SPN" SG_ 2633933566 EngExhaustGasPort6Temp 1142;
BA_ "SigType" SG_ 2633933566 EngExhaustGasPort6Temp 1;
BA_ "SPN" SG_ 2633933566 EngExhaustGasPort5Temp 1141;
BA_ "SigType" SG_ 2633933566 EngExhaustGasPort5Temp 1;
BA_ "SPN" SG_ 2633933822 EngExhaustGasPort4Temp 1140;
BA_ "SigType" SG_ 2633933822 EngExhaustGasPort4Temp 1;
BA_ "SPN" SG_ 2633933822 EngExhaustGasPort3Temp 1139;
BA_ "SigType" SG_ 2633933822 EngExhaustGasPort3Temp 1;
BA_ "SPN" SG_ 2633933822 EngExhaustGasPort2Temp 1138;
BA_ "SigType" SG_ 2633933822 EngExhaustGasPort2Temp 1;
BA_ "SPN" SG_ 2633933822 EngExhaustGasPort1Temp 1137;
BA_ "SigType" SG_ 2633933822 EngExhaustGasPort1Temp 1;
BA_ "SPN" SG_ 2566776062 PayloadPercentage 2600;
BA_ "SigType" SG_ 2566776062 PayloadPercentage 1;
BA_ "SPN" SG_ 2566771454 DataMemoryUsage 2802;
BA_ "SigType" SG_ 2566771454 DataMemoryUsage 1;
BA_ "SPN" SG_ 2566771454 KeepAliveBatteryConsumption 2803;
BA_ "SigType" SG_ 2566771454 KeepAliveBatteryConsumption 4;
BA_ "SPN" SG_ 2566775806 TravelVelocityCtrlPos 2601;
BA_ "SigType" SG_ 2566775806 TravelVelocityCtrlPos 1;
BA_ "SPN" SG_ 2633935358 EngExhstGsOxygnSnsrClsdLpOprton 1696;
BA_ "SigType" SG_ 2633935358 EngExhstGsOxygnSnsrClsdLpOprton 4;
BA_ "SPN" SG_ 2633935358 EngExhstGsOxygnSnsrFlngCrrction 1695;
BA_ "SigType" SG_ 2633935358 EngExhstGsOxygnSnsrFlngCrrction 1;
BA_ "SPN" SG_ 2633935358 EngActualExhaustOxygen 1119;
BA_ "SigType" SG_ 2633935358 EngActualExhaustOxygen 1;
BA_ "SPN" SG_ 2633935358 EngDesiredExhaustOxygen 1118;
BA_ "SigType" SG_ 2633935358 EngDesiredExhaustOxygen 1;
BA_ "SPN" SG_ 2633935358 EngDesiredRatedExhaustOxygen 1117;
BA_ "SigType" SG_ 2633935358 EngDesiredRatedExhaustOxygen 1;
BA_ "SPN" SG_ 2365447166 Jystck3GripXAxisDetentPosStatus 2756;
BA_ "SigType" SG_ 2365447166 Jystck3GripXAxisDetentPosStatus 4;
BA_ "SPN" SG_ 2365447166 Jystck3GripYAxisDetentPosStatus 2757;
BA_ "SigType" SG_ 2365447166 Jystck3GripYAxisDetentPosStatus 4;
BA_ "SPN" SG_ 2365447166 Jystck3ThetaAxisDetentPosStatus 2758;
BA_ "SigType" SG_ 2365447166 Jystck3ThetaAxisDetentPosStatus 4;
BA_ "SPN" SG_ 2365447166 Joystick3ThetaAxisPos 2738;
BA_ "SigType" SG_ 2365447166 Joystick3ThetaAxisPos 1;
BA_ "SPN" SG_ 2365447166 Jystck3ThtAxsClckwsPstvPsStatus 2743;
BA_ "SigType" SG_ 2365447166 Jystck3ThtAxsClckwsPstvPsStatus 4;
BA_ "SPN" SG_ 2365447166 Jystck3ThtaAxisNeutralPosStatus 2753;
BA_ "SigType" SG_ 2365447166 Jystck3ThtaAxisNeutralPosStatus 4;
BA_ "SPN" SG_ 2365447166 Joystick3GripYAxisPos 2737;
BA_ "SigType" SG_ 2365447166 Joystick3GripYAxisPos 1;
BA_ "SPN" SG_ 2365447166 Jystck3GrpYAxsLvrFrwrdPstvPsStts 2742;
BA_ "SigType" SG_ 2365447166 Jystck3GrpYAxsLvrFrwrdPstvPsStts 4;
BA_ "SPN" SG_ 2365447166 Jystck3GrpYAxsLvrBckNgtvPsSttus 2747;
BA_ "SigType" SG_ 2365447166 Jystck3GrpYAxsLvrBckNgtvPsSttus 4;
BA_ "SPN" SG_ 2365447166 Jystck3GrpYAxisNeutralPosStatus 2752;
BA_ "SigType" SG_ 2365447166 Jystck3GrpYAxisNeutralPosStatus 4;
BA_ "SPN" SG_ 2365447166 Joystick3GripXAxisPos 2736;
BA_ "SigType" SG_ 2365447166 Joystick3GripXAxisPos 1;
BA_ "SPN" SG_ 2365447166 Jystck3GrpXAxsLvrRghtPstvPsStts 2741;
BA_ "SigType" SG_ 2365447166 Jystck3GrpXAxsLvrRghtPstvPsStts 4;
BA_ "SPN" SG_ 2365447166 Jystck3GrpXAxsLvrLftNgtvPsSttus 2746;
BA_ "SigType" SG_ 2365447166 Jystck3GrpXAxsLvrLftNgtvPsSttus 4;
BA_ "SPN" SG_ 2365447166 Jystck3GrpXAxisNeutralPosStatus 2751;
BA_ "SigType" SG_ 2365447166 Jystck3GrpXAxisNeutralPosStatus 4;
BA_ "SPN" SG_ 2365447166 Jystck3ThtAxsCntrClckwsNgtvPsStt 2748;
BA_ "SigType" SG_ 2365447166 Jystck3ThtAxsCntrClckwsNgtvPsStt 4;
BA_ "SystemSignalLongSymbol" SG_ 2365447166 Jystck3ThtAxsCntrClckwsNgtvPsStt "Jystck3ThtAxsCntrClckwsNgtvPsStts";
BA_ "SPN" SG_ 2365446654 Jystck2GripXAxisDetentPosStatus 2719;
BA_ "SigType" SG_ 2365446654 Jystck2GripXAxisDetentPosStatus 4;
BA_ "SPN" SG_ 2365446654 Jystck2GripYAxisDetentPosStatus 2720;
BA_ "SigType" SG_ 2365446654 Jystck2GripYAxisDetentPosStatus 4;
BA_ "SPN" SG_ 2365446654 Jystck2ThetaAxisDetentPosStatus 2721;
BA_ "SigType" SG_ 2365446654 Jystck2ThetaAxisDetentPosStatus 4;
BA_ "SPN" SG_ 2365446654 Joystick2ThetaAxisPos 2701;
BA_ "SigType" SG_ 2365446654 Joystick2ThetaAxisPos 1;
BA_ "SPN" SG_ 2365446654 Jystck2ThtAxsClckwsPstvPsStatus 2706;
BA_ "SigType" SG_ 2365446654 Jystck2ThtAxsClckwsPstvPsStatus 4;
BA_ "SPN" SG_ 2365446654 Jystck2ThtaAxisNeutralPosStatus 2716;
BA_ "SigType" SG_ 2365446654 Jystck2ThtaAxisNeutralPosStatus 4;
BA_ "SPN" SG_ 2365446654 Joystick2GripYAxisPos 2700;
BA_ "SigType" SG_ 2365446654 Joystick2GripYAxisPos 1;
BA_ "SPN" SG_ 2365446654 Jystck2GrpYAxsLvrFrwrdPstvPsStts 2705;
BA_ "SigType" SG_ 2365446654 Jystck2GrpYAxsLvrFrwrdPstvPsStts 4;
BA_ "SPN" SG_ 2365446654 Jystck2GrpYAxsLvrBckNgtvPsSttus 2710;
BA_ "SigType" SG_ 2365446654 Jystck2GrpYAxsLvrBckNgtvPsSttus 4;
BA_ "SPN" SG_ 2365446654 Jystck2GrpYAxisNeutralPosStatus 2715;
BA_ "SigType" SG_ 2365446654 Jystck2GrpYAxisNeutralPosStatus 4;
BA_ "SPN" SG_ 2365446654 Joystick2GripXAxisPos 2699;
BA_ "SigType" SG_ 2365446654 Joystick2GripXAxisPos 1;
BA_ "SPN" SG_ 2365446654 Jystck2GrpXAxsLvrRghtPstvPsStts 2704;
BA_ "SigType" SG_ 2365446654 Jystck2GrpXAxsLvrRghtPstvPsStts 4;
BA_ "SPN" SG_ 2365446654 Jystck2GrpXAxsLvrLftNgtvPsSttus 2709;
BA_ "SigType" SG_ 2365446654 Jystck2GrpXAxsLvrLftNgtvPsSttus 4;
BA_ "SPN" SG_ 2365446654 Jystck2GrpXAxisNeutralPosStatus 2714;
BA_ "SigType" SG_ 2365446654 Jystck2GrpXAxisNeutralPosStatus 4;
BA_ "SPN" SG_ 2365446654 Jystck2ThtAxsCntrClckwsNgtvPsStt 2711;
BA_ "SigType" SG_ 2365446654 Jystck2ThtAxsCntrClckwsNgtvPsStt 4;
BA_ "SystemSignalLongSymbol" SG_ 2365446654 Jystck2ThtAxsCntrClckwsNgtvPsStt "Jystck2ThtAxsCntrClckwsNgtvPsStts";
BA_ "SPN" SG_ 2365446142 Jystck1GripXAxisDetentPosStatus 2682;
BA_ "SigType" SG_ 2365446142 Jystck1GripXAxisDetentPosStatus 4;
BA_ "SPN" SG_ 2365446142 Jystck1GripYAxisDetentPosStatus 2683;
BA_ "SigType" SG_ 2365446142 Jystck1GripYAxisDetentPosStatus 4;
BA_ "SPN" SG_ 2365446142 Jystck1ThetaAxisDetentPosStatus 2684;
BA_ "SigType" SG_ 2365446142 Jystck1ThetaAxisDetentPosStatus 4;
BA_ "SPN" SG_ 2365446142 Joystick1ThetaAxisPos 2664;
BA_ "SigType" SG_ 2365446142 Joystick1ThetaAxisPos 1;
BA_ "SPN" SG_ 2365446142 Jystck1ThtAxsClckwsPstvPsStatus 2669;
BA_ "SigType" SG_ 2365446142 Jystck1ThtAxsClckwsPstvPsStatus 4;
BA_ "SPN" SG_ 2365446142 Jystck1ThtaAxisNeutralPosStatus 2679;
BA_ "SigType" SG_ 2365446142 Jystck1ThtaAxisNeutralPosStatus 4;
BA_ "SPN" SG_ 2365446142 Joystick1GripYAxisPos 2663;
BA_ "SigType" SG_ 2365446142 Joystick1GripYAxisPos 1;
BA_ "SPN" SG_ 2365446142 Jystck1GrpYAxsLvrFrwrdPstvPsStts 2668;
BA_ "SigType" SG_ 2365446142 Jystck1GrpYAxsLvrFrwrdPstvPsStts 4;
BA_ "SPN" SG_ 2365446142 Jystck1GrpYAxsLvrBckNgtvPsSttus 2673;
BA_ "SigType" SG_ 2365446142 Jystck1GrpYAxsLvrBckNgtvPsSttus 4;
BA_ "SPN" SG_ 2365446142 Jystck1GrpYAxisNeutralPosStatus 2678;
BA_ "SigType" SG_ 2365446142 Jystck1GrpYAxisNeutralPosStatus 4;
BA_ "SPN" SG_ 2365446142 Joystick1GripXAxisPos 2662;
BA_ "SigType" SG_ 2365446142 Joystick1GripXAxisPos 1;
BA_ "SPN" SG_ 2365446142 Jystck1GrpXAxsLvrRghtPstvPsStts 2667;
BA_ "SigType" SG_ 2365446142 Jystck1GrpXAxsLvrRghtPstvPsStts 4;
BA_ "SPN" SG_ 2365446142 Jystck1GrpXAxsLvrLftNgtvPsSttus 2672;
BA_ "SigType" SG_ 2365446142 Jystck1GrpXAxsLvrLftNgtvPsSttus 4;
BA_ "SPN" SG_ 2365446142 Jystck1GrpXAxisNeutralPosStatus 2677;
BA_ "SigType" SG_ 2365446142 Jystck1GrpXAxisNeutralPosStatus 4;
BA_ "SPN" SG_ 2365446142 Jystck1ThtAxsCntrClckwsNgtvPsStt 2674;
BA_ "SigType" SG_ 2365446142 Jystck1ThtAxsCntrClckwsNgtvPsStt 4;
BA_ "SystemSignalLongSymbol" SG_ 2365446142 Jystck1ThtAxsCntrClckwsNgtvPsStt "Jystck1ThtAxsCntrClckwsNgtvPsStts";
BA_ "SPN" SG_ 2633929470 EngFuelRackPos 1210;
BA_ "SigType" SG_ 2633929470 EngFuelRackPos 1;
BA_ "SPN" SG_ 2633929470 EngGasMassFlowRate1 1241;
BA_ "SigType" SG_ 2633929470 EngGasMassFlowRate1 1;
BA_ "SPN" SG_ 2633929470 InstantaneousEstBrakePower 1242;
BA_ "SigType" SG_ 2633929470 InstantaneousEstBrakePower 1;
BA_ "SPN" SG_ 2633929470 EngExhaustGasPress 1209;
BA_ "SigType" SG_ 2633929470 EngExhaustGasPress 1;
BA_ "SPN" SG_ 2633929470 EngPrefilterOilPress 1208;
BA_ "SigType" SG_ 2633929470 EngPrefilterOilPress 1;
BA_ "SPN" SG_ 2633937406 TotalECURunTime 1033;
BA_ "SigType" SG_ 2633937406 TotalECURunTime 1;
BA_ "SPN" SG_ 2633937406 TotalECUDistance 1032;
BA_ "SigType" SG_ 2633937406 TotalECUDistance 1;
BA_ "SPN" SG_ 2364541694 EngIntakeAirMassFlowRate 132;
BA_ "SigType" SG_ 2364541694 EngIntakeAirMassFlowRate 1;
BA_ "SPN" SG_ 2364541694 EngExhstGsRcrclton2MassFlowRate 5257;
BA_ "SigType" SG_ 2364541694 EngExhstGsRcrclton2MassFlowRate 1;
BA_ "SPN" SG_ 2364541694 EngExhstGsRcrclton1MassFlowRate 2659;
BA_ "SigType" SG_ 2364541694 EngExhstGsRcrclton1MassFlowRate 1;
BA_ "SPN" SG_ 2566810366 FuelPumpPrimerStatus 4083;
BA_ "SigType" SG_ 2566810366 FuelPumpPrimerStatus 4;
BA_ "SPN" SG_ 2566810366 EngFuelSupplyPumpIntakePress 1381;
BA_ "SigType" SG_ 2566810366 EngFuelSupplyPumpIntakePress 1;
BA_ "SPN" SG_ 2566810366 EngFuelFilterDiffPress 1382;
BA_ "SigType" SG_ 2566810366 EngFuelFilterDiffPress 1;
BA_ "SPN" SG_ 2566810366 EngOilLevelRemoteReservoir 1380;
BA_ "SigType" SG_ 2566810366 EngOilLevelRemoteReservoir 1;
BA_ "SPN" SG_ 2566810366 EngWasteOilReservoirLevel 3548;
BA_ "SigType" SG_ 2566810366 EngWasteOilReservoirLevel 1;
BA_ "SPN" SG_ 2566810366 EngVentilationStatus 3554;
BA_ "SPN" SG_ 2566810366 EngOilPrimingState 3551;
BA_ "SigType" SG_ 2566810366 EngOilPrimingState 4;
BA_ "SPN" SG_ 2566810366 EngOilPrimingPumpSwitch 3550;
BA_ "SigType" SG_ 2566810366 EngOilPrimingPumpSwitch 4;
BA_ "SPN" SG_ 2566810366 EngOilPreHeatedState 3552;
BA_ "SigType" SG_ 2566810366 EngOilPreHeatedState 4;
BA_ "SPN" SG_ 2566810366 EngOilFilterOutletPress 3549;
BA_ "SigType" SG_ 2566810366 EngOilFilterOutletPress 1;
BA_ "SPN" SG_ 2566810366 EngCoolantPreheatedState 3553;
BA_ "SigType" SG_ 2566810366 EngCoolantPreheatedState 4;
BA_ "SPN" SG_ 2566767102 EngExhstVlvActtonSystemOilPress 4287;
BA_ "SigType" SG_ 2566767102 EngExhstVlvActtonSystemOilPress 1;
BA_ "SPN" SG_ 2566767102 EngExhstGsRcrcltion1OutletPress 5019;
BA_ "SigType" SG_ 2566767102 EngExhstGsRcrcltion1OutletPress 1;
BA_ "SPN" SG_ 2566767102 EngExhstGsRcrcltion1IntakePress 3358;
BA_ "SigType" SG_ 2566767102 EngExhstGsRcrcltion1IntakePress 1;
BA_ "SPN" SG_ 2566767102 EngIntkVlvActtionSystemOilPress 2948;
BA_ "SigType" SG_ 2566767102 EngIntkVlvActtionSystemOilPress 1;
BA_ "SPN" SG_ 2566839294 EngInjectorMeteringRail2Press 1349;
BA_ "SigType" SG_ 2566839294 EngInjectorMeteringRail2Press 1;
BA_ "SPN" SG_ 2566839294 EngInjectorTimingRail1Press 156;
BA_ "SigType" SG_ 2566839294 EngInjectorTimingRail1Press 1;
BA_ "SPN" SG_ 2566839294 EngInjectorMeteringRail1Press 157;
BA_ "SigType" SG_ 2566839294 EngInjectorMeteringRail1Press 1;
BA_ "SPN" SG_ 2566839294 EngInjectionCtrlPress 164;
BA_ "SigType" SG_ 2566839294 EngInjectionCtrlPress 1;
BA_ "SPN" SG_ 2566844414 EngCoolantLevel 111;
BA_ "SigType" SG_ 2566844414 EngCoolantLevel 1;
BA_ "SPN" SG_ 2566844414 EngCoolantPress 109;
BA_ "SigType" SG_ 2566844414 EngCoolantPress 1;
BA_ "SPN" SG_ 2566844414 EngCrankcasePress 101;
BA_ "SigType" SG_ 2566844414 EngCrankcasePress 1;
BA_ "SPN" SG_ 2566844414 EngOilPress 100;
BA_ "SigType" SG_ 2566844414 EngOilPress 1;
BA_ "SPN" SG_ 2566844414 EngOilLevel 98;
BA_ "SigType" SG_ 2566844414 EngOilLevel 1;
BA_ "SPN" SG_ 2566844414 EngExCrankcaseBlowbyPress 22;
BA_ "SigType" SG_ 2566844414 EngExCrankcaseBlowbyPress 1;
BA_ "SPN" SG_ 2566844414 EngFuelDeliveryPress 94;
BA_ "SigType" SG_ 2566844414 EngFuelDeliveryPress 1;
BA_ "SPN" SG_ 2633929726 TurningGearEngaged 1206;
BA_ "SigType" SG_ 2633929726 TurningGearEngaged 4;
BA_ "SPN" SG_ 2633929726 SafetyWireStatus 1205;
BA_ "SigType" SG_ 2633929726 SafetyWireStatus 4;
BA_ "SPN" SG_ 2633929726 ElectricalLoad 1204;
BA_ "SigType" SG_ 2633929726 ElectricalLoad 1;
BA_ "SPN" SG_ 2566772222 EngVrableGeometryTurbo1CtrlMode 5457;
BA_ "SigType" SG_ 2566772222 EngVrableGeometryTurbo1CtrlMode 4;
BA_ "SPN" SG_ 2566772222 EngTrb1ClcltedTurbineIntakeTemp 2789;
BA_ "SigType" SG_ 2566772222 EngTrb1ClcltedTurbineIntakeTemp 1;
BA_ "SPN" SG_ 2566772222 EngExhstGsRcrculation1ValveCtrl 2791;
BA_ "SigType" SG_ 2566772222 EngExhstGsRcrculation1ValveCtrl 1;
BA_ "SPN" SG_ 2566772222 EngVrblGometryTurbo1ActuatorPos 2795;
BA_ "SigType" SG_ 2566772222 EngVrblGometryTurbo1ActuatorPos 1;
BA_ "SPN" SG_ 2566772222 EngVrblGmtryTrbArCtrlShtffValve 2792;
BA_ "SigType" SG_ 2566772222 EngVrblGmtryTrbArCtrlShtffValve 4;
BA_ "SPN" SG_ 2566772222 EngTrb1ClcltedTurbineOutletTemp 2790;
BA_ "SigType" SG_ 2566772222 EngTrb1ClcltedTurbineOutletTemp 1;
BA_ "SPN" SG_ 2633940734 EngRotationDirection 3669;
BA_ "SigType" SG_ 2633940734 EngRotationDirection 4;
BA_ "SPN" SG_ 2633940734 CrnkAttmptCntOnPrsntStrtAttempt 3671;
BA_ "SigType" SG_ 2633940734 CrnkAttmptCntOnPrsntStrtAttempt 1;
BA_ "SPN" SG_ 2633940734 EngIntakeManifoldPressCtrlMode 5465;
BA_ "SigType" SG_ 2633940734 EngIntakeManifoldPressCtrlMode 4;
BA_ "SPN" SG_ 2633940734 EngRatedSpeed 189;
BA_ "SigType" SG_ 2633940734 EngRatedSpeed 1;
BA_ "SPN" SG_ 2633940734 EngRatedPower 166;
BA_ "SigType" SG_ 2633940734 EngRatedPower 1;
BA_ "SPN" SG_ 2566840318 EngsDsrdOprtngSpdAsymmtryAdjstmn 519;
BA_ "SigType" SG_ 2566840318 EngsDsrdOprtngSpdAsymmtryAdjstmn 1;
BA_ "SystemSignalLongSymbol" SG_ 2566840318 EngsDsrdOprtngSpdAsymmtryAdjstmn "EngsDsrdOprtngSpdAsymmtryAdjstmnt";
BA_ "SPN" SG_ 2566840318 Aftrtratment1ExhaustGasMassFlow 3236;
BA_ "SigType" SG_ 2566840318 Aftrtratment1ExhaustGasMassFlow 1;
BA_ "SPN" SG_ 2566840318 Aftertreatment2IntakeDewPoint 3239;
BA_ "SigType" SG_ 2566840318 Aftertreatment2IntakeDewPoint 4;
BA_ "SPN" SG_ 2566840318 Aftertreatment2ExhaustDewPoint 3240;
BA_ "SigType" SG_ 2566840318 Aftertreatment2ExhaustDewPoint 4;
BA_ "SPN" SG_ 2566840318 Aftertreatment1IntakeDewPoint 3237;
BA_ "SigType" SG_ 2566840318 Aftertreatment1IntakeDewPoint 4;
BA_ "SPN" SG_ 2566840318 Aftertreatment1ExhaustDewPoint 3238;
BA_ "SigType" SG_ 2566840318 Aftertreatment1ExhaustDewPoint 4;
BA_ "SPN" SG_ 2566840318 EstEngPrsticLossesPercentTorque 2978;
BA_ "SigType" SG_ 2566840318 EstEngPrsticLossesPercentTorque 1;
BA_ "SPN" SG_ 2566840318 EngsDesiredOperatingSpeed 515;
BA_ "SigType" SG_ 2566840318 EngsDesiredOperatingSpeed 1;
BA_ "SPN" SG_ 2566840318 NominalFrictionPercentTorque 514;
BA_ "SigType" SG_ 2566840318 NominalFrictionPercentTorque 1;
BA_ "SPN" SG_ 2364539902 SCRThermalManagementActive 5400;
BA_ "SigType" SG_ 2364539902 SCRThermalManagementActive 4;
BA_ "SPN" SG_ 2364539902 MmntryEngMaxPowerEnableFeedback 5021;
BA_ "SigType" SG_ 2364539902 MmntryEngMaxPowerEnableFeedback 4;
BA_ "SPN" SG_ 2364539902 EstPumpingPercentTorque 5398;
BA_ "SigType" SG_ 2364539902 EstPumpingPercentTorque 1;
BA_ "SPN" SG_ 2364539902 DPFThermalManagementActive 5399;
BA_ "SigType" SG_ 2364539902 DPFThermalManagementActive 4;
BA_ "SPN" SG_ 2364539902 ActlMxAvailableEngPercentTorque 3357;
BA_ "SigType" SG_ 2364539902 ActlMxAvailableEngPercentTorque 1;
BA_ "SPN" SG_ 2364539902 AccelPedalPos2 29;
BA_ "SigType" SG_ 2364539902 AccelPedalPos2 1;
BA_ "SPN" SG_ 2364539902 VhclAccelerationRateLimitStatus 2979;
BA_ "SigType" SG_ 2364539902 VhclAccelerationRateLimitStatus 4;
BA_ "SPN" SG_ 2364539902 EngPercentLoadAtCurrentSpeed 92;
BA_ "SigType" SG_ 2364539902 EngPercentLoadAtCurrentSpeed 1;
BA_ "SPN" SG_ 2364539902 AccelPedal2LowIdleSwitch 2970;
BA_ "SigType" SG_ 2364539902 AccelPedal2LowIdleSwitch 4;
BA_ "SPN" SG_ 2364539902 RoadSpeedLimitStatus 1437;
BA_ "SigType" SG_ 2364539902 RoadSpeedLimitStatus 4;
BA_ "SPN" SG_ 2364539902 AccelPedalKickdownSwitch 559;
BA_ "SigType" SG_ 2364539902 AccelPedalKickdownSwitch 4;
BA_ "SPN" SG_ 2364539902 AccelPedal1LowIdleSwitch 558;
BA_ "SigType" SG_ 2364539902 AccelPedal1LowIdleSwitch 4;
BA_ "SPN" SG_ 2364539902 RemoteAccelPedalPos 974;
BA_ "SigType" SG_ 2364539902 RemoteAccelPedalPos 1;
BA_ "SPN" SG_ 2364539902 AccelPedalPos1 91;
BA_ "SigType" SG_ 2364539902 AccelPedalPos1 1;
BA_ "SPN" SG_ 2364540158 SrcAddrssOfCtrllngDvcFrEngCntrl 1483;
BA_ "SigType" SG_ 2364540158 SrcAddrssOfCtrllngDvcFrEngCntrl 1;
BA_ "SPN" SG_ 2364540158 ActlEngPrcntTrqueHighResolution 4154;
BA_ "SigType" SG_ 2364540158 ActlEngPrcntTrqueHighResolution 1;
BA_ "SPN" SG_ 2364540158 EngDemandPercentTorque 2432;
BA_ "SigType" SG_ 2364540158 EngDemandPercentTorque 1;
BA_ "SPN" SG_ 2364540158 EngStarterMode 1675;
BA_ "SigType" SG_ 2364540158 EngStarterMode 4;
BA_ "SPN" SG_ 2364540158 EngSpeed 190;
BA_ "SigType" SG_ 2364540158 EngSpeed 1;
BA_ "SPN" SG_ 2364540158 ActualEngPercentTorque 513;
BA_ "SigType" SG_ 2364540158 ActualEngPercentTorque 1;
BA_ "SPN" SG_ 2364540158 DriversDemandEngPercentTorque 512;
BA_ "SigType" SG_ 2364540158 DriversDemandEngPercentTorque 1;
BA_ "SPN" SG_ 2364540158 EngTorqueMode 899;
BA_ "SigType" SG_ 2364540158 EngTorqueMode 4;
BA_ "SPN" SG_ 2566768126 ECUType 2904;
BA_ "SigType" SG_ 2566768126 ECUType 8;
BA_ "SPN" SG_ 2566768126 ECULocation 2903;
BA_ "SigType" SG_ 2566768126 ECULocation 8;
BA_ "SPN" SG_ 2566768126 ECUSerialNumber 2902;
BA_ "SigType" SG_ 2566768126 ECUSerialNumber 8;
BA_ "SPN" SG_ 2566768126 ECUPartNumber 2901;
BA_ "SigType" SG_ 2566768126 ECUPartNumber 8;
BA_ "SPN" SG_ 2566804734 EngLwLmtThrshldFrMxTrqFrmEngine 1770;
BA_ "SigType" SG_ 2566804734 EngLwLmtThrshldFrMxTrqFrmEngine 1;
BA_ "SPN" SG_ 2566804734 EngLwLmtThrshldFrMxRPMFrmEngine 1768;
BA_ "SigType" SG_ 2566804734 EngLwLmtThrshldFrMxRPMFrmEngine 1;
BA_ "SPN" SG_ 2566804734 EngHghLmtThrshldFrMnCntnsTrqFrmE 1771;
BA_ "SigType" SG_ 2566804734 EngHghLmtThrshldFrMnCntnsTrqFrmE 1;
BA_ "SystemSignalLongSymbol" SG_ 2566804734 EngHghLmtThrshldFrMnCntnsTrqFrmE "EngHghLmtThrshldFrMnCntnsTrqFrmEngn";
BA_ "SPN" SG_ 2566804734 EngHghLmtThrshldFrMnCntnsEngnRPM 1769;
BA_ "SigType" SG_ 2566804734 EngHghLmtThrshldFrMnCntnsEngnRPM 1;
BA_ "SPN" SG_ 2566804734 EngMinContinuousTorque 1775;
BA_ "SigType" SG_ 2566804734 EngMinContinuousTorque 1;
BA_ "SPN" SG_ 2566804734 EngMaxContinuousTorque 1774;
BA_ "SigType" SG_ 2566804734 EngMaxContinuousTorque 1;
BA_ "SPN" SG_ 2566804734 EngMinContinuousRPM 1773;
BA_ "SigType" SG_ 2566804734 EngMinContinuousRPM 1;
BA_ "SPN" SG_ 2566804734 EngMaxContinuousRPM 1772;
BA_ "SigType" SG_ 2566804734 EngMaxContinuousRPM 1;
BA_ "SPN" SG_ 2566767870 BrakeTempWarning 3839;
BA_ "SigType" SG_ 2566767870 BrakeTempWarning 4;
BA_ "SPN" SG_ 2566767870 PrkngBrkeActuatorFullyActivated 5275;
BA_ "SigType" SG_ 2566767870 PrkngBrkeActuatorFullyActivated 4;
BA_ "SPN" SG_ 2566767870 XBRAccelerationLimit 2921;
BA_ "SigType" SG_ 2566767870 XBRAccelerationLimit 1;
BA_ "SPN" SG_ 2566767870 XBRActiveCtrlMode 2918;
BA_ "SigType" SG_ 2566767870 XBRActiveCtrlMode 4;
BA_ "SPN" SG_ 2566767870 XBRSystemState 2917;
BA_ "SigType" SG_ 2566767870 XBRSystemState 4;
BA_ "SPN" SG_ 2566767870 FoundationBrakeUse 2919;
BA_ "SigType" SG_ 2566767870 FoundationBrakeUse 4;
BA_ "SPN" SG_ 2566767870 HillHolderMode 2912;
BA_ "SPN" SG_ 2566767870 HaltBrakeMode 2913;
BA_ "SPN" SG_ 2633936126 BrkLnngRmnngRearAxle3RightWheel 1106;
BA_ "SigType" SG_ 2633936126 BrkLnngRmnngRearAxle3RightWheel 1;
BA_ "SPN" SG_ 2633936126 BrkLnngRmningRearAxle3LeftWheel 1105;
BA_ "SigType" SG_ 2633936126 BrkLnngRmningRearAxle3LeftWheel 1;
BA_ "SPN" SG_ 2633936126 BrkLnngRmnngRearAxle2RightWheel 1104;
BA_ "SigType" SG_ 2633936126 BrkLnngRmnngRearAxle2RightWheel 1;
BA_ "SPN" SG_ 2633936126 BrkLnngRmningRearAxle2LeftWheel 1103;
BA_ "SigType" SG_ 2633936126 BrkLnngRmningRearAxle2LeftWheel 1;
BA_ "SPN" SG_ 2633936126 BrkLnngRmnngRearAxle1RightWheel 1102;
BA_ "SigType" SG_ 2633936126 BrkLnngRmnngRearAxle1RightWheel 1;
BA_ "SPN" SG_ 2633936126 BrkLnngRmningRearAxle1LeftWheel 1101;
BA_ "SigType" SG_ 2633936126 BrkLnngRmningRearAxle1LeftWheel 1;
BA_ "SPN" SG_ 2633936126 BrkLnngRmnngFrontAxleRightWheel 1100;
BA_ "SigType" SG_ 2633936126 BrkLnngRmnngFrontAxleRightWheel 1;
BA_ "SPN" SG_ 2633936126 BrkLnngRmningFrontAxleLeftWheel 1099;
BA_ "SigType" SG_ 2633936126 BrkLnngRmningFrontAxleLeftWheel 1;
BA_ "SPN" SG_ 2566827518 BrkAppPrssHghRngRrAxl3RghtWheel 1098;
BA_ "SigType" SG_ 2566827518 BrkAppPrssHghRngRrAxl3RghtWheel 1;
BA_ "SPN" SG_ 2566827518 BrkAppPrssHghRngRrAxl3LeftWheel 1097;
BA_ "SigType" SG_ 2566827518 BrkAppPrssHghRngRrAxl3LeftWheel 1;
BA_ "SPN" SG_ 2566827518 BrkAppPrssHghRngRrAxl2RghtWheel 1096;
BA_ "SigType" SG_ 2566827518 BrkAppPrssHghRngRrAxl2RghtWheel 1;
BA_ "SPN" SG_ 2566827518 BrkAppPrssHghRngRrAxl2LeftWheel 1095;
BA_ "SigType" SG_ 2566827518 BrkAppPrssHghRngRrAxl2LeftWheel 1;
BA_ "SPN" SG_ 2566827518 BrkAppPrssHghRngRrAxl1RghtWheel 1094;
BA_ "SigType" SG_ 2566827518 BrkAppPrssHghRngRrAxl1RghtWheel 1;
BA_ "SPN" SG_ 2566827518 BrkAppPrssHghRngRrAxl1LeftWheel 1093;
BA_ "SigType" SG_ 2566827518 BrkAppPrssHghRngRrAxl1LeftWheel 1;
BA_ "SPN" SG_ 2566827518 BrkAppPrssHghRngFrntAxlRghtWhel 1092;
BA_ "SigType" SG_ 2566827518 BrkAppPrssHghRngFrntAxlRghtWhel 1;
BA_ "SPN" SG_ 2566827518 BrkAppPrssHghRngFrntAxlLftWheel 1091;
BA_ "SigType" SG_ 2566827518 BrkAppPrssHghRngFrntAxlLftWheel 1;
BA_ "SPN" SG_ 2566832126 RlativeSpeedRearAxle2RightWheel 910;
BA_ "SigType" SG_ 2566832126 RlativeSpeedRearAxle2RightWheel 1;
BA_ "SPN" SG_ 2566832126 RelativeSpeedRearAxle2LeftWheel 909;
BA_ "SigType" SG_ 2566832126 RelativeSpeedRearAxle2LeftWheel 1;
BA_ "SPN" SG_ 2566832126 RlativeSpeedRearAxle1RightWheel 908;
BA_ "SigType" SG_ 2566832126 RlativeSpeedRearAxle1RightWheel 1;
BA_ "SPN" SG_ 2566832126 RelativeSpeedRearAxle1LeftWheel 907;
BA_ "SigType" SG_ 2566832126 RelativeSpeedRearAxle1LeftWheel 1;
BA_ "SPN" SG_ 2566832126 RlativeSpeedFrontAxleRightWheel 906;
BA_ "SigType" SG_ 2566832126 RlativeSpeedFrontAxleRightWheel 1;
BA_ "SPN" SG_ 2566832126 RelativeSpeedFrontAxleLeftWheel 905;
BA_ "SigType" SG_ 2566832126 RelativeSpeedFrontAxleLeftWheel 1;
BA_ "SPN" SG_ 2566832126 FrontAxleSpeed 904;
BA_ "SigType" SG_ 2566832126 FrontAxleSpeed 1;
BA_ "SPN" SG_ 2565865982 EngAuxShutdownSwitch 970;
BA_ "SigType" SG_ 2565865982 EngAuxShutdownSwitch 4;
BA_ "SPN" SG_ 2565865982 SrcAddrssOfCtrllngDvcFrBrkCntrl 1481;
BA_ "SigType" SG_ 2565865982 SrcAddrssOfCtrllngDvcFrBrkCntrl 1;
BA_ "SPN" SG_ 2565865982 BrakePedalPos 521;
BA_ "SigType" SG_ 2565865982 BrakePedalPos 1;
BA_ "SPN" SG_ 2565865982 TrctrMntdTrilerABSWarningSignal 1792;
BA_ "SigType" SG_ 2565865982 TrctrMntdTrilerABSWarningSignal 4;
BA_ "SPN" SG_ 2565865982 TrailerABSStatus 1836;
BA_ "SigType" SG_ 2565865982 TrailerABSStatus 4;
BA_ "SPN" SG_ 2565865982 HaltBrakeSwitch 2911;
BA_ "SigType" SG_ 2565865982 HaltBrakeSwitch 4;
BA_ "SPN" SG_ 2565865982 ATC_ASRInformationSignal 1793;
BA_ "SigType" SG_ 2565865982 ATC_ASRInformationSignal 4;
BA_ "SPN" SG_ 2565865982 ABS_EBSAmberWarningSignal 1438;
BA_ "SigType" SG_ 2565865982 ABS_EBSAmberWarningSignal 4;
BA_ "SPN" SG_ 2565865982 EBSRedWarningSignal 1439;
BA_ "SigType" SG_ 2565865982 EBSRedWarningSignal 4;
BA_ "SPN" SG_ 2565865982 ABSFullyOperational 1243;
BA_ "SigType" SG_ 2565865982 ABSFullyOperational 4;
BA_ "SPN" SG_ 2565865982 EngRetarderSelection 973;
BA_ "SigType" SG_ 2565865982 EngRetarderSelection 1;
BA_ "SPN" SG_ 2565865982 RemoteAccelEnableSwitch 969;
BA_ "SigType" SG_ 2565865982 RemoteAccelEnableSwitch 4;
BA_ "SPN" SG_ 2565865982 EngDerateSwitch 971;
BA_ "SigType" SG_ 2565865982 EngDerateSwitch 4;
BA_ "SPN" SG_ 2565865982 AccelInterlockSwitch 972;
BA_ "SigType" SG_ 2565865982 AccelInterlockSwitch 4;
BA_ "SPN" SG_ 2565865982 TractionCtrlOverrideSwitch 1238;
BA_ "SigType" SG_ 2565865982 TractionCtrlOverrideSwitch 4;
BA_ "SPN" SG_ 2565865982 ASRHillHolderSwitch 577;
BA_ "SigType" SG_ 2565865982 ASRHillHolderSwitch 4;
BA_ "SPN" SG_ 2565865982 ASROffroadSwitch 576;
BA_ "SigType" SG_ 2565865982 ASROffroadSwitch 4;
BA_ "SPN" SG_ 2565865982 ABSOffroadSwitch 575;
BA_ "SigType" SG_ 2565865982 ABSOffroadSwitch 4;
BA_ "SPN" SG_ 2565865982 EBSBrakeSwitch 1121;
BA_ "SigType" SG_ 2565865982 EBSBrakeSwitch 4;
BA_ "SPN" SG_ 2565865982 AntiLockBrakingActive 563;
BA_ "SigType" SG_ 2565865982 AntiLockBrakingActive 4;
BA_ "SPN" SG_ 2565865982 ASRBrakeCtrlActive 562;
BA_ "SigType" SG_ 2565865982 ASRBrakeCtrlActive 4;
BA_ "SPN" SG_ 2565865982 ASREngCtrlActive 561;
BA_ "SigType" SG_ 2565865982 ASREngCtrlActive 4;
BA_ "SPN" SG_ 2565867262 RearAxleGroupEngagementStatus 3820;
BA_ "SigType" SG_ 2565867262 RearAxleGroupEngagementStatus 4;
BA_ "SPN" SG_ 2565867262 FrontAxleGroupEngagementStatus 3819;
BA_ "SigType" SG_ 2565867262 FrontAxleGroupEngagementStatus 4;
BA_ "SPN" SG_ 2565867262 DiffLockStateCentralRear 566;
BA_ "SigType" SG_ 2565867262 DiffLockStateCentralRear 4;
BA_ "SPN" SG_ 2565867262 DiffLockStateCentralFront 565;
BA_ "SigType" SG_ 2565867262 DiffLockStateCentralFront 4;
BA_ "SPN" SG_ 2565867262 DiffLockStateCentral 564;
BA_ "SigType" SG_ 2565867262 DiffLockStateCentral 4;
BA_ "SPN" SG_ 2565867262 DiffLockStateRearAxle2 570;
BA_ "SigType" SG_ 2565867262 DiffLockStateRearAxle2 4;
BA_ "SPN" SG_ 2565867262 DiffLockStateRearAxle1 569;
BA_ "SigType" SG_ 2565867262 DiffLockStateRearAxle1 4;
BA_ "SPN" SG_ 2565867262 DiffLockStateFrontAxle2 568;
BA_ "SigType" SG_ 2565867262 DiffLockStateFrontAxle2 4;
BA_ "SPN" SG_ 2565867262 DiffLockStateFrontAxle1 567;
BA_ "SigType" SG_ 2565867262 DiffLockStateFrontAxle1 4;
BA_ "SPN" SG_ 2565867262 Location 927;
BA_ "SigType" SG_ 2565867262 Location 1;
BA_ "SPN" SG_ 2566821118 SeaWaterPumpOutletPress 2435;
BA_ "SigType" SG_ 2566821118 SeaWaterPumpOutletPress 1;
BA_ "SPN" SG_ 2566821118 EngAuxCoolantTemp 1212;
BA_ "SigType" SG_ 2566821118 EngAuxCoolantTemp 1;
BA_ "SPN" SG_ 2566821118 EngAuxCoolantPress 1203;
BA_ "SigType" SG_ 2566821118 EngAuxCoolantPress 1;
BA_ "SPN" SG_ 2566810622 Driver2 1626;
BA_ "SigType" SG_ 2566810622 Driver2 8;
BA_ "SPN" SG_ 2566810622 Driver1 1625;
BA_ "SigType" SG_ 2566810622 Driver1 8;
BA_ "SPN" SG_ 2566847742 FuelLevel2 38;
BA_ "SigType" SG_ 2566847742 FuelLevel2 1;
BA_ "SPN" SG_ 2566847742 FuelLevel1 96;
BA_ "SigType" SG_ 2566847742 FuelLevel1 1;
BA_ "SPN" SG_ 2566847742 CargoAmbientTemp 169;
BA_ "SigType" SG_ 2566847742 CargoAmbientTemp 1;
BA_ "SPN" SG_ 2566847742 EngOilFilterDiffPress 99;
BA_ "SigType" SG_ 2566847742 EngOilFilterDiffPress 1;
BA_ "SPN" SG_ 2566847742 EngFuelFilterDiffPress 1382;
BA_ "SigType" SG_ 2566847742 EngFuelFilterDiffPress 1;
BA_ "SPN" SG_ 2566847742 WasherFluidLevel 80;
BA_ "SigType" SG_ 2566847742 WasherFluidLevel 1;
BA_ "SPN" SG_ 2566768382 EngStartEnableDevice2Config 2898;
BA_ "SigType" SG_ 2566768382 EngStartEnableDevice2Config 4;
BA_ "SPN" SG_ 2566768382 EngStartEnableDevice1Config 2899;
BA_ "SigType" SG_ 2566768382 EngStartEnableDevice1Config 4;
BA_ "SPN" SG_ 2566768382 EngStartEnableDevice2 1804;
BA_ "SigType" SG_ 2566768382 EngStartEnableDevice2 4;
BA_ "SPN" SG_ 2566768382 EngStartEnableDevice1 626;
BA_ "SigType" SG_ 2566768382 EngStartEnableDevice1 4;
BA_ "SPN" SG_ 2566811902 PoweredVehicleWeight 1585;
BA_ "SigType" SG_ 2566811902 PoweredVehicleWeight 1;
BA_ "SPN" SG_ 2566811902 GrossCombinationVehicleWeight 1760;
BA_ "SigType" SG_ 2566811902 GrossCombinationVehicleWeight 1;
BA_ "SPN" SG_ 2563768062 MxCntnuousRetarderTorqueLimitRq 1791;
BA_ "SigType" SG_ 2563768062 MxCntnuousRetarderTorqueLimitRq 1;
BA_ "SPN" SG_ 2563768062 MnCntnuousRetarderTorqueLimitRq 1790;
BA_ "SigType" SG_ 2563768062 MnCntnuousRetarderTorqueLimitRq 1;
BA_ "SPN" SG_ 2563768062 MxCntinuousRetarderSpeedLimitRq 1789;
BA_ "SigType" SG_ 2563768062 MxCntinuousRetarderSpeedLimitRq 1;
BA_ "SPN" SG_ 2563768062 MnCntinuousRetarderSpeedLimitRq 1788;
BA_ "SigType" SG_ 2563768062 MnCntinuousRetarderSpeedLimitRq 1;
BA_ "SPN" SG_ 2563768062 EngTorqueLimitRqMaxContinuous 1787;
BA_ "SigType" SG_ 2563768062 EngTorqueLimitRqMaxContinuous 1;
BA_ "SPN" SG_ 2563768062 EngTorqueLimitRqMinContinuous 1786;
BA_ "SigType" SG_ 2563768062 EngTorqueLimitRqMinContinuous 1;
BA_ "SPN" SG_ 2563768062 EngSpeedLimitRqMaxContinuous 1785;
BA_ "SigType" SG_ 2563768062 EngSpeedLimitRqMaxContinuous 1;
BA_ "SPN" SG_ 2563768062 EngSpeedLimitRqMinContinuous 1784;
BA_ "SigType" SG_ 2563768062 EngSpeedLimitRqMinContinuous 1;
BA_ "SPN" SG_ 2633924862 EngAverageCombustionTime 1465;
BA_ "SigType" SG_ 2633924862 EngAverageCombustionTime 1;
BA_ "SPN" SG_ 2633924862 EngDesiredCombustionTime 1464;
BA_ "SigType" SG_ 2633924862 EngDesiredCombustionTime 1;
BA_ "SPN" SG_ 2633924606 EngCyl20CombustionTime 1463;
BA_ "SigType" SG_ 2633924606 EngCyl20CombustionTime 1;
BA_ "SPN" SG_ 2633924606 EngCyl19CombustionTime 1462;
BA_ "SigType" SG_ 2633924606 EngCyl19CombustionTime 1;
BA_ "SPN" SG_ 2633924606 EngCyl18CombustionTime 1461;
BA_ "SigType" SG_ 2633924606 EngCyl18CombustionTime 1;
BA_ "SPN" SG_ 2633924606 EngCyl17CombustionTime 1460;
BA_ "SigType" SG_ 2633924606 EngCyl17CombustionTime 1;
BA_ "SPN" SG_ 2633924350 EngCyl16CombustionTime 1459;
BA_ "SigType" SG_ 2633924350 EngCyl16CombustionTime 1;
BA_ "SPN" SG_ 2633924350 EngCyl15CombustionTime 1458;
BA_ "SigType" SG_ 2633924350 EngCyl15CombustionTime 1;
BA_ "SPN" SG_ 2633924350 EngCyl14CombustionTime 1457;
BA_ "SigType" SG_ 2633924350 EngCyl14CombustionTime 1;
BA_ "SPN" SG_ 2633924350 EngCyl13CombustionTime 1456;
BA_ "SigType" SG_ 2633924350 EngCyl13CombustionTime 1;
BA_ "SPN" SG_ 2633924094 EngCyl12CombustionTime 1455;
BA_ "SigType" SG_ 2633924094 EngCyl12CombustionTime 1;
BA_ "SPN" SG_ 2633924094 EngCyl11CombustionTime 1454;
BA_ "SigType" SG_ 2633924094 EngCyl11CombustionTime 1;
BA_ "SPN" SG_ 2633924094 EngCyl10CombustionTime 1453;
BA_ "SigType" SG_ 2633924094 EngCyl10CombustionTime 1;
BA_ "SPN" SG_ 2633924094 EngCyl9CombustionTime 1452;
BA_ "SigType" SG_ 2633924094 EngCyl9CombustionTime 1;
BA_ "SPN" SG_ 2633923838 EngCyl8CombustionTime 1451;
BA_ "SigType" SG_ 2633923838 EngCyl8CombustionTime 1;
BA_ "SPN" SG_ 2633923838 EngCyl7CombustionTime 1450;
BA_ "SigType" SG_ 2633923838 EngCyl7CombustionTime 1;
BA_ "SPN" SG_ 2633923838 EngCyl6CombustionTime 1449;
BA_ "SigType" SG_ 2633923838 EngCyl6CombustionTime 1;
BA_ "SPN" SG_ 2633923838 EngCyl5CombustionTime 1448;
BA_ "SigType" SG_ 2633923838 EngCyl5CombustionTime 1;
BA_ "SPN" SG_ 2633923582 EngCyl4CombustionTime 1447;
BA_ "SigType" SG_ 2633923582 EngCyl4CombustionTime 1;
BA_ "SPN" SG_ 2633923582 EngCyl3CombustionTime 1446;
BA_ "SigType" SG_ 2633923582 EngCyl3CombustionTime 1;
BA_ "SPN" SG_ 2633923582 EngCyl2CombustionTime 1445;
BA_ "SigType" SG_ 2633923582 EngCyl2CombustionTime 1;
BA_ "SPN" SG_ 2633923582 EngCyl1CombustionTime 1444;
BA_ "SigType" SG_ 2633923582 EngCyl1CombustionTime 1;
BA_ "SPN" SG_ 2633878014 TotalCountOfConfigChangesMade 2887;
BA_ "SigType" SG_ 2633878014 TotalCountOfConfigChangesMade 1;
BA_ "SPN" SG_ 2566771966 TransOilLevelRq 3809;
BA_ "SigType" SG_ 2566771966 TransOilLevelRq 4;
BA_ "SPN" SG_ 2566771966 FifthWheelReleaseCtrl 3314;
BA_ "SigType" SG_ 2566771966 FifthWheelReleaseCtrl 4;
BA_ "SPN" SG_ 2566771966 FfthWhlRlaseCtrlSecurityLockout 3315;
BA_ "SigType" SG_ 2566771966 FfthWhlRlaseCtrlSecurityLockout 4;
BA_ "SPN" SG_ 2566771966 TransferCaseSelectorSwitch 2796;
VAL_ 2566774014 SlowVesselModeStatus 3 "TakeNoAction" 2 "Reserved" 1 "SlowVesselModeIsACTIVE" 0 "SlowVesselModeIsOFF" ;
VAL_ 2566774014 TrollingModeStatus 3 "TakeNoAction" 2 "Reserved" 1 "TrollingModeIsACTIVE" 0 "TrollingModeIsOFF" ;
VAL_ 2566774014 EngThrttlSynchrnztionModeStatus 15 "TakeNoAction" 5 "1110Reserved" 4 "SynchronizedMaster" 3 "SynchronizedStarboard" 2 "SynchronizedPort" 1 "SynchronizedCenter" 0 "NotSynchronized" ;
VAL_ 2432595710 DisplayDeadbands 15 "NotAvailable" 3 "1110Reserved" 2 "Wide_24mm" 1 "Standard_12mm" 0 "Narrow_45mm" ;
VAL_ 2432595710 LEDPatternCtrl 15 "NotAvailable" 3 "1110Reserved" 2 "7Channel" 1 "Offset" 0 "5Channel" ;
VAL_ 2432595710 LEDDisplayDeadbandCtrl 15 "NotAvailableNotApplicable" 5 "1110Reserved" 4 "_1Mm" 3 "_5Mm" 2 "_24Mm" 1 "_12Mm" 0 "_45Mm" ;
VAL_ 2432595710 LEDDisplayModeCtrl 14 "NotAvailableNotApplicable" 3 "1110Reserved" 2 "CenterOnGradeDisplayMode2" 1 "OffsetOnGradeDisplayMode" 0 "CenterOnGradeDisplayMode1" ;
VAL_ 2432595710 LEDDisplayData1 511 "NotAvailable" 254 "Error" 159 "NoData" 149 "HighCoarse" 148 "HighMedium_Coarse" 147 "HighMedium" 146 "HighMedium_Fine" 145 "HighFine" 144 "OnGrade" 132 "LowFine" 131 "LowMedium_Fine" 130 "LowMedium" 129 "LowMedium_Coarse" 128 "LowCoarse" 32 "LowCoarseLEDOn" 16 "LowFineLEDOn" 8 "OngradeLEDOn" 4 "HighFineLEDOn" 2 "HighCoarseLEDOn" ;
VAL_ 2365486590 LaserReceiverType 1 "LinearLaserReceiver" 0 "Reserved" ;
VAL_ 2365485566 LaserTracerInformation 32 "Curb" 16 "Stringline" 8 "PreviousPass" 4 "ValidTarget" 2 "LaserIsReady" 1 "LaserPowerIsOn" ;
VAL_ 2365485566 LEDDisplayData2 254 "Error" 159 "NoData" 149 "HighCoarse" 148 "HighMedium_Coarse" 147 "HighMedium" 146 "HighMedium_Fine" 145 "HighFine" 144 "OnGrade" 132 "LowFine" 131 "LowMedium_Fine" 130 "LowMedium" 129 "LowMedium_Coarse" 128 "LowCoarse" 64 "RightLEDOn" 32 "LeftLEDOn" 16 "DownLEDOn" 8 "UpLEDOn" 4 "OngradeCLEDOn" 2 "OngradeBLEDOn" 1 "OngradeALEDOn" ;
VAL_ 2364542462 SdshftDsrdBldOffsetOperatorCtrl 15 "NotInstalled" 14 "ErrorIndicator" 4 "1101Reserved" 3 "AutomaticOperatorCtrlRq" 2 "ManualOperatorCtrlRq" 0 "NoOperatorCtrlRq" 1 "MomentaryOperatorCtrlRq" ;
VAL_ 2364542462 SdshftBldCtrlMdeOperatorControl 15 "NotInstalled" 14 "ErrorIndicator" 3 "1101Reserved" 2 "DecrementOperatorCtrlRq" 0 "NoOperatorCtrlRq" 1 "IncrementOperatorCtrlRq" ;
VAL_ 2364542462 RghtDsrdBladeOffsetOperatorCtrl 15 "NotInstalled" 14 "ErrorIndicator" 3 "1101Reserved" 2 "DecrementOperatorCtrlRq" 0 "NoOperatorCtrlRq" 1 "OprtrCtrlSttCnBRdInTwWysOnMthdU" ;
VAL_ 2364542462 RghtBldeCtrlModeOperatorControl 15 "NotInstalled" 14 "ErrorIndicator" 3 "AutomaticOperatorCtrlRq" 2 "ManualOperatorCtrlRq" 0 "NoChange" 1 "MomentaryOperatorCtrlRq" ;
VAL_ 2364542462 LftDsredBladeOffsetOperatorCtrl 15 "NotInstalled" 14 "ErrorIndicator" 3 "1101Reserved" 2 "DecrementOperatorCtrlRq" 0 "NoOperatorCtrlRq" 1 "OprtrCtrlSttCnBRdInTwWysOnMthdU" ;
VAL_ 2364542462 LftBladeCtrlModeOperatorControl 15 "NotInstalled" 14 "ErrorIndicator" 12 "1101Reserved" 3 "AutomaticOperatorCtrlRq" 2 "ManualOperatorCtrlRq" 0 "NoChange" 1 "OprtrCtrlSttCnBRdInTwWysOnMthdU" ;
VAL_ 2364542462 BladeAutoModeCmd 15 "NotSupported" 14 "ErrorIndicator" 4 "AutoNotAllowed" 3 "SrvcMdAtAllwdOnlyDrngSrvceModes" 2 "SspndAtTmprarilySuspendAutoMode" 1 "ActvtyAllwsAtMstDtctOprtrBfrAtA" 0 "AutoAllowed" ;
VAL_ 2364542462 DesiredGradeOffsetSwitch 15 "NotInstalled" 14 "ErrorIndicator" 2 "DecrementButtonPressed" 0 "NoButtonPressed" 1 "SwtchSttCnBRdInTwWysOnMthdUssTh" ;
VAL_ 2364542462 BladeCtrlModeSwitch 15 "NotInstalled" 14 "ErrorIndicator" 3 "AutomaticButtonPressed" 2 "ManualButtonPressed" 0 "NoButtonPressed" 1 "SwtchSttCnBRdInTwWysOnMthdUssTh" ;
VAL_ 2364542462 StElvtnSnsor2ReferenceElevation 3 "DontCare_TakeNoAction" 2 "Reserved" 1 "SetReferenceElevation" 0 "DoNotSetReferenceElevation" ;
VAL_ 2364542462 StElvtnSnsor1ReferenceElevation 3 "DontCare_TakeNoAction" 2 "Reserved" 1 "SetReferenceElevation" 0 "DoNotSetReferenceElevation" ;
VAL_ 2633937918 FlexibleFuelPercentage 4 "MansAlcoholAsFuelAndNothingElse" ;
VAL_ 2633883646 FrontWheelDriveActuatorStatus 3 "NotAvailable" 2 "Error" 1 "FrontWheelDriveActuatorEngaged" 0 "FrntWhelDriveActuatorNotEngaged" ;
VAL_ 2633880062 FMSstandardRqsSupported 3 "DontCare" 2 "Reserved" 1 "OnRqModeIsSupported" 0 "OnRqModeIsNotSupported" ;
VAL_ 2633880062 FMSstandardDiagnosticsSupported 3 "DontCare" 2 "Reserved" 1 "DiagnosticsIsSupported" 0 "DiagnosticsIsNotSupported" ;
VAL_ 2566806526 LnDprtureIndicationEnableStatus 3 "NotUsed" 2 "Reserved" 1 "LaneDepartureIndicationEnabled" 0 "LaneDepartureIndicationDisabled" ;
VAL_ 2566806526 LaneTrackingStatusLeftSide 3 "DontCare_TakeNoAction" 2 "Reserved" 1 "TrackingLeftSide" 0 "NotTrackingLeftSide" ;
VAL_ 2566806526 LaneTrackingStatusRightSide 3 "DontCare_TakeNoAction" 2 "Reserved" 1 "TrackingRightSide" 0 "NotTrackingRightSide" ;
VAL_ 2431649790 LaneDepartureImminentLeftSide 3 "NotUsed" 2 "Reserved" 1 "Imminent" 0 "NotImminent" ;
VAL_ 2431649790 LaneDepartureImminentRightSide 3 "NotUsed" 2 "Reserved" 1 "Imminent" 0 "NotImminent" ;
VAL_ 2431649790 LaneDepartureRight 3 "TakeNoAction" 2 "Reserved" 1 "MddlOfVhclDprtsThLnTThRightSide" 0 "MddlOfVhclDsNtDprtThLnTThRghtSd" ;
VAL_ 2431649790 LaneDepartureLeft 3 "TakeNoAction" 2 "Reserved" 1 "MddlOfVhclDprtsThLnTTheLeftSide" 0 "MddlOfVhclDsNtDprtThLnTThLftSde" ;
VAL_ 2633929214 EngFuelLeakage2 3 "NotAvailable" 2 "Error" 1 "LeakageDetected" 0 "NoLeakageDetected" ;
VAL_ 2633929214 EngFuelLeakage1 3 "NotAvailable" 2 "Error" 1 "LeakageDetected" 0 "NoLeakageDetected" ;
VAL_ 2566831614 FanDriveState 15 "NotAvailable" 14 "Other" 13 "EngBrake" 12 "Timer" 11 "A_CSystem" 10 "TransRetarder" 9 "ManualCtrl" 8 "ReverseOperation" 7 "DefaultOperation" 6 "ExcessiveHydOilTemp" 5 "ExcessiveTransOilTemp" 4 "ExcessiveEngCoolantTemp" 3 "ExcessiveEngOilTemp" 2 "ExcessiveEngAirTemp" 1 "EngSystemGeneral" 0 "FanOff" ;
VAL_ 2364542206 TransTorqueConverterRatio 64256 "RatioCannotBeProperlyDetermined" ;
VAL_ 2566802174 TrnsRvrseGearShiftInhibitStatus 3 "NotAvailable" 2 "Error" 1 "RvrsGrShftsArCurrentlyInhibited" 0 "RvrsGrShiftsAreCurrentlyAllowed" ;
VAL_ 2566802174 TrnsCrrntRangeDisplayBlankState 3 "NotSupported" 2 "Error" 1 "Blanked" 0 "NotBlanked" ;
VAL_ 2566802174 TransWarningIndicator 3 "NotAvailable" 2 "TransWarningIndicatorIsFlashing" 1 "TrnsWrnngIndctrIsOnContinuously" 0 "TransWarningIndicatorIsOff" ;
VAL_ 2566802174 TransMode8Indicator 3 "TakeNoAction" 2 "Reserved" 1 "Enable" 0 "Disable" ;
VAL_ 2566802174 TransMode7Indicator 3 "TakeNoAction" 2 "Reserved" 1 "Enable" 0 "Disable" ;
VAL_ 2566802174 TransMode6Indicator 3 "TakeNoAction" 2 "Reserved" 1 "Enable" 0 "Disable" ;
VAL_ 2566802174 TransMode5Indicator 3 "TakeNoAction" 2 "Reserved" 1 "Enable" 0 "Disable" ;
VAL_ 2566802174 TransMode1Indicator 3 "NotAvailable" 2 "Error" 1 "TransMode1Active" 0 "TransMode1NotActive" ;
VAL_ 2566802174 TransMode2Indicator 3 "NotAvailable" 2 "Error" 1 "TransMode2Active" 0 "TransMode2NotActive" ;
VAL_ 2566802174 TransMode3Indicator 3 "NotAvailable" 2 "Error" 1 "TransMode3Active" 0 "TransMode3NotActive" ;
VAL_ 2566802174 TransMode4Indicator 3 "NotAvailable" 2 "Error" 1 "TransMode4Active" 0 "TransMode4NotActive" ;
VAL_ 2566802174 TransShiftInhibitIndicator 3 "TakeNoAction" 2 "Reserved" 1 "ActiveShiftIsInhibited" 0 "InactiveShiftIsNotInhibited" ;
VAL_ 2566802174 TransEngCrankEnable 3 "NotAvailable" 2 "Error" 1 "CrnkngEnbldEngCrnkngIsAllwdByTr" 0 "CrnkngDsbldEngCrnkngIsPrhbtdByT" ;
VAL_ 2566802174 ActiveShiftConsoleIndicator 3 "NotAvailable" 2 "Reserved" 1 "SecondShiftConsoleIsActive" 0 "PrimaryShiftConsoleIsActive" ;
VAL_ 2566802174 TransReadyForBrakeRelease 3 "NotAvailable" 2 "Error" 1 "TransReadyForBrakeRelease" 0 "TransNotReadyForBrakeRelease" ;
VAL_ 2566802174 TransRqedRangeDisplayFlashState 3 "TakeNoAction" 2 "Reserved" 1 "ActvTrnsRqdRngDsplyShldBFlshing" 0 "InctvTrnsRqdRngDsplyShldNtBFlsh" ;
VAL_ 2566802174 TransRqedRangeDisplayBlankState 3 "TakeNoAction" 2 "Reserved" 1 "ActvTrnsRqdRngDsplyShldBBlanked" 0 "InctvTrnsRqdRngDsplyShldNtBBlnk" ;
VAL_ 2566802174 TransServiceIndicator 3 "NotAvailable" 2 "ServiceIndicatorFlashing" 1 "ServiceIndicatorOn" 0 "SeviceIndicatorOff" ;
VAL_ 2633935870 LowestPossibleGear 251 "Park" ;
VAL_ 2633935870 HighestPossibleGear 251 "Park" ;
VAL_ 2633935870 RecommendedGear 251 "Park" ;
VAL_ 2633942014 TransForwardDirectionSwitch 3 "NotAvailable" 2 "Error" 1 "On" 0 "Off" ;
VAL_ 2633942014 TransNeutralSwitch 3 "NotAvailable" 2 "Error" 1 "On" 0 "Off" ;
VAL_ 2633942014 TransReverseDirectionSwitch 3 "NotAvailable" 2 "Error" 1 "On" 0 "Off" ;
VAL_ 2633942014 TransLowRangeSenseSwitch 3 "NotAvailable" 2 "Error" 1 "On" 0 "Off" ;
VAL_ 2633942014 TransHighRangeSenseSwitch 3 "NotAvailable" 2 "Error" 1 "On" 0 "Off" ;
VAL_ 2633943038 TransInertiaBrakeActuator 3 "NotAvailable" 2 "Error" 1 "On" 0 "Off" ;
VAL_ 2633943038 TransDefuelActuator 3 "NotAvailable" 2 "Error" 1 "On" 0 "Off" ;
VAL_ 2633943038 TransLockupClutchActuator 3 "NotAvailable" 2 "Error" 1 "On" 0 "Off" ;
VAL_ 2633943038 TransClutchActuator 3 "NotAvailable" 2 "Error" 1 "On" 0 "Off" ;
VAL_ 2633943038 TransSplitterIndirectActuator 3 "NotAvailable" 2 "Error" 1 "On" 0 "Off" ;
VAL_ 2633943038 TransSplitterDirectActuator 3 "NotAvailable" 2 "Error" 1 "On" 0 "Off" ;
VAL_ 2633943038 TransRangeLowActuator 3 "NotAvailable" 2 "Error" 1 "On" 0 "Off" ;
VAL_ 2633943038 TransRangeHighActuator 3 "NotAvailable" 2 "Error" 1 "On" 0 "Off" ;
VAL_ 2633943038 TransShiftFingerGearActuator2 3 "NotAvailable" 2 "Error" 1 "On" 0 "Off" ;
VAL_ 2633943038 TransShiftFingerRailActuator2 3 "NotAvailable" 2 "Error" 1 "On" 0 "Off" ;
VAL_ 2633943038 TransShiftFingerGearActuator1 3 "NotAvailable" 2 "Error" 1 "On" 0 "Off" ;
VAL_ 2633943038 TransShiftFingerRailActuator1 3 "NotAvailable" 2 "Error" 1 "On" 0 "Off" ;
VAL_ 2633943038 TrnsShftFngrCenterRailIndicator 3 "NotAvailable" 2 "Error" 1 "On" 0 "Off" ;
VAL_ 2633943038 TrnsShftFngrEngagementIndicator 3 "NotAvailable" 2 "Error" 1 "On" 0 "Off" ;
VAL_ 2633943038 TrnsShiftFingerNeutralIndicator 3 "NotAvailable" 2 "Error" 1 "On" 0 "Off" ;
VAL_ 2565867006 TransCurrentGear 251 "Park" ;
VAL_ 2565867006 TransSelectedGear 251 "Park" ;
VAL_ 2364539646 TrnsTrqueConverterLockupEngaged 3 "NotAvailable" 2 "Error" 1 "TorqueConverterLockupEngaged" 0 "TorqueConverterLockupDisengaged" ;
VAL_ 2364539646 TrnsTrqCnvrtrLckpTrnstnInPrcess 3 "NotAvailable" 2 "Error" 1 "TransitionIsInProcess" 0 "TransitionIsNotInProcess" ;
VAL_ 2364539646 MomentaryEngMaxPowerEnable 3 "notAvailable" 2 "fault" 1 "mmntarilyRqingMaxPowerAvailable" 0 "notRqingMaxPowerAvailable" ;
VAL_ 2364539646 ProgressiveShiftDisable 2 "Reserved" 3 "TakeNoAction" 1 "ProgressiveShiftIsDisabled" 0 "ProgressiveShiftIsNotDisabled" ;
VAL_ 2364539646 EngMomentaryOverspeedEnable 3 "TakeNoAction" 2 "Reserved" 1 "MomentaryEngOverspeedIsEnabled" 0 "MomentaryEngOverspeedIsDisabled" ;
VAL_ 2364539646 TransShiftInProcess 3 "NotAvailable" 2 "Error" 1 "ShiftInProcess" 0 "ShiftIsNotInProcess" ;
VAL_ 2364539646 TransDrivelineEngaged 3 "NotAvailable" 2 "Error" 1 "DrivelineEngaged" 0 "DrivelineDisengaged" ;
VAL_ 2565868542 SterableLiftAxleLoweringInhibit 3 "NotAvailable" 2 "Reserved" 1 "LoweringInhibited" 0 "LoweringAllowed" ;
VAL_ 2565868542 TypeOfSteerTrans 15 "NotAvailable" 4 "1110ReservedForSAEAssignment" 3 "HybrdStrTrnsAStrngTrnsmssnInWhc" 2 "PrlyElctrcStrTrnsAStrngTrnsmssn" 1 "PrlyHydStrTrnsAStrngTrnsmssnInW" 0 "PrlyMchStrTrnsAStrngTrnsmssnInW" ;
VAL_ 2565868542 TypeOfSteerForces 15 "NotAvailable" 4 "1110ReservedForSAEAssignment" 3 "SlfTrckngStrEqpmntASystmDsgndTC" 2 "FllPwrStrEqpmntStrngFrcsArPrvdd" 1 "PwrAssstdStrEqpmntStrngFrcsRslt" 0 "MnlStrEqpmntStrngFrcsRsltSllyFr" ;
VAL_ 2565868542 SteerType 15 "NotAvailable" 2 "1110ReservedForAssignmentBySAE" 1 "AxStrEqpmntASystmInWhchWhlsOnAx" 0 "MnStrSystmStrngEqpmntOfAVhclWhc" ;
VAL_ 2565868542 StatusOfSteerAxle 15 "NotAvailable" 6 "1110ReservedForSAEAssignment" 5 "AxleSteerInSpecialMode" 4 "AxleNotActiveBecauseOfAnError" 3 "AxleCenteredBecauseOfAnError" 2 "AxleCentered" 1 "AxleSteerActive" 0 "AxleSteerNotActive" ;
VAL_ 2633941758 TransOutputRetarder 3 "NotAvailable" 2 "Error" 1 "On" 0 "Off" ;
VAL_ 2565865726 RetarderRoadSpeedLimitSwitch 3 "NotAvailable" 2 "ErrorIndicator" 1 "RdSpdLmtngByRtrdrIsEnbldRdSpdTh" 0 "RdSpdLmtingByRetarderIsDisabled" ;
VAL_ 2565865726 RetarderRoadSpeedExceededStatus 3 "DontCare_TakeNoAction" 2 "Reserved" 1 "RdSpdIsAbvThrshldAndRtrdrIsAllw" 0 "RoadSpeedIsBelowThreshold" ;
VAL_ 2565865726 RetarderRqingBrakeLight 3 "NotAvailable_TakeNoAction" 2 "Reserved" 1 "RtrdrIsRqngThtBrkLghtsArIllmntd" 0 "RtrdrIsNtRqngThtBrkLghtsArIllmn" ;
VAL_ 2565865726 EngCoolantLoadIncrease 3 "NotAvailable" 2 "Error" 1 "CoolantLoadIncreasePossible" 0 "NoCoolantLoadIncrease" ;
VAL_ 2565865726 RetarderEnableShiftAssistSwitch 3 "NotAvailable" 2 "Error" 1 "RetarderShiftAssistEnabled" 0 "RetarderShiftAssistDisabled" ;
VAL_ 2565865726 RetarderEnableBrakeAssistSwitch 3 "NotAvailable" 2 "Error" 1 "RetarderBrakeAssistEnabled" 0 "RetarderBrakeAssistDisabled" ;
VAL_ 2633935358 EngExhstGsOxygnSnsrClsdLpOprton 3 "DontCare_TakeNoAction" 2 "Reserved" 1 "EngUsngExhstGsOxygnSnsrFrAClsdL" 0 "EngNtUsngExhaustGasOxygenSensor" ;
VAL_ 2365447166 Jystck3GripXAxisDetentPosStatus 3 "NotAvailable" 2 "ErrorIndicator" 1 "InDetentPos" 0 "NotInDetentPos" ;
VAL_ 2365447166 Jystck3GripYAxisDetentPosStatus 3 "NotAvailable" 2 "ErrorIndicator" 1 "InDetentPos" 0 "NotInDetentPos" ;
VAL_ 2365447166 Jystck3ThetaAxisDetentPosStatus 3 "NotAvailable" 2 "ErrorIndicator" 1 "InDetentPos" 0 "NotInDetentPos" ;
VAL_ 2365447166 Jystck3ThtAxsClckwsPstvPsStatus 3 "NotAvailable" 2 "ErrorIndicator" 1 "OnPositiveSideOfNeutral" 0 "NotOnPositiveSideOfNeutral" ;
VAL_ 2365447166 Jystck3ThtaAxisNeutralPosStatus 3 "NotAvailable" 2 "ErrorIndicator" 1 "InNeutralPos" 0 "NotInNeutralPos" ;
VAL_ 2365447166 Jystck3GrpYAxsLvrFrwrdPstvPsStts 3 "NotAvailable" 2 "ErrorIndicator" 1 "OnPositiveSideOfNeutral" 0 "NotOnPositiveSideOfNeutral" ;
VAL_ 2365447166 Jystck3GrpYAxsLvrBckNgtvPsSttus 3 "NotAvailable" 2 "ErrorIndicator" 1 "OnNegativeSideOfNeutral" 0 "NotOnNegativeSideOfNeutral" ;
VAL_ 2365447166 Jystck3GrpYAxisNeutralPosStatus 3 "NotAvailable" 2 "ErrorIndicator" 1 "InNeutralPos" 0 "NotInNeutralPos" ;
VAL_ 2365447166 Jystck3GrpXAxsLvrRghtPstvPsStts 3 "NotAvailable" 2 "ErrorIndicator" 1 "OnPositiveSideOfNeutral" 0 "NotOnPositiveSideOfNeutral" ;
VAL_ 2365447166 Jystck3GrpXAxsLvrLftNgtvPsSttus 3 "NotAvailable" 2 "ErrorIndicator" 1 "OnNegativeSideOfNeutral" 0 "NotOnNegativeSideOfNeutral" ;
VAL_ 2365447166 Jystck3GrpXAxisNeutralPosStatus 3 "NotAvailable" 2 "ErrorIndicator" 1 "OnNegativeSideOfNeutral" 0 "NotOnNegativeSideOfNeutral" ;
VAL_ 2365447166 Jystck3ThtAxsCntrClckwsNgtvPsStt 3 "NotAvailable" 2 "ErrorIndicator" 1 "OnNegativeSideOfNeutral" 0 "NotOnNegativeSideOfNeutral" ;
VAL_ 2365446654 Jystck2GripXAxisDetentPosStatus 3 "NotAvailable" 2 "ErrorIndicator" 1 "InDetentPos" 0 "NotInDetentPos" ;
VAL_ 2365446654 Jystck2GripYAxisDetentPosStatus 3 "NotAvailable" 2 "ErrorIndicator" 1 "InDetentPos" 0 "NotInDetentPos" ;
VAL_ 2365446654 Jystck2ThetaAxisDetentPosStatus 3 "NotAvailable" 2 "ErrorIndicator" 1 "InDetentPos" 0 "NotInDetentPos" ;
VAL_ 2365446654 Jystck2ThtAxsClckwsPstvPsStatus 3 "NotAvailable" 2 "ErrorIndicator" 1 "OnPositiveSideOfNeutral" 0 "NotOnPositiveSideOfNeutral" ;
VAL_ 2365446654 Jystck2ThtaAxisNeutralPosStatus 3 "NotAvailable" 2 "ErrorIndicator" 1 "InNeutralPos" 0 "NotInNeutralPos" ;
VAL_ 2365446654 Jystck2GrpYAxsLvrFrwrdPstvPsStts 3 "NotAvailable" 2 "ErrorIndicator" 1 "OnPositiveSideOfNeutral" 0 "NotOnPositiveSideOfNeutral" ;
VAL_ 2365446654 Jystck2GrpYAxsLvrBckNgtvPsSttus 3 "NotAvailable" 2 "ErrorIndicator" 1 "OnNegativeSideOfNeutral" 0 "NotOnNegativeSideOfNeutral" ;
VAL_ 2365446654 Jystck2GrpYAxisNeutralPosStatus 3 "NotAvailable" 2 "ErrorIndicator" 1 "InNeutralPos" 0 "NotInNeutralPos" ;
VAL_ 2365446654 Jystck2GrpXAxsLvrRghtPstvPsStts 3 "NotAvailable" 2 "ErrorIndicator" 1 "OnPositiveSideOfNeutral" 0 "NotOnPositiveSideOfNeutral" ;
VAL_ 2365446654 Jystck2GrpXAxsLvrLftNgtvPsSttus 3 "NotAvailable" 2 "ErrorIndicator" 1 "OnNegativeSideOfNeutral" 0 "NotOnNegativeSideOfNeutral" ;
VAL_ 2365446654 Jystck2GrpXAxisNeutralPosStatus 3 "NotAvailable" 2 "ErrorIndicator" 1 "OnNegativeSideOfNeutral" 0 "NotOnNegativeSideOfNeutral" ;
VAL_ 2365446654 Jystck2ThtAxsCntrClckwsNgtvPsStt 3 "NotAvailable" 2 "ErrorIndicator" 1 "OnNegativeSideOfNeutral" 0 "NotOnNegativeSideOfNeutral" ;
VAL_ 2365446142 Jystck1GripXAxisDetentPosStatus 3 "NotAvailable" 2 "ErrorIndicator" 1 "InDetentPos" 0 "NotInDetentPos" ;
VAL_ 2365446142 Jystck1GripYAxisDetentPosStatus 3 "NotAvailable" 2 "ErrorIndicator" 1 "InDetentPos" 0 "NotInDetentPos" ;
VAL_ 2365446142 Jystck1ThetaAxisDetentPosStatus 3 "NotAvailable" 2 "ErrorIndicator" 1 "InDetentPos" 0 "NotInDetentPos" ;
VAL_ 2365446142 Jystck1ThtAxsClckwsPstvPsStatus 3 "NotAvailable" 2 "ErrorIndicator" 1 "OnPositiveSideOfNeutral" 0 "NotOnPositiveSideOfNeutral" ;
VAL_ 2365446142 Jystck1ThtaAxisNeutralPosStatus 3 "NotAvailable" 2 "ErrorIndicator" 1 "InNeutralPos" 0 "NotInNeutralPos" ;
VAL_ 2365446142 Jystck1GrpYAxsLvrFrwrdPstvPsStts 3 "NotAvailable" 2 "ErrorIndicator" 1 "OnPositiveSideOfNeutral" 0 "NotOnPositiveSideOfNeutral" ;
VAL_ 2365446142 Jystck1GrpYAxsLvrBckNgtvPsSttus 3 "NotAvailable" 2 "ErrorIndicator" 1 "OnNegativeSideOfNeutral" 0 "NotOnNegativeSideOfNeutral" ;
VAL_ 2365446142 Jystck1GrpYAxisNeutralPosStatus 3 "NotAvailable" 2 "ErrorIndicator" 1 "InNeutralPos" 0 "NotInNeutralPos" ;
VAL_ 2365446142 Jystck1GrpXAxsLvrRghtPstvPsStts 3 "NotAvailable" 2 "ErrorIndicator" 1 "OnPositiveSideOfNeutral" 0 "NotOnPositiveSideOfNeutral" ;
VAL_ 2365446142 Jystck1GrpXAxsLvrLftNgtvPsSttus 3 "NotAvailable" 2 "ErrorIndicator" 1 "OnNegativeSideOfNeutral" 0 "NotOnNegativeSideOfNeutral" ;
VAL_ 2365446142 Jystck1GrpXAxisNeutralPosStatus 3 "NotAvailable" 2 "ErrorIndicator" 1 "InNeutralPos" 0 "NotInNeutralPos" ;
VAL_ 2365446142 Jystck1ThtAxsCntrClckwsNgtvPsStt 3 "NotAvailable" 2 "ErrorIndicator" 1 "OnNegativeSideOfNeutral" 0 "NotOnNegativeSideOfNeutral" ;
VAL_ 2566810366 FuelPumpPrimerStatus 3 "Unavailable" 2 "Error" 1 "On" 0 "Off" ;
VAL_ 2566810366 EngWasteOilReservoirLevel 4 "RepresentsCompletelyFull" ;
VAL_ 2566810366 EngVentilationStatus 7 "NotAvailableNotInstalle" 6 "NtAblTDtrmnIfSufficientlyVented" 5 "ReservedForSAEAssignment" 3 "CurrentlyVenting" 2 "VentilationDelay" 1 "VentilationNeeded" 0 "SufficientlyVented" ;
VAL_ 2566810366 EngOilPrimingState 3 "NotAvailableNotInstalled" 2 "UnblTDtrmnIfSffcentlyLubricated" 1 "SufficientlyLubricated" 0 "NotSufficientlyLubricated" ;
VAL_ 2566810366 EngOilPrimingPumpSwitch 3 "NotAvailableNotInstalled" 2 "Error" 1 "On" 0 "Off" ;
VAL_ 2566810366 EngOilPreHeatedState 3 "NotAvailableNotInstalled" 2 "UnblTDtrmnIfEngOlIsPrhtdSffcntl" 1 "SufficientlyPreheated" 0 "NotSufficientlyPreheated" ;
VAL_ 2566810366 EngCoolantPreheatedState 3 "NotAvailableNotInstalled" 2 "UnblTDtrmnEngClntPrhtdSffcently" 1 "SufficientlyPreheated" 0 "NotSufficientlyPreheated" ;
VAL_ 2633929726 TurningGearEngaged 1 "TurningGearIsEngaged" 0 "TurningGearIsNotEngaged" 3 "NotAvailable" 2 "Error" ;
VAL_ 2633929726 SafetyWireStatus 3 "NotAvailable" 2 "Error" 1 "SafetyWireHasBeenActivated" 0 "SafetyWireHasNotBeenActivated" ;
VAL_ 2566772222 EngVrableGeometryTurbo1CtrlMode 3 "notAvailable" 2 "SAEReserved" 1 "closedLoop" 0 "openLoop" ;
VAL_ 2566772222 EngVrblGmtryTrbArCtrlShtffValve 3 "NotAvailable" 2 "Reserved" 1 "VGTAirCtrlShutoffValveIsOn" 0 "VGTAirCtrlShutoffValveIsOff" ;
VAL_ 2633940734 EngRotationDirection 3 "NotAvailable" 2 "Reserved" 1 "ClockWise" 0 "CounterClockWise" ;
VAL_ 2633940734 EngIntakeManifoldPressCtrlMode 3 "NotAvailable" 2 "SAEReserved" 1 "ClosedLoop" 0 "OpenLoop" ;
VAL_ 2566840318 Aftertreatment2IntakeDewPoint 3 "NotAvailable" 2 "Error" 1 "ExceededDewPoint" 0 "NotExceededDewPoint" ;
VAL_ 2566840318 Aftertreatment2ExhaustDewPoint 3 "NotAvailable" 2 "Error" 1 "ExceededDewPoint" 0 "NotExceededDewPoint" ;
VAL_ 2566840318 Aftertreatment1IntakeDewPoint 3 "NotAvailable" 2 "Error" 1 "ExceededDewPoint" 0 "NotExceededDewPoint" ;
VAL_ 2566840318 Aftertreatment1ExhaustDewPoint 3 "NotAvailable" 2 "Error" 1 "ExceededDewPoint" 0 "NotExceededDewPoint" ;
VAL_ 2566840318 EstEngPrsticLossesPercentTorque 251 "LossesAreIncludedInSPN514" ;
VAL_ 2364539902 SCRThermalManagementActive 3 "DontCare" 2 "Reserved" 1 "SCRThermalManagementIsActive" 0 "SCRThermalManagementIsNotActive" ;
VAL_ 2364539902 MmntryEngMaxPowerEnableFeedback 3 "dontCare" 2 "reserved" 1 "supported" 0 "disabled" ;
VAL_ 2364539902 DPFThermalManagementActive 3 "DontCare" 2 "Reserved" 1 "DPFThermalManagementIsActive" 0 "DPFThermalManagementIsNotActive" ;
VAL_ 2364539902 VhclAccelerationRateLimitStatus 3 "NotAvailable" 2 "Reserved" 1 "LimitActive" 0 "LimitNotActive" ;
VAL_ 2364539902 AccelPedal2LowIdleSwitch 3 "NotAvailable" 2 "Error" 1 "AccelPedal2InLowIdleCondition" 0 "AcclPedal2NotInLowIdleCondition" ;
VAL_ 2364539902 RoadSpeedLimitStatus 3 "NotAvailable" 2 "Error" 1 "NotActive" 0 "Active" ;
VAL_ 2364539902 AccelPedalKickdownSwitch 3 "NotAvailable" 2 "Error" 1 "KickdownActive" 0 "KickdownPassive" ;
VAL_ 2364539902 AccelPedal1LowIdleSwitch 3 "NotAvailable" 2 "Error" 1 "AccelPedal1InLowIdleCondition" 0 "AcclPedal1NotInLowIdleCondition" ;
VAL_ 2364540158 ActlEngPrcntTrqueHighResolution 8 "1111NotAvailable" 7 "0875" 1 "0125" 0 "0000" ;
VAL_ 2364540158 EngStarterMode 15 "notAvailable" 14 "error" 12 "starterInhibitedReasonUnknown" 9 "1011Reserved" 8 "strtrInhbtdDueToStarterOvertemp" 7 "strtrInhbtdDToActiveImmobilizer" 6 "strtrInhbtdDTDrvlnEnggdOthrTrns" 5 "strtrInhbtdDTEngNtReadyForStart" 4 "strtrInhbtdDToEngAlreadyRunning" 3 "strtFnshdStrtrNtActvAftrHvngBnA" 2 "starterActiveGearEngaged" 1 "starterActiveGearNotEngaged" 0 "startNotRqed" ;
VAL_ 2364540158 EngTorqueMode 15 "Not available" 11 "Remote accelerator" 10 "Braking system" 9 "High speed governor" 8 "Torque limiting" 7 "ABS control" 6 "Transmission control" 5 "ASR control" 4 "Road speed governor" 3 "PTO governor" 2 "Cruise control" 1 "Accelerator pedal/operator selec" 0 "Low idle governor/no request (de" ;
VAL_ 2566767870 BrakeTempWarning 3 "notAvailable" 2 "Reserved" 1 "Active" 0 "NotActive" ;
VAL_ 2566767870 PrkngBrkeActuatorFullyActivated 3 "NotAvailable" 2 "Error" 1 "PrkngBrkeActuatorFullyActivated" 0 "PrkngBrkActtorNotFullyActivated" ;
VAL_ 2566767870 XBRActiveCtrlMode 15 "NotAvailable" 4 "1110ReservedForSAEAssignment" 3 "MxMdOfXBRAcclrtnCtrlBngExecuted" 2 "AddtnMdOfXBRAcclrtnCtrlBngExctd" 1 "DrvrsBrkDmndBngExctdNExtlBrkDmn" 0 "NoBrakeDemandBeingExecuted" ;
VAL_ 2566767870 XBRSystemState 3 "NotAvailable" 2 "NoExtlBrakeDemandWillBeAccepted" 1 "OnlyExtlBrkDmndOfHghstXBRPrrtyW" 0 "AnyExtlBrkeDemandWillBeAccepted" ;
VAL_ 2566767870 FoundationBrakeUse 3 "NotAvailable" 2 "Reserved" 1 "FoundationBrakesInUse" 0 "FoundationBrakesNotInUse" ;
VAL_ 2566767870 HillHolderMode 7 "NotAvailable" 6 "HillHolderNotFunctional" 3 "101Reserved" 2 "ActvBtWllChngTInctvInAShortTime" 1 "Active" 0 "Inactive" ;
VAL_ 2566767870 HaltBrakeMode 7 "NotAvailable" 6 "Reserved" 3 "101NotDefined" 2 "ActiveButNotFunctioningProperly" 1 "Active" 0 "Inactive" ;
VAL_ 2565865982 EngAuxShutdownSwitch 3 "NotAvailable" 2 "Error" 1 "On" 0 "Off" ;
VAL_ 2565865982 TrctrMntdTrilerABSWarningSignal 3 "TakeNoAction" 2 "Reserved" 1 "On" 0 "Off" ;
VAL_ 2565865982 TrailerABSStatus 3 "NotAvailableOrNotSupported" 2 "Reserved" 1 "TrailerABSActive" 0 "InformationAvailableButNotActive" ;
VAL_ 2565865982 HaltBrakeSwitch 3 "NotAvailable" 2 "Error" 1 "HaltBrakeSwitchActive" 0 "HaltBrakeSwitchPassive" ;
VAL_ 2565865982 ATC_ASRInformationSignal 3 "TakeNoAction" 2 "Reserved" 1 "On" 0 "Off" ;
VAL_ 2565865982 ABS_EBSAmberWarningSignal 3 "TakeNoAction" 2 "Reserved" 1 "On" 0 "Off" ;
VAL_ 2565865982 EBSRedWarningSignal 3 "TakeNoAction" 2 "Reserved" 1 "On" 0 "Off" ;
VAL_ 2565865982 ABSFullyOperational 3 "NotAvailable" 2 "Reserved" 1 "FullyOperational" 0 "NotFullyOperational" ;
VAL_ 2565865982 RemoteAccelEnableSwitch 3 "NotAvailable" 2 "Error" 1 "On" 0 "Off" ;
VAL_ 2565865982 EngDerateSwitch 3 "NotAvailable" 2 "Error" 1 "On" 0 "Off" ;
VAL_ 2565865982 AccelInterlockSwitch 3 "NotAvailable" 2 "Error" 1 "On" 0 "Off" ;
VAL_ 2565865982 TractionCtrlOverrideSwitch 3 "NotAvailableNotInstalled" 2 "Error" 1 "On" 0 "Off" ;
VAL_ 2565865982 ASRHillHolderSwitch 3 "NotAvailable" 2 "Error" 1 "ASRHillHolderSwitchActive" 0 "ASRHillHolderSwitchPassive" ;
VAL_ 2565865982 ASROffroadSwitch 2 "Error" 1 "ASROffroadSwitchActive" 0 "ASROffroadSwitchPassive" 3 "NotAvailable" ;
VAL_ 2565865982 ABSOffroadSwitch 3 "NotAvailable" 2 "Error" 1 "ABSOffroadSwitchActive" 0 "ABSOffroadSwitchPassive" ;
VAL_ 2565865982 EBSBrakeSwitch 3 "NotAvailable" 2 "Error" 1 "BrakePedalIsBeingPressed" 0 "BrakePedalIsNotBeingPressed" ;
VAL_ 2565865982 AntiLockBrakingActive 3 "NotAvailable" 2 "Reserved" 1 "ABSActive" 0 "ABSPassiveButInstalled" ;
VAL_ 2565865982 ASRBrakeCtrlActive 3 "NotAvailable" 2 "Reserved" 1 "ASRBrakeCtrlActive" 0 "ASRBrakeCtrlPassiveButInstalled" ;
VAL_ 2565865982 ASREngCtrlActive 3 "NotAvailable" 2 "Reserved" 1 "ASREngCtrlActive" 0 "ASREngCtrlPassiveButInstalled" ;
VAL_ 2565867262 RearAxleGroupEngagementStatus 3 "notAvailable" 2 "error" 1 "rearAxleGroupEngaged" 0 "rearAxleGroupDisengaged" ;
VAL_ 2565867262 FrontAxleGroupEngagementStatus 3 "notAvailable" 2 "error" 1 "frontAxleGroupEngaged" 0 "frontAxleGroupDisengaged" ;
VAL_ 2565867262 DiffLockStateCentralRear 3 "NotAvailable" 2 "Error" 1 "DiffLockEngaged" 0 "DiffLockDisengaged" ;
VAL_ 2565867262 DiffLockStateCentralFront 3 "NotAvailable" 2 "Error" 1 "DiffLockEngaged" 0 "DiffLockDisengaged" ;
VAL_ 2565867262 DiffLockStateCentral 3 "NotAvailable" 2 "Error" 1 "DiffLockEngaged" 0 "DiffLockDisengaged" ;
VAL_ 2565867262 DiffLockStateRearAxle2 3 "NotAvailable" 2 "Error" 1 "DiffLockEngaged" 0 "DiffLockDisengaged" ;
VAL_ 2565867262 DiffLockStateRearAxle1 3 "NotAvailable" 2 "Error" 1 "DiffLockEngaged" 0 "DiffLockDisengaged" ;
VAL_ 2565867262 DiffLockStateFrontAxle2 3 "NotAvailable" 2 "Error" 1 "DiffLockEngaged" 0 "DiffLockDisengaged" ;
VAL_ 2565867262 DiffLockStateFrontAxle1 3 "NotAvailable" 2 "Error" 1 "DiffLockEngaged" 0 "DiffLockDisengaged" ;
VAL_ 2566768382 EngStartEnableDevice2Config 15 "NotAvailable" 5 "1110Reserved" 4 "ElctricIntakeAirHeaterInstalled" 3 "EtherInjectionInstalled" 2 "FuelledStartInstalled" 1 "GlowPlugsInstalled" 0 "NoStartEnableDevice2Installed" ;
VAL_ 2566768382 EngStartEnableDevice1Config 15 "NotAvailable" 5 "1110Reserved" 4 "ElctricIntakeAirHeaterInstalled" 3 "EtherInjectionInstalled" 2 "FuelledStartInstalled" 1 "GlowPlugsInstalled" 0 "NoStartEnableDevice1Installed" ;
VAL_ 2566768382 EngStartEnableDevice2 3 "NotAvailable" 2 "Reserved" 1 "StartEnableON" 0 "StartEnableOFF" ;
VAL_ 2566768382 EngStartEnableDevice1 3 "NotAvailable" 2 "Reserved" 1 "StartEnableON" 0 "StartEnableOFF" ;
VAL_ 2566771966 TransOilLevelRq 3 "DontCare_TakeNoAction" 2 "Reserved" 1 "TransOilLevelReadingDesired" 0 "NoTransOilLevelReadingDesired" ;
VAL_ 2566771966 FifthWheelReleaseCtrl 3 "NotAvailable" 2 "Error" 1 "CplrUnlckdTrlrCnBUnhtchdHitched" 0 "CouplerLocked" ;
VAL_ 2566771966 FfthWhlRlaseCtrlSecurityLockout 3 "NotAvailable" 2 "Error" 1 "FifthWheelReleaseEnabled" 0 "FifthWheelReleaseDisabled" ;
VAL_ 2566771966 TransferCaseSelectorSwitch 7 "NotAvailable" 5 "ReservedForSAEAssignment" 4 "4WheelLow" 0 "2WheelHigh" 6 "ErrorIndicator" 3 "2WheelLow" 2 "Neutral" 1 "4WheelHigh" ;
